VERSION ""

NS_ :

BS_:

BU_: BCM BSM DIAG_TEST ECM EPS IPC MTA ORC PAM

BO_ 1765 XcpSlave: 8 EPS
 SG_ XcpSlave : 7|64@0+ (1,0) [0|4294967295] ""  DIAG_TEST

BO_ 1685 XcpMaster: 8 DIAG_TEST
 SG_ XcpMaster : 7|64@0+ (1,0) [0|4294967295] ""  EPS

BO_ 2033 GliwaSlave: 8 EPS
 SG_ GliwaSlave : 7|64@0+ (1,0) [0|4294967295] ""  DIAG_TEST

BO_ 2032 GliwaMaster: 8 DIAG_TEST
 SG_ GliwaMaster : 7|64@0+ (1,0) [0|4294967295] ""  EPS

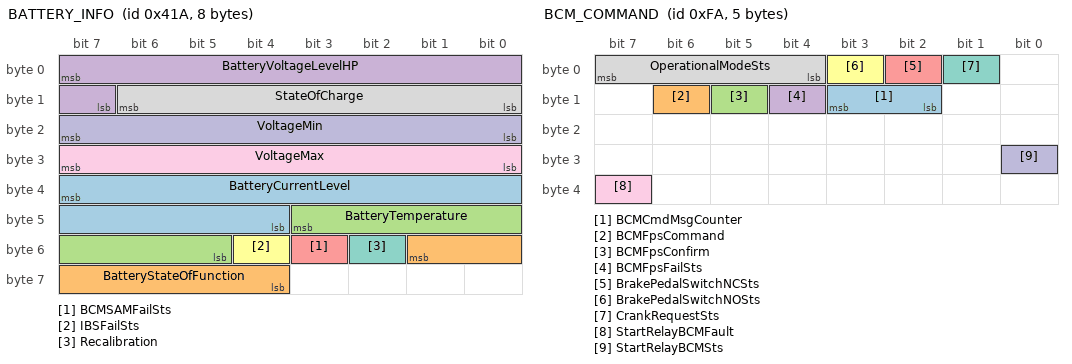
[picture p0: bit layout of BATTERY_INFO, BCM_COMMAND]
BO_ 1050 BATTERY_INFO: 8 BCM
 SG_ BatteryCurrentLevel : 39|12@0+ (0.1,-250) [0|0] "A"  ECM
 SG_ BatteryStateOfFunction : 49|6@0+ (0.09375,6) [6|11.90625] "V"  ECM
 SG_ BatteryTemperature : 43|7@0+ (1,-30) [0|0] "°C"  ECM
 SG_ BatteryVoltageLevelHP : 7|9@0+ (0.025,4) [0|0] "Volt"  ECM
 SG_ BCMSAMFailSts : 51|1@0+ (1,0) [0|0] "-"  ECM
 SG_ IBSFailSts : 52|1@0+ (1,0) [0|0] "-"  ECM
 SG_ Recalibration : 50|1@0+ (1,0) [0|1] ""  ECM
 SG_ StateOfCharge : 14|7@0+ (1,0) [0|0] "%"  ECM
 SG_ VoltageMax : 31|8@0+ (0.025,10.6) [0|0] "Volt"  ECM
 SG_ VoltageMin : 23|8@0+ (0.025,10.6) [0|0] "Volt"  ECM

BO_ 250 BCM_COMMAND: 5 BCM
 SG_ BCMCmdMsgCounter : 11|2@0+ (1,0) [0|3] "-"  BSM,ECM,MTA
 SG_ BCMFpsCommand : 14|1@0+ (1,0) [0|1] "-"  ECM
 SG_ BCMFpsConfirm : 13|1@0+ (1,0) [0|1] "-"  ECM
 SG_ BCMFpsFailSts : 12|1@0+ (1,0) [0|1] "-"  ECM
 SG_ BrakePedalSwitchNCSts : 2|1@0+ (1,0) [0|1] "-"  BSM,ECM,MTA
 SG_ BrakePedalSwitchNOSts : 3|1@0+ (1,0) [0|1] "-"  BSM,ECM,MTA
 SG_ CrankRequestSts : 1|1@0+ (1,0) [0|1] "-"  ECM
 SG_ OperationalModeSts : 7|4@0+ (1,0) [0|15] ""  BSM,ECM,EPS,IPC,MTA,PAM
 SG_ StartRelayBCMFault : 39|1@0+ (1,0) [0|1] ""  ECM
 SG_ StartRelayBCMSts : 24|1@0+ (1,0) [0|1] ""  ECM

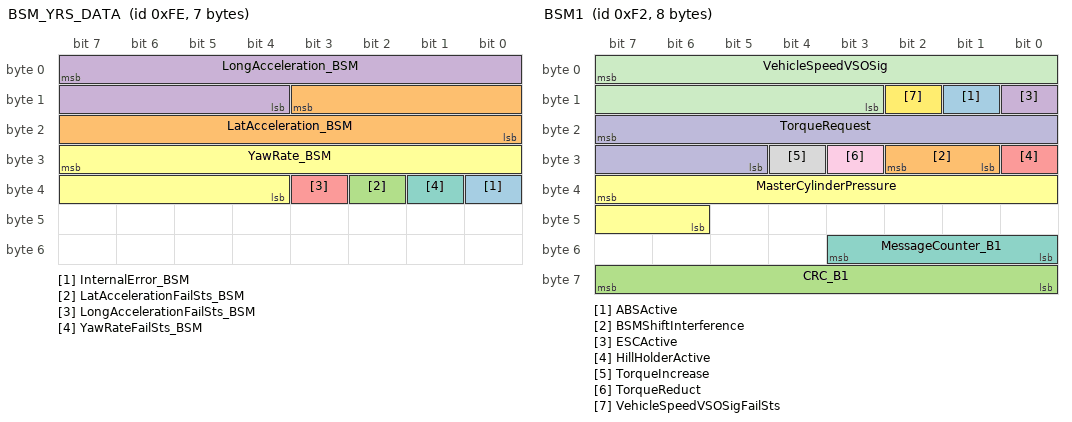
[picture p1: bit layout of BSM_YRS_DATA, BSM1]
BO_ 254 BSM_YRS_DATA: 7 BSM
 SG_ InternalError_BSM : 32|1@0+ (1,0) [0|1] "-" Vector__XXX
 SG_ LatAcceleration_BSM : 11|12@0+ (0.02,-40.96) [-40.96|40.92] "m/s^2"  MTA
 SG_ LatAccelerationFailSts_BSM : 34|1@0+ (1,0) [0|3] "-"  MTA
 SG_ LongAcceleration_BSM : 7|12@0+ (0.02,-40.96) [-40.96|40.92] "m/s^2"  MTA
 SG_ LongAccelerationFailSts_BSM : 35|1@0+ (1,0) [0|3] "-"  MTA
 SG_ YawRate_BSM : 31|12@0+ (0.08,-163.84) [-163.84|163.68] "deg/s" Vector__XXX
 SG_ YawRateFailSts_BSM : 33|1@0+ (1,0) [0|3] "-" Vector__XXX

BO_ 242 BSM1: 8 BSM
 SG_ ABSActive : 9|1@0+ (1,0) [0|1] ""  MTA
 SG_ BSMShiftInterference : 26|2@0+ (1,0) [0|1] ""  MTA
 SG_ CRC_B1 : 63|8@0+ (1,0) [0|255] ""  ECM,EPS
 SG_ ESCActive : 8|1@0+ (1,0) [0|1] ""  MTA
 SG_ HillHolderActive : 24|1@0+ (1,0) [0|0] ""  BCM,ECM,MTA
 SG_ MasterCylinderPressure : 39|10@0+ (0.25,0) [0|200] "bar"  ECM,MTA
 SG_ MessageCounter_B1 : 51|4@0+ (1,0) [0|15] ""  ECM,EPS
 SG_ TorqueIncrease : 28|1@0+ (1,0) [0|1] ""  ECM
 SG_ TorqueReduct : 27|1@0+ (1,0) [0|1] ""  ECM
 SG_ TorqueRequest : 23|11@0+ (1,-500) [-500|1546] ""  ECM
 SG_ VehicleSpeedVSOSig : 7|13@0+ (0.0625,0) [0|511.9375] "Km/h"  BCM,ECM,EPS,IPC,MTA,ORC,PAM
 SG_ VehicleSpeedVSOSigFailSts : 10|1@0+ (1,0) [0|1] ""  BCM,ECM,EPS,IPC,MTA,ORC,PAM

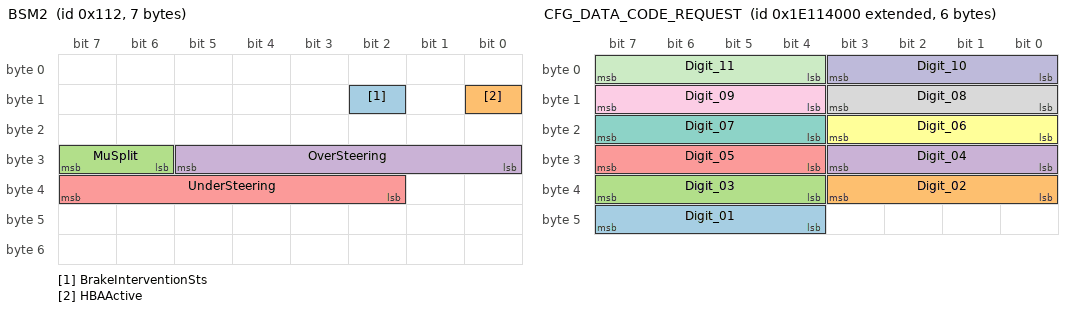
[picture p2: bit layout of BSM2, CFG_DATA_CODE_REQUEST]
BO_ 274 BSM2: 7 BSM
 SG_ BrakeInterventionSts : 10|1@0+ (1,0) [0|1] ""  MTA
 SG_ HBAActive : 8|1@0+ (1,0) [0|0] "" Vector__XXX
 SG_ MuSplit : 31|2@0+ (1,0) [0|1] "" Vector__XXX
 SG_ OverSteering : 29|6@0+ (2,0) [0|62] "%" Vector__XXX
 SG_ UnderSteering : 39|6@0+ (2,0) [0|62] "%" Vector__XXX

BO_ 2651930624 CFG_DATA_CODE_REQUEST: 6 BCM
 SG_ Digit_01 : 47|4@0+ (1,0) [0|15] ""  BSM,ECM,EPS,IPC,MTA,ORC,PAM
 SG_ Digit_02 : 35|4@0+ (1,0) [0|15] ""  BSM,ECM,EPS,IPC,MTA,ORC,PAM
 SG_ Digit_03 : 39|4@0+ (1,0) [0|15] ""  BSM,ECM,EPS,IPC,MTA,ORC,PAM
 SG_ Digit_04 : 27|4@0+ (1,0) [0|15] ""  BSM,ECM,EPS,IPC,MTA,ORC,PAM
 SG_ Digit_05 : 31|4@0+ (1,0) [0|15] ""  BSM,ECM,EPS,IPC,MTA,ORC,PAM
 SG_ Digit_06 : 19|4@0+ (1,0) [0|15] ""  BSM,ECM,EPS,IPC,MTA,ORC,PAM
 SG_ Digit_07 : 23|4@0+ (1,0) [0|15] ""  BSM,ECM,EPS,IPC,MTA,ORC,PAM
 SG_ Digit_08 : 11|4@0+ (1,0) [0|15] ""  BSM,ECM,EPS,IPC,MTA,ORC,PAM
 SG_ Digit_09 : 15|4@0+ (1,0) [0|15] ""  BSM,ECM,EPS,IPC,MTA,ORC,PAM
 SG_ Digit_10 : 3|4@0+ (1,0) [0|15] ""  BSM,ECM,EPS,IPC,MTA,ORC,PAM
 SG_ Digit_11 : 7|4@0+ (1,0) [0|15] ""  BSM,ECM,EPS,IPC,MTA,ORC,PAM

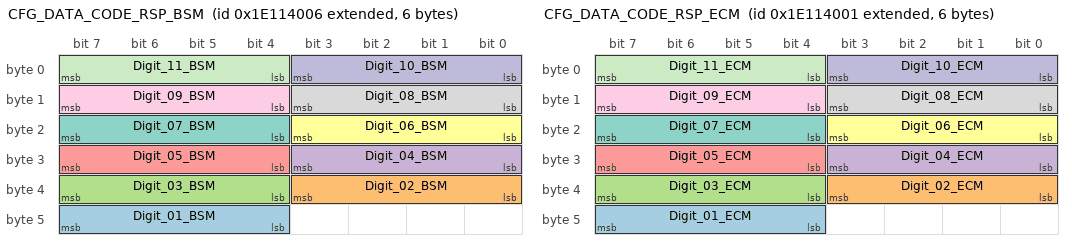
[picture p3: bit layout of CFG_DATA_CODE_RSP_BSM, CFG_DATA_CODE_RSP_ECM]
BO_ 2651930630 CFG_DATA_CODE_RSP_BSM: 6 BSM
 SG_ Digit_01_BSM : 47|4@0+ (1,0) [0|15] "-"  BCM
 SG_ Digit_02_BSM : 35|4@0+ (1,0) [0|15] "-"  BCM
 SG_ Digit_03_BSM : 39|4@0+ (1,0) [0|15] "-"  BCM
 SG_ Digit_04_BSM : 27|4@0+ (1,0) [0|15] "-"  BCM
 SG_ Digit_05_BSM : 31|4@0+ (1,0) [0|15] "-"  BCM
 SG_ Digit_06_BSM : 19|4@0+ (1,0) [0|15] "-"  BCM
 SG_ Digit_07_BSM : 23|4@0+ (1,0) [0|15] "-"  BCM
 SG_ Digit_08_BSM : 11|4@0+ (1,0) [0|15] "-"  BCM
 SG_ Digit_09_BSM : 15|4@0+ (1,0) [0|15] "-"  BCM
 SG_ Digit_10_BSM : 3|4@0+ (1,0) [0|15] "-"  BCM
 SG_ Digit_11_BSM : 7|4@0+ (1,0) [0|15] "-"  BCM

BO_ 2651930625 CFG_DATA_CODE_RSP_ECM: 6 ECM
 SG_ Digit_01_ECM : 47|4@0+ (1,0) [0|15] "-"  BCM
 SG_ Digit_02_ECM : 35|4@0+ (1,0) [0|15] "-"  BCM
 SG_ Digit_03_ECM : 39|4@0+ (1,0) [0|15] "-"  BCM
 SG_ Digit_04_ECM : 27|4@0+ (1,0) [0|15] "-"  BCM
 SG_ Digit_05_ECM : 31|4@0+ (1,0) [0|15] "-"  BCM
 SG_ Digit_06_ECM : 19|4@0+ (1,0) [0|15] "-"  BCM
 SG_ Digit_07_ECM : 23|4@0+ (1,0) [0|15] "-"  BCM
 SG_ Digit_08_ECM : 11|4@0+ (1,0) [0|15] "-"  BCM
 SG_ Digit_09_ECM : 15|4@0+ (1,0) [0|15] "-"  BCM
 SG_ Digit_10_ECM : 3|4@0+ (1,0) [0|15] "-"  BCM
 SG_ Digit_11_ECM : 7|4@0+ (1,0) [0|15] "-"  BCM

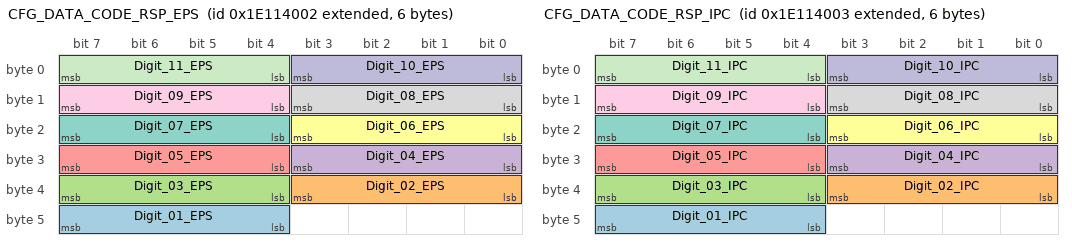
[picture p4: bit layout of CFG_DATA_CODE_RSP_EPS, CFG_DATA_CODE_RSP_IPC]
BO_ 2651930626 CFG_DATA_CODE_RSP_EPS: 6 EPS
 SG_ Digit_01_EPS : 47|4@0+ (1,0) [0|15] "-"  BCM
 SG_ Digit_02_EPS : 35|4@0+ (1,0) [0|15] "-"  BCM
 SG_ Digit_03_EPS : 39|4@0+ (1,0) [0|15] "-"  BCM
 SG_ Digit_04_EPS : 27|4@0+ (1,0) [0|15] "-"  BCM
 SG_ Digit_05_EPS : 31|4@0+ (1,0) [0|15] "-"  BCM
 SG_ Digit_06_EPS : 19|4@0+ (1,0) [0|15] "-"  BCM
 SG_ Digit_07_EPS : 23|4@0+ (1,0) [0|15] "-"  BCM
 SG_ Digit_08_EPS : 11|4@0+ (1,0) [0|15] "-"  BCM
 SG_ Digit_09_EPS : 15|4@0+ (1,0) [0|15] "-"  BCM
 SG_ Digit_10_EPS : 3|4@0+ (1,0) [0|15] "-"  BCM
 SG_ Digit_11_EPS : 7|4@0+ (1,0) [0|15] "-"  BCM

BO_ 2651930627 CFG_DATA_CODE_RSP_IPC: 6 IPC
 SG_ Digit_01_IPC : 47|4@0+ (1,0) [0|15] "-"  BCM
 SG_ Digit_02_IPC : 35|4@0+ (1,0) [0|15] "-"  BCM
 SG_ Digit_03_IPC : 39|4@0+ (1,0) [0|15] "-"  BCM
 SG_ Digit_04_IPC : 27|4@0+ (1,0) [0|15] "-"  BCM
 SG_ Digit_05_IPC : 31|4@0+ (1,0) [0|15] "-"  BCM
 SG_ Digit_06_IPC : 19|4@0+ (1,0) [0|15] "-"  BCM
 SG_ Digit_07_IPC : 23|4@0+ (1,0) [0|15] "-"  BCM
 SG_ Digit_08_IPC : 11|4@0+ (1,0) [0|15] "-"  BCM
 SG_ Digit_09_IPC : 15|4@0+ (1,0) [0|15] "-"  BCM
 SG_ Digit_10_IPC : 3|4@0+ (1,0) [0|15] "-"  BCM
 SG_ Digit_11_IPC : 7|4@0+ (1,0) [0|15] "-"  BCM

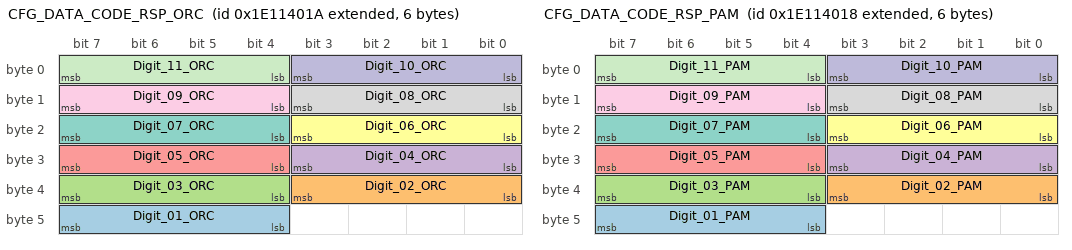
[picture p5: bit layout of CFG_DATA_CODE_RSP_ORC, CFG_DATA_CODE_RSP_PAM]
BO_ 2651930650 CFG_DATA_CODE_RSP_ORC: 6 ORC
 SG_ Digit_01_ORC : 47|4@0+ (1,0) [0|15] "-"  BCM
 SG_ Digit_02_ORC : 35|4@0+ (1,0) [0|15] "-"  BCM
 SG_ Digit_03_ORC : 39|4@0+ (1,0) [0|15] "-"  BCM
 SG_ Digit_04_ORC : 27|4@0+ (1,0) [0|15] "-"  BCM
 SG_ Digit_05_ORC : 31|4@0+ (1,0) [0|15] "-"  BCM
 SG_ Digit_06_ORC : 19|4@0+ (1,0) [0|15] "-"  BCM
 SG_ Digit_07_ORC : 23|4@0+ (1,0) [0|15] "-"  BCM
 SG_ Digit_08_ORC : 11|4@0+ (1,0) [0|15] "-"  BCM
 SG_ Digit_09_ORC : 15|4@0+ (1,0) [0|15] "-"  BCM
 SG_ Digit_10_ORC : 3|4@0+ (1,0) [0|15] "-"  BCM
 SG_ Digit_11_ORC : 7|4@0+ (1,0) [0|15] "-"  BCM

BO_ 2651930648 CFG_DATA_CODE_RSP_PAM: 6 PAM
 SG_ Digit_01_PAM : 47|4@0+ (1,0) [0|15] "-"  BCM
 SG_ Digit_02_PAM : 35|4@0+ (1,0) [0|15] "-"  BCM
 SG_ Digit_03_PAM : 39|4@0+ (1,0) [0|15] "-"  BCM
 SG_ Digit_04_PAM : 27|4@0+ (1,0) [0|15] "-"  BCM
 SG_ Digit_05_PAM : 31|4@0+ (1,0) [0|15] "-"  BCM
 SG_ Digit_06_PAM : 19|4@0+ (1,0) [0|15] "-"  BCM
 SG_ Digit_07_PAM : 23|4@0+ (1,0) [0|15] "-"  BCM
 SG_ Digit_08_PAM : 11|4@0+ (1,0) [0|15] "-"  BCM
 SG_ Digit_09_PAM : 15|4@0+ (1,0) [0|15] "-"  BCM
 SG_ Digit_10_PAM : 3|4@0+ (1,0) [0|15] "-"  BCM
 SG_ Digit_11_PAM : 7|4@0+ (1,0) [0|15] "-"  BCM

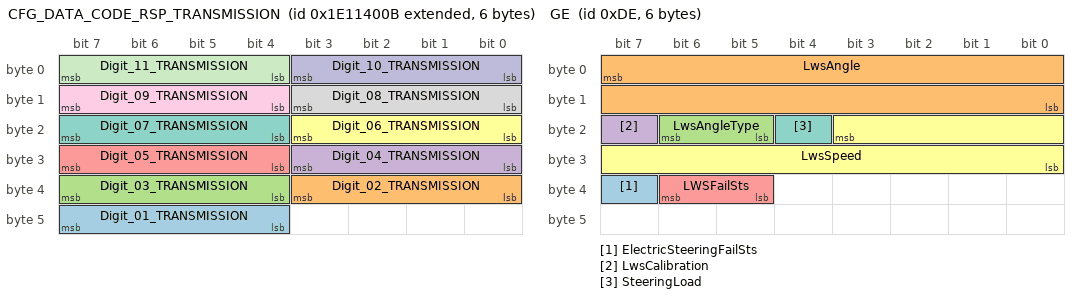
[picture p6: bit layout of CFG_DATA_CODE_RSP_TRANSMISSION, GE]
BO_ 2651930635 CFG_DATA_CODE_RSP_TRANSMISSION: 6 MTA
 SG_ Digit_01_TRANSMISSION : 47|4@0+ (1,0) [0|15] "-"  BCM
 SG_ Digit_02_TRANSMISSION : 35|4@0+ (1,0) [0|15] "-"  BCM
 SG_ Digit_03_TRANSMISSION : 39|4@0+ (1,0) [0|15] "-"  BCM
 SG_ Digit_04_TRANSMISSION : 27|4@0+ (1,0) [0|15] "-"  BCM
 SG_ Digit_05_TRANSMISSION : 31|4@0+ (1,0) [0|15] "-"  BCM
 SG_ Digit_06_TRANSMISSION : 19|4@0+ (1,0) [0|15] "-"  BCM
 SG_ Digit_07_TRANSMISSION : 23|4@0+ (1,0) [0|15] "-"  BCM
 SG_ Digit_08_TRANSMISSION : 11|4@0+ (1,0) [0|15] "-"  BCM
 SG_ Digit_09_TRANSMISSION : 15|4@0+ (1,0) [0|15] "-"  BCM
 SG_ Digit_10_TRANSMISSION : 3|4@0+ (1,0) [0|15] "-"  BCM
 SG_ Digit_11_TRANSMISSION : 7|4@0+ (1,0) [0|15] "-"  BCM

BO_ 2564440308 DIAGNOSTIC_REQUEST_BCM: 8 DIAG_TEST
 SG_ N_PDU : 7|64@0+ (1,0) [0|0] ""  BCM

BO_ 2564434164 DIAGNOSTIC_REQUEST_BSM: 8 DIAG_TEST
 SG_ N_PDU : 7|64@0+ (1,0) [0|0] ""  BSM

BO_ 2564428020 DIAGNOSTIC_REQUEST_ECM: 8 DIAG_TEST
 SG_ N_PDU : 7|64@0+ (1,0) [0|0] ""  ECM

BO_ 2564428017 DIAGNOSTIC_REQUEST_ECM_OBD: 8 DIAG_TEST
 SG_ N_PDU : 7|64@0+ (1,0) [0|0] ""  ECM

BO_ 2564436212 DIAGNOSTIC_REQUEST_EPS: 8 DIAG_TEST
 SG_ N_PDU : 7|64@0+ (1,0) [0|0] ""  EPS

BO_ 2564502513 DIAGNOSTIC_REQUEST_FUNC_OBD: 8 DIAG_TEST
 SG_ N_PDU : 7|64@0+ (1,0) [0|0] ""  ECM

BO_ 2564554484 DIAGNOSTIC_REQUEST_FUNCTIONAL: 8 DIAG_TEST
 SG_ N_PDU : 7|64@0+ (1,0) [0|0] ""  BCM,BSM,ECM,EPS,IPC,MTA,ORC,PAM

BO_ 2564448500 DIAGNOSTIC_REQUEST_IPC: 8 DIAG_TEST
 SG_ N_PDU : 7|64@0+ (1,0) [0|0] "-"  IPC

BO_ 2564473076 DIAGNOSTIC_REQUEST_ORC: 8 DIAG_TEST
 SG_ N_PDU : 7|64@0+ (1,0) [0|0] ""  ORC

BO_ 2564464884 DIAGNOSTIC_REQUEST_PAM: 8 DIAG_TEST
 SG_ N_PDU : 7|64@0+ (1,0) [0|0] ""  PAM

BO_ 2564430068 DIAGNOSTIC_REQUEST_TRANSMISSION: 8 DIAG_TEST
 SG_ N_PDU : 7|64@0+ (1,0) [0|0] ""  MTA

BO_ 2564486208 DIAGNOSTIC_RESPONSE_BCM: 8 BCM
 SG_ N_PDU : 7|64@0+ (1,0) [0|0] ""  DIAG_TEST

BO_ 2564486184 DIAGNOSTIC_RESPONSE_BSM: 8 BSM
 SG_ N_PDU : 7|64@0+ (1,0) [0|0] ""  DIAG_TEST

BO_ 2564486160 DIAGNOSTIC_RESPONSE_ECM: 8 ECM
 SG_ N_PDU : 7|64@0+ (1,0) [0|0] ""  DIAG_TEST

BO_ 2564485392 DIAGNOSTIC_RESPONSE_ECM_OBD: 8 ECM
 SG_ N_PDU : 7|64@0+ (1,0) [0|0] ""  DIAG_TEST

BO_ 2564486192 DIAGNOSTIC_RESPONSE_EPS: 8 EPS
 SG_ N_PDU : 7|64@0+ (1,0) [0|0] ""  DIAG_TEST

BO_ 2564486240 DIAGNOSTIC_RESPONSE_IPC: 8 IPC
 SG_ N_PDU : 7|64@0+ (1,0) [0|0] "-"  DIAG_TEST

BO_ 2564486336 DIAGNOSTIC_RESPONSE_ORC: 8 ORC
 SG_ N_PDU : 7|64@0+ (1,0) [0|0] ""  DIAG_TEST

BO_ 2564486304 DIAGNOSTIC_RESPONSE_PAM: 8 PAM
 SG_ N_PDU : 7|64@0+ (1,0) [0|0] ""  DIAG_TEST

BO_ 2564486168 DIAGNOSTIC_RESPONSE_TRANSMISSION: 8 MTA
 SG_ N_PDU : 7|64@0+ (1,0) [0|0] ""  DIAG_TEST

BO_ 222 GE: 6 EPS
 SG_ ElectricSteeringFailSts : 39|1@0+ (1,0) [0|1] ""  BCM,IPC
 SG_ LwsAngle : 7|16@0+ (0.1,-720) [-720|720] "°"  BSM
 SG_ LwsAngleType : 22|2@0+ (1,0) [0|1] "-"  BSM
 SG_ LwsCalibration : 23|1@0+ (1,0) [0|1] "-"  BSM
 SG_ LWSFailSts : 38|2@0+ (1,0) [0|3] "-"  BSM
 SG_ LwsSpeed : 19|12@0+ (1,-2000) [0|0] "°/s" Vector__XXX
 SG_ SteeringLoad : 20|1@0+ (1,0) [0|1] "-" Vector__XXX

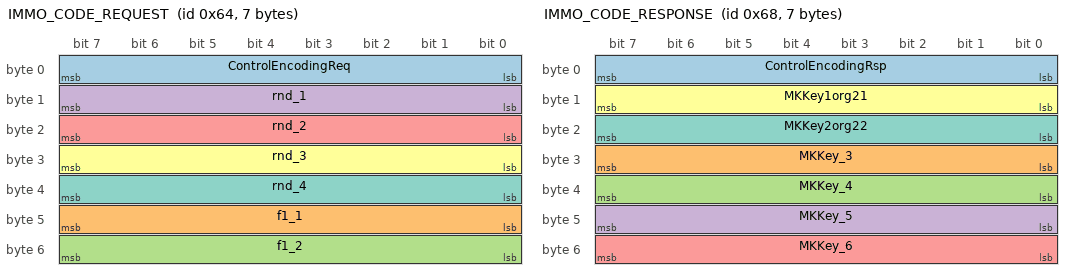
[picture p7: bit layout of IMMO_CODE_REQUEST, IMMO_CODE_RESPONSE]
BO_ 100 IMMO_CODE_REQUEST: 7 ECM
 SG_ ControlEncodingReq : 7|8@0+ (1,0) [0|255] "-"  BCM
 SG_ f1_1 : 47|8@0+ (1,0) [0|255] "-"  BCM
 SG_ f1_2 : 55|8@0+ (1,0) [0|255] "-"  BCM
 SG_ rnd_1 : 15|8@0+ (1,0) [0|255] "-"  BCM
 SG_ rnd_2 : 23|8@0+ (1,0) [0|255] "-"  BCM
 SG_ rnd_3 : 31|8@0+ (1,0) [0|255] "-"  BCM
 SG_ rnd_4 : 39|8@0+ (1,0) [0|255] "-"  BCM

BO_ 104 IMMO_CODE_RESPONSE: 7 BCM
 SG_ ControlEncodingRsp : 7|8@0+ (1,0) [0|255] "-"  ECM
 SG_ MKKey_3 : 31|8@0+ (1,0) [0|255] "-"  ECM
 SG_ MKKey_4 : 39|8@0+ (1,0) [0|255] "-"  ECM
 SG_ MKKey_5 : 47|8@0+ (1,0) [0|255] "-"  ECM
 SG_ MKKey_6 : 55|8@0+ (1,0) [0|255] "-"  ECM
 SG_ MKKey1org21 : 15|8@0+ (1,0) [0|255] "-"  ECM
 SG_ MKKey2org22 : 23|8@0+ (1,0) [0|255] "-"  ECM

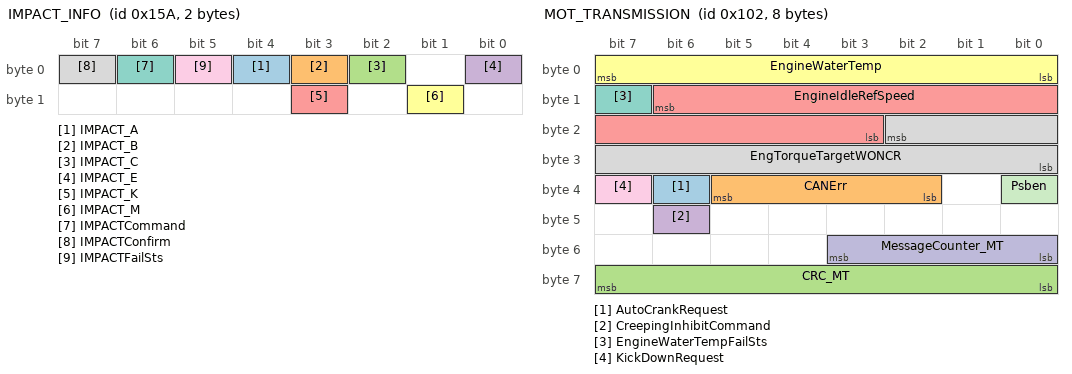
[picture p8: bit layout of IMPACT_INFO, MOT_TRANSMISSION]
BO_ 346 IMPACT_INFO: 2 ORC
 SG_ IMPACT_A : 4|1@0+ (1,0) [0|1] "" Vector__XXX
 SG_ IMPACT_B : 3|1@0+ (1,0) [0|1] "" Vector__XXX
 SG_ IMPACT_C : 2|1@0+ (1,0) [0|1] "" Vector__XXX
 SG_ IMPACT_E : 0|1@0+ (1,0) [0|1] "" Vector__XXX
 SG_ IMPACT_K : 11|1@0+ (1,0) [0|1] "" Vector__XXX
 SG_ IMPACT_M : 9|1@0+ (1,0) [0|1] "" Vector__XXX
 SG_ IMPACTCommand : 6|1@0+ (1,0) [0|1] ""  BCM
 SG_ IMPACTConfirm : 7|1@0+ (1,0) [0|1] ""  BCM
 SG_ IMPACTFailSts : 5|1@0+ (1,0) [0|1] ""  BCM

BO_ 258 MOT_TRANSMISSION: 8 ECM
 SG_ AutoCrankRequest : 38|1@0+ (1,0) [0|1] "-"  MTA
 SG_ CANErr : 37|4@0+ (1,0) [0|15] "-"  MTA
 SG_ CRC_MT : 63|8@0+ (1,0) [0|255] "-"  MTA
 SG_ CreepingInhibitCommand : 46|1@0+ (1,0) [0|1] ""  MTA
 SG_ EngineIdleRefSpeed : 14|12@0+ (1,0) [0|4094] "1/min"  MTA
 SG_ EngineWaterTemp : 7|8@0+ (1,-40) [-40|215] "°C"  BCM
 SG_ EngineWaterTempFailSts : 15|1@0+ (1,0) [0|1] "-"  BCM
 SG_ EngTorqueTargetWONCR : 18|11@0+ (1,-500) [-500|1546] "Nm"  MTA
 SG_ KickDownRequest : 39|1@0+ (1,0) [0|1] "-" Vector__XXX
 SG_ MessageCounter_MT : 51|4@0+ (1,0) [0|15] "-"  MTA
 SG_ Psben : 32|1@0+ (1,0) [0|1] "-" Vector__XXX

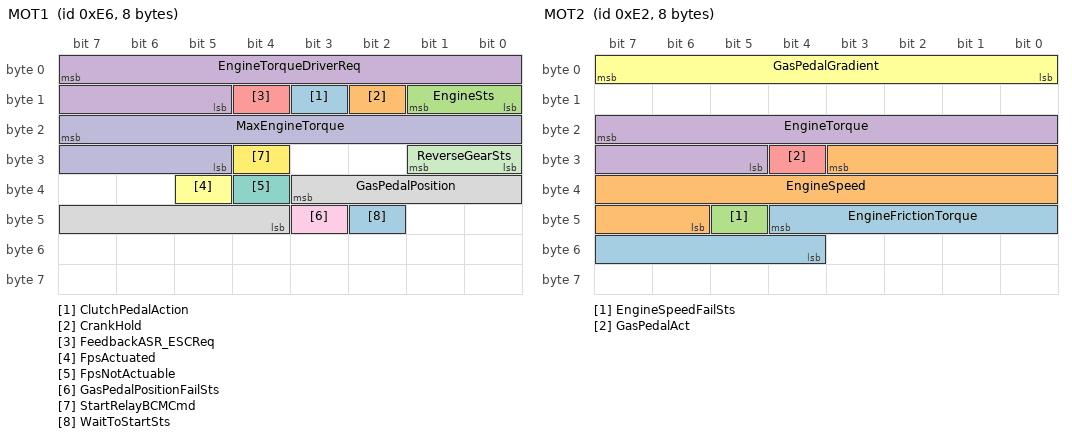
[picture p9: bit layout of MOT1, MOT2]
BO_ 230 MOT1: 8 ECM
 SG_ ClutchPedalAction : 11|1@0+ (1,0) [0|1] "-"  BCM,BSM
 SG_ CrankHold : 10|1@0+ (1,0) [0|1] "-"  BCM
 SG_ EngineSts : 9|2@0+ (1,0) [0|3] "-"  BCM,BSM,EPS,IPC,MTA,ORC,PAM
 SG_ EngineTorqueDriverReq : 7|11@0+ (1,-500) [-500|1546] "Nm"  BSM,MTA
 SG_ FeedbackASR_ESCReq : 12|1@0+ (1,0) [0|1] "-"  BSM
 SG_ FpsActuated : 37|1@0+ (1,0) [0|1] ""  BCM,IPC
 SG_ FpsNotActuable : 36|1@0+ (1,0) [0|1] "-"  BCM
 SG_ GasPedalPosition : 35|8@0+ (0.392,0) [0|99.568] "%"  BSM,MTA
 SG_ GasPedalPositionFailSts : 43|1@0+ (1,0) [0|1] "-"  BSM,MTA
 SG_ MaxEngineTorque : 23|11@0+ (1,-500) [-500|1546] "Nm"  MTA
 SG_ ReverseGearSts : 25|2@0+ (1,0) [0|3] "-"  BCM,BSM,IPC,PAM
 SG_ StartRelayBCMCmd : 28|1@0+ (1,0) [0|1] "-"  BCM
 SG_ WaitToStartSts : 42|1@0+ (1,0) [0|1] "-"  IPC

BO_ 226 MOT2: 8 ECM
 SG_ EngineFrictionTorque : 44|9@0+ (1,0) [0|510] "Nm"  BSM,MTA
 SG_ EngineSpeed : 27|14@0+ (1,0) [0|16382] "1/min"  BCM,BSM,IPC,MTA
 SG_ EngineSpeedFailSts : 45|1@0+ (1,0) [0|1] ""  BCM,BSM,IPC
 SG_ EngineTorque : 23|11@0+ (1,-500) [-500|1546] "Nm"  BSM,MTA
 SG_ GasPedalAct : 28|1@0+ (1,0) [0|1] "-" Vector__XXX
 SG_ GasPedalGradient : 7|8@0+ (0.195,-25) [-25|24.53] "% /10ms" Vector__XXX

CM_ "Project_3271_ProjectStandard_C-CAN [07339]";
CM_ SG_ 1050 BatteryCurrentLevel "This signal indicates the battery current.";
CM_ SG_ 1050 BatteryStateOfFunction "This signal indicates the lowest battery voltage value at the next automatic restart";
CM_ SG_ 1050 BatteryTemperature "This signal indicates the battery temperature.";
CM_ SG_ 1050 BatteryVoltageLevelHP "This signal indicates the battery voltage.";
CM_ SG_ 1050 BCMSAMFailSts "This signal indicates a fault present in BCM related to the SAM strategy.";
CM_ SG_ 1050 IBSFailSts "This signal indicates a fault present in the IBS sensor.";
CM_ SG_ 1050 StateOfCharge "This signal indicates the battery state of charge.";
CM_ SG_ 1050 VoltageMax "This signal indicates the maximum regulation voltage permitted by BCM in the SAM strategy.";
CM_ SG_ 1050 VoltageMin "This signal indicates the minimum regulation voltage permitted by BCM in the SAM strategy.";
CM_ SG_ 250 BCMCmdMsgCounter "This signal is a counter used for safety checks strategies. This counter (values between 0 and 3) is incremented of 1 (one) unit at each frame transmission (0, 1, 2, 3, 0, 1, 2, 3, 0, 1, 2, ?).";
CM_ SG_ 250 BCMFpsCommand "The signal is used to command the FPS strategy actuation";
CM_ SG_ 250 BCMFpsConfirm "The signal is used to confirm the FPS strategy command";
CM_ SG_ 250 BCMFpsFailSts "This signal is used to give information of a fault present on the FPS sensing device.";
CM_ SG_ 250 BrakePedalSwitchNCSts "It is the Redundant Brake Switch (Normally Closed) position status, acquired by BCM and transmitted on CAN.";
CM_ SG_ 250 BrakePedalSwitchNOSts "It is the Brake Light Switch (Normally Open) position status, acquired by BCM and transmitted on CAN.";
CM_ SG_ 250 CrankRequestSts "This signal indicates the starter activation request (KL50 information)";
CM_ SG_ 250 StartRelayBCMFault "BCM starter relay fault detected";
CM_ SG_ 250 StartRelayBCMSts "BCM starter relay status; [1] = ON";
CM_ SG_ 254 InternalError_BSM "This signal indicates if an internal error has been processed";
CM_ SG_ 254 LatAcceleration_BSM "This signal indicates the Lateral Acceleration Value";
CM_ SG_ 254 LatAccelerationFailSts_BSM "This signal indicates the status of Lateral Acceleration Signal";
CM_ SG_ 254 LongAcceleration_BSM "This signal indicates the Longitudinal Acceleration Value";
CM_ SG_ 254 LongAccelerationFailSts_BSM "This signal indicates the status of Longitudinal acceleration signal";
CM_ SG_ 254 YawRate_BSM "This signal indicates the Yaw Rate Value";
CM_ SG_ 254 YawRateFailSts_BSM "This signal indicates the Status of Yaw Rate Signal";
CM_ SG_ 242 ABSActive "This signal is set to Active when the ABS functionality is active.";
CM_ SG_ 242 BSMShiftInterference "With this signal the BSMcan ask to Automatic/Robotic gearbox to prohibits the gear change during ASR/ESC manoeuvre.This signal is only available on ESC variant";
CM_ SG_ 242 CRC_B1 "CRC according to SAE J1850 standard that has to be calculated from bit 63 to bit 8 at each frame transmission.";
CM_ SG_ 242 ESCActive "This signal is set to Active when the brake intervention by ESC is active.";
CM_ SG_ 242 HillHolderActive "This signal is set to \"active\" when HH  functionality is acting.";
CM_ SG_ 242 MasterCylinderPressure "This signal indicates the unfiltered sensor signal of the Master Cylinder Pressure. This signal is only available on ESC variant";
CM_ SG_ 242 MessageCounter_B1 "This signal is a counter used for safety checks strategies. This counter is incremented of 1 (one) unit at each frame transmission.";
CM_ SG_ 242 VehicleSpeedVSOSig "It is the average vehicle speed calculated.";
CM_ SG_ 242 VehicleSpeedVSOSigFailSts "It is the average vehicle speed fail status.";
CM_ SG_ 274 BrakeInterventionSts "This signal is ?active? when the brake intervention is due to ESC, ASR, ACC systems and ?not active? when the brake intervention is due to the driver.";
CM_ SG_ 274 HBAActive "This signal is set to \"active\" when HBA functionality is acting.";
CM_ SG_ 274 MuSplit "This signal indicates if the MuSplit functionality is activated.";
CM_ SG_ 274 OverSteering "It is a percentage value that indicates the Oversteer vehicle tendency. When this value is set to 100%, ESC  is expected to start controlling.";
CM_ SG_ 274 UnderSteering "It is a percentage value that indicates the Understeer vehicle tendency. When this value is set to 100%, ESC  is expected to start controlling.";
CM_ SG_ 2564440308 N_PDU "This signal is used for diagnostic purposes";
CM_ SG_ 2564434164 N_PDU "This signal is used for diagnostic purposes";
CM_ SG_ 2564428020 N_PDU "This signal is used for diagnostic purposes";
CM_ SG_ 2564428017 N_PDU "This signal is used for diagnostic purposes";
CM_ SG_ 2564436212 N_PDU "This signal is used for diagnostic purposes";
CM_ SG_ 2564502513 N_PDU "This signal is used for diagnostic purposes";
CM_ SG_ 2564554484 N_PDU "This signal is used for diagnostic purposes";
CM_ SG_ 2564448500 N_PDU "-";
CM_ SG_ 2564473076 N_PDU "This signal is used for diagnostic purposes";
CM_ SG_ 2564464884 N_PDU "This signal is used for diagnostic purposes";
CM_ SG_ 2564430068 N_PDU "This signal is used for diagnostic purposes";
CM_ SG_ 2564486208 N_PDU "This signal is used for diagnostic purposes";
CM_ SG_ 2564486184 N_PDU "This signal is used for diagnostic purposes";
CM_ SG_ 2564486160 N_PDU "This signal is used for diagnostic purposes";
CM_ SG_ 2564485392 N_PDU "This signal is used for diagnostic purposes";
CM_ SG_ 2564486192 N_PDU "This signal is used for diagnostic purposes";
CM_ SG_ 2564486240 N_PDU "-";
CM_ SG_ 2564486336 N_PDU "This signal is used for diagnostic purposes";
CM_ SG_ 2564486304 N_PDU "This signal is used for diagnostic purposes";
CM_ SG_ 2564486168 N_PDU "This signal is used for diagnostic purposes";
CM_ SG_ 222 ElectricSteeringFailSts "It indicates if system EPS has an internal fault.";
CM_ SG_ 222 LwsAngle "This signal indicates the steering angle value, counterclockwise positive.";
CM_ SG_ 222 LwsAngleType "This signal indicates whether the angle sensor is absolute (all the possible turns/degrees) or not absolute (relative, torque only, etc.).";
CM_ SG_ 222 LwsCalibration "This signal indicates if the sensor has been calibrated and therefore the steering angle value is exported over Can.";
CM_ SG_ 222 LWSFailSts "This signal indicates steering angle export function failure status.";
CM_ SG_ 222 LwsSpeed "This signal indicates the steering speed value, counterclockwise positive.";
CM_ SG_ 222 SteeringLoad "This signal indicates the steering load, it shows when the current draw by  EPS  is above an adjustable parameter indicated in [A].";
CM_ SG_ 100 ControlEncodingReq "This signal is used for IMMO communication";
CM_ SG_ 100 f1_1 "This signal is used for IMMO communication";
CM_ SG_ 100 f1_2 "This signal is used for IMMO communication";
CM_ SG_ 100 rnd_1 "This signal is used for IMMO communication";
CM_ SG_ 100 rnd_2 "This signal is used for IMMO communication";
CM_ SG_ 100 rnd_3 "This signal is used for IMMO communication";
CM_ SG_ 100 rnd_4 "This signal is used for IMMO communication";
CM_ SG_ 104 ControlEncodingRsp "This signal is used for IMMO communication";
CM_ SG_ 104 MKKey_3 "This signal is used for IMMO communication";
CM_ SG_ 104 MKKey_4 "This signal is used for IMMO communication";
CM_ SG_ 104 MKKey_5 "This signal is used for IMMO communication";
CM_ SG_ 104 MKKey_6 "This signal is used for IMMO communication";
CM_ SG_ 104 MKKey1org21 "This signal is used for IMMO communication";
CM_ SG_ 104 MKKey2org22 "This signal is used for IMMO communication";
CM_ SG_ 346 IMPACT_A "Front Pretensioner Event";
CM_ SG_ 346 IMPACT_B "More Severe Rear Event";
CM_ SG_ 346 IMPACT_C "More Severe Frontal Event";
CM_ SG_ 346 IMPACT_E "Less Severe Rear Event";
CM_ SG_ 346 IMPACT_K "Driver Side Event";
CM_ SG_ 346 IMPACT_M "Passenger Side Event";
CM_ SG_ 346 IMPACTCommand "This signal is used to indicate that a crash happened";
CM_ SG_ 346 IMPACTConfirm "This signal is used to confirm that a crash happened";
CM_ SG_ 346 IMPACTFailSts "This signal is used to inform that an internal fault is present in the ORC";
CM_ SG_ 258 AutoCrankRequest "This signal is used to inform that a recrank is requested (by driver, BCM, ....)";
CM_ SG_ 258 CANErr "This is a feedback on the status of communication between ECM and DCTM, MTA or TCM.
There are 4 possible cases:
A. No CAN message received from DCTM, MTA or TCM (time out).
B. Unplausible message
C. Unplausible command
D. Not used.";
CM_ SG_ 258 CRC_MT "CRC according to SAE J1850 standard that has to be calculated from bit 63 to bit 8 at each frame transmission.";
CM_ SG_ 258 CreepingInhibitCommand "ECU reserved the right to inhibit creeping function in some particular conditions (internal ECM)";
CM_ SG_ 258 EngineIdleRefSpeed "This signal represents target of engine speed for the idle control function, at the end of dynamic transient conditions. It takes into account changes of idle speed due to temperature and auxiliary loads. It is updated even when the engine is ou(...)";
CM_ SG_ 258 EngineWaterTemp "It is the engine water temperature, measured through the related sensor.";
CM_ SG_ 258 EngineWaterTempFailSts "It is the Fail Status bit for EngineWaterTemp signal.";
CM_ SG_ 258 EngTorqueTargetWONCR "This is the indicated absolute torque target, not taking into account the request from the gearbox.";
CM_ SG_ 258 KickDownRequest "It is set to ?KD requested? whenever the Kick-Down condition is detected by the ECM";
CM_ SG_ 258 MessageCounter_MT "This signal is a counter used for safety checks strategies. This counter is incremented of 1 (one) unit at each frame transmission.";
CM_ SG_ 258 Psben "This signal indicate inhibition of gear shift down";
CM_ SG_ 230 ClutchPedalAction "The signal is active when the clutch pedal is pressed.   In case of vehicles equipped with Robotized or Automatic Transmission, the signal must be kept to the default value (that is pedal released).";
CM_ SG_ 230 CrankHold "Used by ECM to command an action to the BCM cranking relay during cranking phase";
CM_ SG_ 230 EngineSts "It is the current engine status";
CM_ SG_ 230 EngineTorqueDriverReq "This signal represents  torque demand due to the Driver (based on Gas pedal position) or to the Cruise Control Function (from internal cruise function or from ACC).";
CM_ SG_ 230 FeedbackASR_ESCReq "It is set to Not Valid, when the plausibility conditions about ASR / ESC torque request are not fulfilled . Nevertheless, it shall not be set to Not Valid, due to ValidData bits Not Valid transmitted from BSM.";
CM_ SG_ 230 FpsActuated "The signal informs about the activation of Safety Fuel Shut Off strategy";
CM_ SG_ 230 FpsNotActuable "This signal is used to inform that Safety Fuel Shut Off strategy is not actuable";
CM_ SG_ 230 GasPedalPosition "This signal represents actual gas pedal position ,virtual gas pedal position due to Cruise Control function (maximum value choice between the throttle opening requests coming from Driver and Cruise Control, internal function or ACC, if active) o(...)";
CM_ SG_ 230 GasPedalPositionFailSts "It indicates the fail status of the signal GasPedalPisition";
CM_ SG_ 230 MaxEngineTorque "This signal represents maximum indicated engine torque that would be available at full load, current engine speed, current environmental conditions. It takes into account possible limitations due to recovery strategies.";
CM_ SG_ 230 ReverseGearSts "It gives information of reverse gear status.";
CM_ SG_ 230 StartRelayBCMCmd "Used by ECM to command an action to the BCM cranking relay.";
CM_ SG_ 230 WaitToStartSts "The signal indicates the inhibition of the crank.";
CM_ SG_ 226 EngineFrictionTorque "Engine Friction Torque";
CM_ SG_ 226 EngineSpeed "It gives inforrmation on C-CAN network about  engine speed; it is based on the engine speed sensor.";
CM_ SG_ 226 EngineSpeedFailSts "It indicates the fail status of the signal EngineSpeed";
CM_ SG_ 226 EngineTorque "This signal represents engine torque expressed as flywheel torque. This torque can have only positive values. It is the actual value currently given by the engine";
CM_ SG_ 226 GasPedalAct "This signal is active when the gas pedal is pressed, that is when the gas pedal position is greater than the idle speed recognition threshold.";
CM_ SG_ 226 GasPedalGradient "This signal represents gradient of the gas pedal position over the transmission period.";
BA_DEF_ SG_  "GenSigStartValue" INT 0 2147483647;
BA_DEF_ SG_  "GenSigInactiveValue" INT 0 2147483647;
BA_DEF_ SG_  "GenSigSendType" ENUM  "NotUsed","OnWrite","OnWriteWithRepetition","OnChange","OnChangeWithRepetition","IfActive","IfActiveWithRepetition","NoSigSendType";
BA_DEF_ SG_  "GenSigTimeoutTime_BCM" INT 0 65535;
BA_DEF_ SG_  "GenSigTimeoutTime_BSM" INT 0 65535;
BA_DEF_ SG_  "GenSigTimeoutTime_DIAG_TEST" INT 0 65535;
BA_DEF_ SG_  "GenSigTimeoutTime_ECM" INT 0 65535;
BA_DEF_ SG_  "GenSigTimeoutTime_EPS" INT 0 65535;
BA_DEF_ SG_  "GenSigTimeoutTime_IPC" INT 0 65535;
BA_DEF_ SG_  "GenSigTimeoutTime_MTA" INT 0 65535;
BA_DEF_ SG_  "GenSigTimeoutTime_ORC" INT 0 65535;
BA_DEF_ SG_  "GenSigTimeoutTime_PAM" INT 0 65535;
BA_DEF_ BO_  "DiagRequest" ENUM  "No","Yes";
BA_DEF_ BO_  "Type" ENUM  "P","C","PE","COC","PE_Cntrl","E","E_Cntrl","OC","S","BAF","DC","EM","MM","-";
BA_DEF_ BO_  "DiagResponse" ENUM  "No","Yes";
BA_DEF_ BO_  "NmMessage" ENUM  "No","Yes";
BA_DEF_ BO_  "GenMsgSendType" ENUM  "Cyclic","NotUsed","NotUsed","NotUsed","NotUsed","NotUsed","NotUsed","NotUsed","NoMsgSendType";
BA_DEF_ BO_  "GenMsgNrOfRepetition" INT 0 255;
BA_DEF_ BO_  "GenMsgILSupport" ENUM  "No","Yes";
BA_DEF_ BO_  "GenMsgStartDelayTime" INT 0 65535;
BA_DEF_ BO_  "GenMsgCycleTimeFast" INT 0 65535;
BA_DEF_ BO_  "GenMsgCycleTime" INT 0 65535;
BA_DEF_ BO_  "GenMsgDelayTime" INT 0 65535;
BA_DEF_ BO_  "NmAsrMessage" ENUM  "No","Yes";
BA_DEF_ BO_  "DiagState" ENUM  "No","Yes";
BA_DEF_ BO_  "DiagConnection" HEX 0 65535;
BA_DEF_ BU_  "Description" STRING ;
BA_DEF_ BU_  "NmStationAddress" HEX 0 255;
BA_DEF_ BU_  "NmNode" ENUM  "No","Yes";
BA_DEF_ BU_  "NmNodeType" ENUM  "kMaster","kSlave15","kSlave30","none";
BA_DEF_ BU_  "NwmNodeType" ENUM  "kMaster","kSlave15","kSlave30","none";
BA_DEF_ BU_  "NmAsrNode" ENUM  "No","Yes";
BA_DEF_ BU_  "NmAsrCanMsgCycleOffset" INT 0 65535;
BA_DEF_ BU_  "NmAsrNodeIdentifier" HEX 0 255;
BA_DEF_ BU_  "IsOBDrelevant" ENUM  "No","Yes";
BA_DEF_ BU_  "NmAsrCanMsgReducedTime" INT 1 65535;
BA_DEF_  "Manufacturer" STRING ;
BA_DEF_  "NmType" STRING ;
BA_DEF_  "Baudrate" INT 0 1000000;
BA_DEF_  "DBName" STRING ;
BA_DEF_  "NmAsrTimeoutTime" INT 1 65535;
BA_DEF_  "NmAsrWaitBusSleepTime" INT 1 65535;
BA_DEF_  "NmAsrRepeatMessageTime" INT 1 65535;
BA_DEF_  "NmAsrMessageCount" INT 1 256;
BA_DEF_  "NmAsrBaseAddress" HEX 235487232 2147483647;
BA_DEF_  "NmAsrCanMsgCycleTime" INT 1 65535;
BA_DEF_  "Version" HEX 0 255;
BA_DEF_  "VersionWeek" INT 0 53;
BA_DEF_  "VersionYear" INT 0 99;
BA_DEF_DEF_  "GenSigStartValue" 0;
BA_DEF_DEF_  "GenSigInactiveValue" 0;
BA_DEF_DEF_  "GenSigSendType" "NoSigSendType";
BA_DEF_DEF_  "GenSigTimeoutTime_BCM" 2500;
BA_DEF_DEF_  "GenSigTimeoutTime_BSM" 2500;
BA_DEF_DEF_  "GenSigTimeoutTime_DIAG_TEST" 2500;
BA_DEF_DEF_  "GenSigTimeoutTime_ECM" 2500;
BA_DEF_DEF_  "GenSigTimeoutTime_EPS" 2500;
BA_DEF_DEF_  "GenSigTimeoutTime_IPC" 2500;
BA_DEF_DEF_  "GenSigTimeoutTime_MTA" 2500;
BA_DEF_DEF_  "GenSigTimeoutTime_ORC" 2500;
BA_DEF_DEF_  "GenSigTimeoutTime_PAM" 2500;
BA_DEF_DEF_  "DiagRequest" "No";
BA_DEF_DEF_  "Type" "-";
BA_DEF_DEF_  "DiagResponse" "No";
BA_DEF_DEF_  "NmMessage" "No";
BA_DEF_DEF_  "GenMsgSendType" "NoMsgSendType";
BA_DEF_DEF_  "GenMsgNrOfRepetition" 0;
BA_DEF_DEF_  "GenMsgILSupport" "No";
BA_DEF_DEF_  "GenMsgStartDelayTime" 0;
BA_DEF_DEF_  "GenMsgCycleTimeFast" 0;
BA_DEF_DEF_  "GenMsgCycleTime" 0;
BA_DEF_DEF_  "GenMsgDelayTime" 0;
BA_DEF_DEF_  "NmAsrMessage" "No";
BA_DEF_DEF_  "DiagState" "No";
BA_DEF_DEF_  "DiagConnection" 0;
BA_DEF_DEF_  "Description" "";
BA_DEF_DEF_  "NmStationAddress" 0;
BA_DEF_DEF_  "NmNode" "Yes";
BA_DEF_DEF_  "NmNodeType" "none";
BA_DEF_DEF_  "NwmNodeType" "none";
BA_DEF_DEF_  "NmAsrNode" "Yes";
BA_DEF_DEF_  "NmAsrCanMsgCycleOffset" 0;
BA_DEF_DEF_  "NmAsrNodeIdentifier" 0;
BA_DEF_DEF_  "IsOBDrelevant" "No";
BA_DEF_DEF_  "NmAsrCanMsgReducedTime" 100;
BA_DEF_DEF_  "Manufacturer" "Fiat";
BA_DEF_DEF_  "NmType" "";
BA_DEF_DEF_  "Baudrate" 500000;
BA_DEF_DEF_  "DBName" "CAN";
BA_DEF_DEF_  "NmAsrTimeoutTime" 1000;
BA_DEF_DEF_  "NmAsrWaitBusSleepTime" 750;
BA_DEF_DEF_  "NmAsrRepeatMessageTime" 800;
BA_DEF_DEF_  "NmAsrMessageCount" 256;
BA_DEF_DEF_  "NmAsrBaseAddress" 506724352;
BA_DEF_DEF_  "NmAsrCanMsgCycleTime" 200;
BA_DEF_DEF_  "Version" 160;
BA_DEF_DEF_  "VersionWeek" 1;
BA_DEF_DEF_  "VersionYear" 16;
BA_ "NmType" "NmAsr";
BA_ "NmAsrTimeoutTime" 8000;
BA_ "NmAsrWaitBusSleepTime" 1000;
BA_ "NmAsrRepeatMessageTime" 4500;
BA_ "NmAsrCanMsgCycleTime" 1000;
BA_ "DBName" "CCAN";
BA_ "Description" BU_ BCM "Body Control Module";
BA_ "NmNode" BU_ BCM 0;
BA_ "NmNodeType" BU_ BCM 0;
BA_ "NwmNodeType" BU_ BCM 0;
BA_ "NmAsrCanMsgReducedTime" BU_ BCM 550;
BA_ "Description" BU_ BSM "Braking System Module";
BA_ "NmStationAddress" BU_ BSM 6;
BA_ "NmNode" BU_ BSM 0;
BA_ "NmAsrCanMsgCycleOffset" BU_ BSM 20;
BA_ "NmAsrNodeIdentifier" BU_ BSM 6;
BA_ "NmAsrCanMsgReducedTime" BU_ BSM 650;
BA_ "Description" BU_ DIAG_TEST "N.A.";
BA_ "NmStationAddress" BU_ DIAG_TEST 255;
BA_ "NmNode" BU_ DIAG_TEST 0;
BA_ "NmAsrNode" BU_ DIAG_TEST 0;
BA_ "Description" BU_ ECM "Engine Control Module";
BA_ "NmStationAddress" BU_ ECM 1;
BA_ "NmNode" BU_ ECM 0;
BA_ "NmAsrCanMsgCycleOffset" BU_ ECM 30;
BA_ "NmAsrNodeIdentifier" BU_ ECM 1;
BA_ "IsOBDrelevant" BU_ ECM 1;
BA_ "NmAsrCanMsgReducedTime" BU_ ECM 700;
BA_ "Description" BU_ EPS "Electric Power Steering";
BA_ "NmStationAddress" BU_ EPS 2;
BA_ "NmNode" BU_ EPS 0;
BA_ "NmAsrCanMsgCycleOffset" BU_ EPS 60;
BA_ "NmAsrNodeIdentifier" BU_ EPS 2;
BA_ "NmAsrCanMsgReducedTime" BU_ EPS 850;
BA_ "Description" BU_ IPC "Instrument Panel Cluster";
BA_ "NmStationAddress" BU_ IPC 3;
BA_ "NmNode" BU_ IPC 0;
BA_ "NmNodeType" BU_ IPC 2;
BA_ "NwmNodeType" BU_ IPC 2;
BA_ "NmAsrCanMsgCycleOffset" BU_ IPC 10;
BA_ "NmAsrNodeIdentifier" BU_ IPC 3;
BA_ "NmAsrCanMsgReducedTime" BU_ IPC 600;
BA_ "Description" BU_ MTA "Manual Transmission Automated";
BA_ "NmStationAddress" BU_ MTA 11;
BA_ "NmNode" BU_ MTA 0;
BA_ "NmNodeType" BU_ MTA 2;
BA_ "NwmNodeType" BU_ MTA 2;
BA_ "NmAsrCanMsgCycleOffset" BU_ MTA 50;
BA_ "NmAsrNodeIdentifier" BU_ MTA 11;
BA_ "NmAsrCanMsgReducedTime" BU_ MTA 800;
BA_ "Description" BU_ ORC "Occupant Restraint Control";
BA_ "NmStationAddress" BU_ ORC 26;
BA_ "NmNode" BU_ ORC 0;
BA_ "NmAsrNode" BU_ ORC 0;
BA_ "NmAsrNodeIdentifier" BU_ ORC 26;
BA_ "Description" BU_ PAM "Parking Aid Module";
BA_ "NmStationAddress" BU_ PAM 24;
BA_ "NmNode" BU_ PAM 0;
BA_ "NmAsrNode" BU_ PAM 0;
BA_ "NmAsrNodeIdentifier" BU_ PAM 24;
BA_ "Type" BO_ 1050 1;
BA_ "GenMsgSendType" BO_ 1050 0;
BA_ "GenMsgILSupport" BO_ 1050 1;
BA_ "GenMsgCycleTime" BO_ 1050 100;
BA_ "Type" BO_ 250 1;
BA_ "GenMsgSendType" BO_ 250 0;
BA_ "GenMsgILSupport" BO_ 250 1;
BA_ "GenMsgStartDelayTime" BO_ 250 5;
BA_ "GenMsgCycleTime" BO_ 250 10;
BA_ "Type" BO_ 254 1;
BA_ "GenMsgSendType" BO_ 254 0;
BA_ "GenMsgILSupport" BO_ 254 1;
BA_ "GenMsgCycleTime" BO_ 254 10;
BA_ "Type" BO_ 242 1;
BA_ "GenMsgSendType" BO_ 242 0;
BA_ "GenMsgILSupport" BO_ 242 1;
BA_ "GenMsgCycleTime" BO_ 242 10;
BA_ "Type" BO_ 274 1;
BA_ "GenMsgSendType" BO_ 274 0;
BA_ "GenMsgILSupport" BO_ 274 1;
BA_ "GenMsgCycleTime" BO_ 274 10;
BA_ "Type" BO_ 2651930624 8;
BA_ "GenMsgILSupport" BO_ 2651930624 1;
BA_ "Type" BO_ 2651930630 11;
BA_ "GenMsgILSupport" BO_ 2651930630 1;
BA_ "Type" BO_ 2651930625 11;
BA_ "GenMsgILSupport" BO_ 2651930625 1;
BA_ "Type" BO_ 2651930626 11;
BA_ "GenMsgILSupport" BO_ 2651930626 1;
BA_ "Type" BO_ 2651930627 11;
BA_ "GenMsgILSupport" BO_ 2651930627 1;
BA_ "Type" BO_ 2651930650 11;
BA_ "GenMsgILSupport" BO_ 2651930650 1;
BA_ "Type" BO_ 2651930648 11;
BA_ "GenMsgILSupport" BO_ 2651930648 1;
BA_ "Type" BO_ 2651930635 11;
BA_ "GenMsgILSupport" BO_ 2651930635 1;
BA_ "DiagRequest" BO_ 2564440308 1;
BA_ "Type" BO_ 2564440308 8;
BA_ "DiagConnection" BO_ 2564440308 62528;
BA_ "DiagRequest" BO_ 2564434164 1;
BA_ "Type" BO_ 2564434164 8;
BA_ "DiagConnection" BO_ 2564434164 62504;
BA_ "DiagRequest" BO_ 2564428020 1;
BA_ "Type" BO_ 2564428020 8;
BA_ "DiagConnection" BO_ 2564428020 62480;
BA_ "DiagRequest" BO_ 2564428017 1;
BA_ "Type" BO_ 2564428017 8;
BA_ "DiagConnection" BO_ 2564428017 61712;
BA_ "DiagRequest" BO_ 2564436212 1;
BA_ "Type" BO_ 2564436212 8;
BA_ "DiagConnection" BO_ 2564436212 62512;
BA_ "Type" BO_ 2564502513 8;
BA_ "DiagState" BO_ 2564502513 1;
BA_ "DiagConnection" BO_ 2564502513 61747;
BA_ "Type" BO_ 2564554484 8;
BA_ "DiagState" BO_ 2564554484 1;
BA_ "DiagConnection" BO_ 2564554484 62718;
BA_ "DiagRequest" BO_ 2564448500 1;
BA_ "Type" BO_ 2564448500 8;
BA_ "DiagConnection" BO_ 2564448500 62560;
BA_ "DiagRequest" BO_ 2564473076 1;
BA_ "Type" BO_ 2564473076 8;
BA_ "DiagConnection" BO_ 2564473076 62656;
BA_ "DiagRequest" BO_ 2564464884 1;
BA_ "Type" BO_ 2564464884 8;
BA_ "DiagConnection" BO_ 2564464884 62624;
BA_ "DiagRequest" BO_ 2564430068 1;
BA_ "Type" BO_ 2564430068 8;
BA_ "DiagConnection" BO_ 2564430068 62488;
BA_ "Type" BO_ 2564486208 8;
BA_ "DiagResponse" BO_ 2564486208 1;
BA_ "DiagConnection" BO_ 2564486208 62528;
BA_ "Type" BO_ 2564486184 8;
BA_ "DiagResponse" BO_ 2564486184 1;
BA_ "DiagConnection" BO_ 2564486184 62504;
BA_ "Type" BO_ 2564486160 8;
BA_ "DiagResponse" BO_ 2564486160 1;
BA_ "DiagConnection" BO_ 2564486160 62480;
BA_ "Type" BO_ 2564485392 8;
BA_ "DiagResponse" BO_ 2564485392 1;
BA_ "DiagConnection" BO_ 2564485392 61712;
BA_ "Type" BO_ 2564486192 8;
BA_ "DiagResponse" BO_ 2564486192 1;
BA_ "DiagConnection" BO_ 2564486192 62512;
BA_ "Type" BO_ 2564486240 8;
BA_ "DiagResponse" BO_ 2564486240 1;
BA_ "DiagConnection" BO_ 2564486240 62560;
BA_ "Type" BO_ 2564486336 8;
BA_ "DiagResponse" BO_ 2564486336 1;
BA_ "DiagConnection" BO_ 2564486336 62656;
BA_ "Type" BO_ 2564486304 8;
BA_ "DiagResponse" BO_ 2564486304 1;
BA_ "DiagConnection" BO_ 2564486304 62624;
BA_ "Type" BO_ 2564486168 8;
BA_ "DiagResponse" BO_ 2564486168 1;
BA_ "DiagConnection" BO_ 2564486168 62488;
BA_ "Type" BO_ 222 1;
BA_ "GenMsgSendType" BO_ 222 0;
BA_ "GenMsgILSupport" BO_ 222 1;
BA_ "GenMsgCycleTime" BO_ 222 10;
BA_ "Type" BO_ 100 8;
BA_ "GenMsgILSupport" BO_ 100 1;
BA_ "Type" BO_ 104 11;
BA_ "GenMsgILSupport" BO_ 104 1;
BA_ "Type" BO_ 346 10;
BA_ "GenMsgSendType" BO_ 346 0;
BA_ "GenMsgILSupport" BO_ 346 1;
BA_ "GenMsgStartDelayTime" BO_ 346 5;
BA_ "GenMsgCycleTimeFast" BO_ 346 10;
BA_ "GenMsgCycleTime" BO_ 346 500;
BA_ "Type" BO_ 258 1;
BA_ "GenMsgSendType" BO_ 258 0;
BA_ "GenMsgILSupport" BO_ 258 1;
BA_ "GenMsgStartDelayTime" BO_ 258 8;
BA_ "GenMsgCycleTime" BO_ 258 10;
BA_ "Type" BO_ 230 1;
BA_ "GenMsgSendType" BO_ 230 0;
BA_ "GenMsgILSupport" BO_ 230 1;
BA_ "GenMsgStartDelayTime" BO_ 230 4;
BA_ "GenMsgCycleTime" BO_ 230 10;
BA_ "Type" BO_ 226 1;
BA_ "GenMsgSendType" BO_ 226 0;
BA_ "GenMsgILSupport" BO_ 226 1;
BA_ "GenMsgCycleTime" BO_ 226 10;
BA_ "GenSigTimeoutTime_BCM" SG_ 1050 BatteryCurrentLevel 0;
BA_ "GenSigTimeoutTime_BSM" SG_ 1050 BatteryCurrentLevel 0;
BA_ "GenSigTimeoutTime_DIAG_TEST" SG_ 1050 BatteryCurrentLevel 0;
BA_ "GenSigTimeoutTime_EPS" SG_ 1050 BatteryCurrentLevel 0;
BA_ "GenSigTimeoutTime_IPC" SG_ 1050 BatteryCurrentLevel 0;
BA_ "GenSigTimeoutTime_MTA" SG_ 1050 BatteryCurrentLevel 0;
BA_ "GenSigTimeoutTime_ORC" SG_ 1050 BatteryCurrentLevel 0;
BA_ "GenSigTimeoutTime_PAM" SG_ 1050 BatteryCurrentLevel 0;
BA_ "GenSigStartValue" SG_ 1050 BatteryStateOfFunction 63;
BA_ "GenSigTimeoutTime_BCM" SG_ 1050 BatteryStateOfFunction 0;
BA_ "GenSigTimeoutTime_BSM" SG_ 1050 BatteryStateOfFunction 0;
BA_ "GenSigTimeoutTime_DIAG_TEST" SG_ 1050 BatteryStateOfFunction 0;
BA_ "GenSigTimeoutTime_EPS" SG_ 1050 BatteryStateOfFunction 0;
BA_ "GenSigTimeoutTime_IPC" SG_ 1050 BatteryStateOfFunction 0;
BA_ "GenSigTimeoutTime_MTA" SG_ 1050 BatteryStateOfFunction 0;
BA_ "GenSigTimeoutTime_ORC" SG_ 1050 BatteryStateOfFunction 0;
BA_ "GenSigTimeoutTime_PAM" SG_ 1050 BatteryStateOfFunction 0;
BA_ "GenSigTimeoutTime_BCM" SG_ 1050 BatteryTemperature 0;
BA_ "GenSigTimeoutTime_BSM" SG_ 1050 BatteryTemperature 0;
BA_ "GenSigTimeoutTime_DIAG_TEST" SG_ 1050 BatteryTemperature 0;
BA_ "GenSigTimeoutTime_EPS" SG_ 1050 BatteryTemperature 0;
BA_ "GenSigTimeoutTime_IPC" SG_ 1050 BatteryTemperature 0;
BA_ "GenSigTimeoutTime_MTA" SG_ 1050 BatteryTemperature 0;
BA_ "GenSigTimeoutTime_ORC" SG_ 1050 BatteryTemperature 0;
BA_ "GenSigTimeoutTime_PAM" SG_ 1050 BatteryTemperature 0;
BA_ "GenSigStartValue" SG_ 1050 BatteryVoltageLevelHP 4;
BA_ "GenSigTimeoutTime_BCM" SG_ 1050 BatteryVoltageLevelHP 0;
BA_ "GenSigTimeoutTime_BSM" SG_ 1050 BatteryVoltageLevelHP 0;
BA_ "GenSigTimeoutTime_DIAG_TEST" SG_ 1050 BatteryVoltageLevelHP 0;
BA_ "GenSigTimeoutTime_EPS" SG_ 1050 BatteryVoltageLevelHP 0;
BA_ "GenSigTimeoutTime_IPC" SG_ 1050 BatteryVoltageLevelHP 0;
BA_ "GenSigTimeoutTime_MTA" SG_ 1050 BatteryVoltageLevelHP 0;
BA_ "GenSigTimeoutTime_ORC" SG_ 1050 BatteryVoltageLevelHP 0;
BA_ "GenSigTimeoutTime_PAM" SG_ 1050 BatteryVoltageLevelHP 0;
BA_ "GenSigTimeoutTime_BCM" SG_ 1050 BCMSAMFailSts 0;
BA_ "GenSigTimeoutTime_BSM" SG_ 1050 BCMSAMFailSts 0;
BA_ "GenSigTimeoutTime_DIAG_TEST" SG_ 1050 BCMSAMFailSts 0;
BA_ "GenSigTimeoutTime_EPS" SG_ 1050 BCMSAMFailSts 0;
BA_ "GenSigTimeoutTime_IPC" SG_ 1050 BCMSAMFailSts 0;
BA_ "GenSigTimeoutTime_MTA" SG_ 1050 BCMSAMFailSts 0;
BA_ "GenSigTimeoutTime_ORC" SG_ 1050 BCMSAMFailSts 0;
BA_ "GenSigTimeoutTime_PAM" SG_ 1050 BCMSAMFailSts 0;
BA_ "GenSigTimeoutTime_BCM" SG_ 1050 IBSFailSts 0;
BA_ "GenSigTimeoutTime_BSM" SG_ 1050 IBSFailSts 0;
BA_ "GenSigTimeoutTime_DIAG_TEST" SG_ 1050 IBSFailSts 0;
BA_ "GenSigTimeoutTime_EPS" SG_ 1050 IBSFailSts 0;
BA_ "GenSigTimeoutTime_IPC" SG_ 1050 IBSFailSts 0;
BA_ "GenSigTimeoutTime_MTA" SG_ 1050 IBSFailSts 0;
BA_ "GenSigTimeoutTime_ORC" SG_ 1050 IBSFailSts 0;
BA_ "GenSigTimeoutTime_PAM" SG_ 1050 IBSFailSts 0;
BA_ "GenSigTimeoutTime_BCM" SG_ 1050 Recalibration 0;
BA_ "GenSigTimeoutTime_BSM" SG_ 1050 Recalibration 0;
BA_ "GenSigTimeoutTime_DIAG_TEST" SG_ 1050 Recalibration 0;
BA_ "GenSigTimeoutTime_EPS" SG_ 1050 Recalibration 0;
BA_ "GenSigTimeoutTime_IPC" SG_ 1050 Recalibration 0;
BA_ "GenSigTimeoutTime_MTA" SG_ 1050 Recalibration 0;
BA_ "GenSigTimeoutTime_ORC" SG_ 1050 Recalibration 0;
BA_ "GenSigTimeoutTime_PAM" SG_ 1050 Recalibration 0;
BA_ "GenSigStartValue" SG_ 1050 StateOfCharge 100;
BA_ "GenSigTimeoutTime_BCM" SG_ 1050 StateOfCharge 0;
BA_ "GenSigTimeoutTime_BSM" SG_ 1050 StateOfCharge 0;
BA_ "GenSigTimeoutTime_DIAG_TEST" SG_ 1050 StateOfCharge 0;
BA_ "GenSigTimeoutTime_EPS" SG_ 1050 StateOfCharge 0;
BA_ "GenSigTimeoutTime_IPC" SG_ 1050 StateOfCharge 0;
BA_ "GenSigTimeoutTime_MTA" SG_ 1050 StateOfCharge 0;
BA_ "GenSigTimeoutTime_ORC" SG_ 1050 StateOfCharge 0;
BA_ "GenSigTimeoutTime_PAM" SG_ 1050 StateOfCharge 0;
BA_ "GenSigTimeoutTime_BCM" SG_ 1050 VoltageMax 0;
BA_ "GenSigTimeoutTime_BSM" SG_ 1050 VoltageMax 0;
BA_ "GenSigTimeoutTime_DIAG_TEST" SG_ 1050 VoltageMax 0;
BA_ "GenSigTimeoutTime_EPS" SG_ 1050 VoltageMax 0;
BA_ "GenSigTimeoutTime_IPC" SG_ 1050 VoltageMax 0;
BA_ "GenSigTimeoutTime_MTA" SG_ 1050 VoltageMax 0;
BA_ "GenSigTimeoutTime_ORC" SG_ 1050 VoltageMax 0;
BA_ "GenSigTimeoutTime_PAM" SG_ 1050 VoltageMax 0;
BA_ "GenSigTimeoutTime_BCM" SG_ 1050 VoltageMin 0;
BA_ "GenSigTimeoutTime_BSM" SG_ 1050 VoltageMin 0;
BA_ "GenSigTimeoutTime_DIAG_TEST" SG_ 1050 VoltageMin 0;
BA_ "GenSigTimeoutTime_EPS" SG_ 1050 VoltageMin 0;
BA_ "GenSigTimeoutTime_IPC" SG_ 1050 VoltageMin 0;
BA_ "GenSigTimeoutTime_MTA" SG_ 1050 VoltageMin 0;
BA_ "GenSigTimeoutTime_ORC" SG_ 1050 VoltageMin 0;
BA_ "GenSigTimeoutTime_PAM" SG_ 1050 VoltageMin 0;
BA_ "GenSigTimeoutTime_BCM" SG_ 250 BCMCmdMsgCounter 0;
BA_ "GenSigTimeoutTime_DIAG_TEST" SG_ 250 BCMCmdMsgCounter 0;
BA_ "GenSigTimeoutTime_EPS" SG_ 250 BCMCmdMsgCounter 0;
BA_ "GenSigTimeoutTime_IPC" SG_ 250 BCMCmdMsgCounter 0;
BA_ "GenSigTimeoutTime_ORC" SG_ 250 BCMCmdMsgCounter 0;
BA_ "GenSigTimeoutTime_PAM" SG_ 250 BCMCmdMsgCounter 0;
BA_ "GenSigTimeoutTime_BCM" SG_ 250 BCMFpsCommand 0;
BA_ "GenSigTimeoutTime_BSM" SG_ 250 BCMFpsCommand 0;
BA_ "GenSigTimeoutTime_DIAG_TEST" SG_ 250 BCMFpsCommand 0;
BA_ "GenSigTimeoutTime_EPS" SG_ 250 BCMFpsCommand 0;
BA_ "GenSigTimeoutTime_IPC" SG_ 250 BCMFpsCommand 0;
BA_ "GenSigTimeoutTime_MTA" SG_ 250 BCMFpsCommand 0;
BA_ "GenSigTimeoutTime_ORC" SG_ 250 BCMFpsCommand 0;
BA_ "GenSigTimeoutTime_PAM" SG_ 250 BCMFpsCommand 0;
BA_ "GenSigStartValue" SG_ 250 BCMFpsConfirm 1;
BA_ "GenSigTimeoutTime_BCM" SG_ 250 BCMFpsConfirm 0;
BA_ "GenSigTimeoutTime_BSM" SG_ 250 BCMFpsConfirm 0;
BA_ "GenSigTimeoutTime_DIAG_TEST" SG_ 250 BCMFpsConfirm 0;
BA_ "GenSigTimeoutTime_EPS" SG_ 250 BCMFpsConfirm 0;
BA_ "GenSigTimeoutTime_IPC" SG_ 250 BCMFpsConfirm 0;
BA_ "GenSigTimeoutTime_MTA" SG_ 250 BCMFpsConfirm 0;
BA_ "GenSigTimeoutTime_ORC" SG_ 250 BCMFpsConfirm 0;
BA_ "GenSigTimeoutTime_PAM" SG_ 250 BCMFpsConfirm 0;
BA_ "GenSigTimeoutTime_BCM" SG_ 250 BCMFpsFailSts 0;
BA_ "GenSigTimeoutTime_BSM" SG_ 250 BCMFpsFailSts 0;
BA_ "GenSigTimeoutTime_DIAG_TEST" SG_ 250 BCMFpsFailSts 0;
BA_ "GenSigTimeoutTime_EPS" SG_ 250 BCMFpsFailSts 0;
BA_ "GenSigTimeoutTime_IPC" SG_ 250 BCMFpsFailSts 0;
BA_ "GenSigTimeoutTime_MTA" SG_ 250 BCMFpsFailSts 0;
BA_ "GenSigTimeoutTime_ORC" SG_ 250 BCMFpsFailSts 0;
BA_ "GenSigTimeoutTime_PAM" SG_ 250 BCMFpsFailSts 0;
BA_ "GenSigTimeoutTime_BCM" SG_ 250 BrakePedalSwitchNCSts 0;
BA_ "GenSigTimeoutTime_DIAG_TEST" SG_ 250 BrakePedalSwitchNCSts 0;
BA_ "GenSigTimeoutTime_EPS" SG_ 250 BrakePedalSwitchNCSts 0;
BA_ "GenSigTimeoutTime_IPC" SG_ 250 BrakePedalSwitchNCSts 0;
BA_ "GenSigTimeoutTime_ORC" SG_ 250 BrakePedalSwitchNCSts 0;
BA_ "GenSigTimeoutTime_PAM" SG_ 250 BrakePedalSwitchNCSts 0;
BA_ "GenSigTimeoutTime_BCM" SG_ 250 BrakePedalSwitchNOSts 0;
BA_ "GenSigTimeoutTime_DIAG_TEST" SG_ 250 BrakePedalSwitchNOSts 0;
BA_ "GenSigTimeoutTime_EPS" SG_ 250 BrakePedalSwitchNOSts 0;
BA_ "GenSigTimeoutTime_IPC" SG_ 250 BrakePedalSwitchNOSts 0;
BA_ "GenSigTimeoutTime_ORC" SG_ 250 BrakePedalSwitchNOSts 0;
BA_ "GenSigTimeoutTime_PAM" SG_ 250 BrakePedalSwitchNOSts 0;
BA_ "GenSigTimeoutTime_BCM" SG_ 250 CrankRequestSts 0;
BA_ "GenSigTimeoutTime_BSM" SG_ 250 CrankRequestSts 0;
BA_ "GenSigTimeoutTime_DIAG_TEST" SG_ 250 CrankRequestSts 0;
BA_ "GenSigTimeoutTime_EPS" SG_ 250 CrankRequestSts 0;
BA_ "GenSigTimeoutTime_IPC" SG_ 250 CrankRequestSts 0;
BA_ "GenSigTimeoutTime_MTA" SG_ 250 CrankRequestSts 0;
BA_ "GenSigTimeoutTime_ORC" SG_ 250 CrankRequestSts 0;
BA_ "GenSigTimeoutTime_PAM" SG_ 250 CrankRequestSts 0;
BA_ "GenSigTimeoutTime_BCM" SG_ 250 OperationalModeSts 0;
BA_ "GenSigTimeoutTime_DIAG_TEST" SG_ 250 OperationalModeSts 0;
BA_ "GenSigTimeoutTime_ORC" SG_ 250 OperationalModeSts 0;
BA_ "GenSigTimeoutTime_BCM" SG_ 250 StartRelayBCMFault 0;
BA_ "GenSigTimeoutTime_BSM" SG_ 250 StartRelayBCMFault 0;
BA_ "GenSigTimeoutTime_DIAG_TEST" SG_ 250 StartRelayBCMFault 0;
BA_ "GenSigTimeoutTime_EPS" SG_ 250 StartRelayBCMFault 0;
BA_ "GenSigTimeoutTime_IPC" SG_ 250 StartRelayBCMFault 0;
BA_ "GenSigTimeoutTime_MTA" SG_ 250 StartRelayBCMFault 0;
BA_ "GenSigTimeoutTime_ORC" SG_ 250 StartRelayBCMFault 0;
BA_ "GenSigTimeoutTime_PAM" SG_ 250 StartRelayBCMFault 0;
BA_ "GenSigTimeoutTime_BCM" SG_ 250 StartRelayBCMSts 0;
BA_ "GenSigTimeoutTime_BSM" SG_ 250 StartRelayBCMSts 0;
BA_ "GenSigTimeoutTime_DIAG_TEST" SG_ 250 StartRelayBCMSts 0;
BA_ "GenSigTimeoutTime_EPS" SG_ 250 StartRelayBCMSts 0;
BA_ "GenSigTimeoutTime_IPC" SG_ 250 StartRelayBCMSts 0;
BA_ "GenSigTimeoutTime_MTA" SG_ 250 StartRelayBCMSts 0;
BA_ "GenSigTimeoutTime_ORC" SG_ 250 StartRelayBCMSts 0;
BA_ "GenSigTimeoutTime_PAM" SG_ 250 StartRelayBCMSts 0;
BA_ "GenSigTimeoutTime_BCM" SG_ 254 InternalError_BSM 0;
BA_ "GenSigTimeoutTime_BSM" SG_ 254 InternalError_BSM 0;
BA_ "GenSigTimeoutTime_DIAG_TEST" SG_ 254 InternalError_BSM 0;
BA_ "GenSigTimeoutTime_ECM" SG_ 254 InternalError_BSM 0;
BA_ "GenSigTimeoutTime_EPS" SG_ 254 InternalError_BSM 0;
BA_ "GenSigTimeoutTime_IPC" SG_ 254 InternalError_BSM 0;
BA_ "GenSigTimeoutTime_MTA" SG_ 254 InternalError_BSM 0;
BA_ "GenSigTimeoutTime_ORC" SG_ 254 InternalError_BSM 0;
BA_ "GenSigTimeoutTime_PAM" SG_ 254 InternalError_BSM 0;
BA_ "GenSigTimeoutTime_BCM" SG_ 254 LatAcceleration_BSM 0;
BA_ "GenSigTimeoutTime_BSM" SG_ 254 LatAcceleration_BSM 0;
BA_ "GenSigTimeoutTime_DIAG_TEST" SG_ 254 LatAcceleration_BSM 0;
BA_ "GenSigTimeoutTime_ECM" SG_ 254 LatAcceleration_BSM 0;
BA_ "GenSigTimeoutTime_EPS" SG_ 254 LatAcceleration_BSM 0;
BA_ "GenSigTimeoutTime_IPC" SG_ 254 LatAcceleration_BSM 0;
BA_ "GenSigTimeoutTime_ORC" SG_ 254 LatAcceleration_BSM 0;
BA_ "GenSigTimeoutTime_PAM" SG_ 254 LatAcceleration_BSM 0;
BA_ "GenSigTimeoutTime_BCM" SG_ 254 LatAccelerationFailSts_BSM 0;
BA_ "GenSigTimeoutTime_BSM" SG_ 254 LatAccelerationFailSts_BSM 0;
BA_ "GenSigTimeoutTime_DIAG_TEST" SG_ 254 LatAccelerationFailSts_BSM 0;
BA_ "GenSigTimeoutTime_ECM" SG_ 254 LatAccelerationFailSts_BSM 0;
BA_ "GenSigTimeoutTime_EPS" SG_ 254 LatAccelerationFailSts_BSM 0;
BA_ "GenSigTimeoutTime_IPC" SG_ 254 LatAccelerationFailSts_BSM 0;
BA_ "GenSigTimeoutTime_ORC" SG_ 254 LatAccelerationFailSts_BSM 0;
BA_ "GenSigTimeoutTime_PAM" SG_ 254 LatAccelerationFailSts_BSM 0;
BA_ "GenSigTimeoutTime_BCM" SG_ 254 LongAcceleration_BSM 0;
BA_ "GenSigTimeoutTime_BSM" SG_ 254 LongAcceleration_BSM 0;
BA_ "GenSigTimeoutTime_DIAG_TEST" SG_ 254 LongAcceleration_BSM 0;
BA_ "GenSigTimeoutTime_ECM" SG_ 254 LongAcceleration_BSM 0;
BA_ "GenSigTimeoutTime_EPS" SG_ 254 LongAcceleration_BSM 0;
BA_ "GenSigTimeoutTime_IPC" SG_ 254 LongAcceleration_BSM 0;
BA_ "GenSigTimeoutTime_ORC" SG_ 254 LongAcceleration_BSM 0;
BA_ "GenSigTimeoutTime_PAM" SG_ 254 LongAcceleration_BSM 0;
BA_ "GenSigTimeoutTime_BCM" SG_ 254 LongAccelerationFailSts_BSM 0;
BA_ "GenSigTimeoutTime_BSM" SG_ 254 LongAccelerationFailSts_BSM 0;
BA_ "GenSigTimeoutTime_DIAG_TEST" SG_ 254 LongAccelerationFailSts_BSM 0;
BA_ "GenSigTimeoutTime_ECM" SG_ 254 LongAccelerationFailSts_BSM 0;
BA_ "GenSigTimeoutTime_EPS" SG_ 254 LongAccelerationFailSts_BSM 0;
BA_ "GenSigTimeoutTime_IPC" SG_ 254 LongAccelerationFailSts_BSM 0;
BA_ "GenSigTimeoutTime_ORC" SG_ 254 LongAccelerationFailSts_BSM 0;
BA_ "GenSigTimeoutTime_PAM" SG_ 254 LongAccelerationFailSts_BSM 0;
BA_ "GenSigTimeoutTime_BCM" SG_ 254 YawRate_BSM 0;
BA_ "GenSigTimeoutTime_BSM" SG_ 254 YawRate_BSM 0;
BA_ "GenSigTimeoutTime_DIAG_TEST" SG_ 254 YawRate_BSM 0;
BA_ "GenSigTimeoutTime_ECM" SG_ 254 YawRate_BSM 0;
BA_ "GenSigTimeoutTime_EPS" SG_ 254 YawRate_BSM 0;
BA_ "GenSigTimeoutTime_IPC" SG_ 254 YawRate_BSM 0;
BA_ "GenSigTimeoutTime_MTA" SG_ 254 YawRate_BSM 0;
BA_ "GenSigTimeoutTime_ORC" SG_ 254 YawRate_BSM 0;
BA_ "GenSigTimeoutTime_PAM" SG_ 254 YawRate_BSM 0;
BA_ "GenSigTimeoutTime_BCM" SG_ 254 YawRateFailSts_BSM 0;
BA_ "GenSigTimeoutTime_BSM" SG_ 254 YawRateFailSts_BSM 0;
BA_ "GenSigTimeoutTime_DIAG_TEST" SG_ 254 YawRateFailSts_BSM 0;
BA_ "GenSigTimeoutTime_ECM" SG_ 254 YawRateFailSts_BSM 0;
BA_ "GenSigTimeoutTime_EPS" SG_ 254 YawRateFailSts_BSM 0;
BA_ "GenSigTimeoutTime_IPC" SG_ 254 YawRateFailSts_BSM 0;
BA_ "GenSigTimeoutTime_MTA" SG_ 254 YawRateFailSts_BSM 0;
BA_ "GenSigTimeoutTime_ORC" SG_ 254 YawRateFailSts_BSM 0;
BA_ "GenSigTimeoutTime_PAM" SG_ 254 YawRateFailSts_BSM 0;
BA_ "GenSigTimeoutTime_BCM" SG_ 242 ABSActive 0;
BA_ "GenSigTimeoutTime_BSM" SG_ 242 ABSActive 0;
BA_ "GenSigTimeoutTime_DIAG_TEST" SG_ 242 ABSActive 0;
BA_ "GenSigTimeoutTime_ECM" SG_ 242 ABSActive 0;
BA_ "GenSigTimeoutTime_EPS" SG_ 242 ABSActive 0;
BA_ "GenSigTimeoutTime_IPC" SG_ 242 ABSActive 0;
BA_ "GenSigTimeoutTime_ORC" SG_ 242 ABSActive 0;
BA_ "GenSigTimeoutTime_PAM" SG_ 242 ABSActive 0;
BA_ "GenSigTimeoutTime_BCM" SG_ 242 BSMShiftInterference 0;
BA_ "GenSigTimeoutTime_BSM" SG_ 242 BSMShiftInterference 0;
BA_ "GenSigTimeoutTime_DIAG_TEST" SG_ 242 BSMShiftInterference 0;
BA_ "GenSigTimeoutTime_ECM" SG_ 242 BSMShiftInterference 0;
BA_ "GenSigTimeoutTime_EPS" SG_ 242 BSMShiftInterference 0;
BA_ "GenSigTimeoutTime_IPC" SG_ 242 BSMShiftInterference 0;
BA_ "GenSigTimeoutTime_ORC" SG_ 242 BSMShiftInterference 0;
BA_ "GenSigTimeoutTime_PAM" SG_ 242 BSMShiftInterference 0;
BA_ "GenSigTimeoutTime_BCM" SG_ 242 CRC_B1 0;
BA_ "GenSigTimeoutTime_BSM" SG_ 242 CRC_B1 0;
BA_ "GenSigTimeoutTime_DIAG_TEST" SG_ 242 CRC_B1 0;
BA_ "GenSigTimeoutTime_IPC" SG_ 242 CRC_B1 0;
BA_ "GenSigTimeoutTime_MTA" SG_ 242 CRC_B1 0;
BA_ "GenSigTimeoutTime_ORC" SG_ 242 CRC_B1 0;
BA_ "GenSigTimeoutTime_PAM" SG_ 242 CRC_B1 0;
BA_ "GenSigTimeoutTime_BCM" SG_ 242 ESCActive 0;
BA_ "GenSigTimeoutTime_BSM" SG_ 242 ESCActive 0;
BA_ "GenSigTimeoutTime_DIAG_TEST" SG_ 242 ESCActive 0;
BA_ "GenSigTimeoutTime_ECM" SG_ 242 ESCActive 0;
BA_ "GenSigTimeoutTime_EPS" SG_ 242 ESCActive 0;
BA_ "GenSigTimeoutTime_IPC" SG_ 242 ESCActive 0;
BA_ "GenSigTimeoutTime_ORC" SG_ 242 ESCActive 0;
BA_ "GenSigTimeoutTime_PAM" SG_ 242 ESCActive 0;
BA_ "GenSigTimeoutTime_BSM" SG_ 242 HillHolderActive 0;
BA_ "GenSigTimeoutTime_DIAG_TEST" SG_ 242 HillHolderActive 0;
BA_ "GenSigTimeoutTime_EPS" SG_ 242 HillHolderActive 0;
BA_ "GenSigTimeoutTime_IPC" SG_ 242 HillHolderActive 0;
BA_ "GenSigTimeoutTime_ORC" SG_ 242 HillHolderActive 0;
BA_ "GenSigTimeoutTime_PAM" SG_ 242 HillHolderActive 0;
BA_ "GenSigStartValue" SG_ 242 MasterCylinderPressure 1023;
BA_ "GenSigTimeoutTime_BCM" SG_ 242 MasterCylinderPressure 0;
BA_ "GenSigTimeoutTime_BSM" SG_ 242 MasterCylinderPressure 0;
BA_ "GenSigTimeoutTime_DIAG_TEST" SG_ 242 MasterCylinderPressure 0;
BA_ "GenSigTimeoutTime_EPS" SG_ 242 MasterCylinderPressure 0;
BA_ "GenSigTimeoutTime_IPC" SG_ 242 MasterCylinderPressure 0;
BA_ "GenSigTimeoutTime_ORC" SG_ 242 MasterCylinderPressure 0;
BA_ "GenSigTimeoutTime_PAM" SG_ 242 MasterCylinderPressure 0;
BA_ "GenSigTimeoutTime_BCM" SG_ 242 MessageCounter_B1 0;
BA_ "GenSigTimeoutTime_BSM" SG_ 242 MessageCounter_B1 0;
BA_ "GenSigTimeoutTime_DIAG_TEST" SG_ 242 MessageCounter_B1 0;
BA_ "GenSigTimeoutTime_IPC" SG_ 242 MessageCounter_B1 0;
BA_ "GenSigTimeoutTime_MTA" SG_ 242 MessageCounter_B1 0;
BA_ "GenSigTimeoutTime_ORC" SG_ 242 MessageCounter_B1 0;
BA_ "GenSigTimeoutTime_PAM" SG_ 242 MessageCounter_B1 0;
BA_ "GenSigTimeoutTime_BCM" SG_ 242 TorqueIncrease 0;
BA_ "GenSigTimeoutTime_BSM" SG_ 242 TorqueIncrease 0;
BA_ "GenSigTimeoutTime_DIAG_TEST" SG_ 242 TorqueIncrease 0;
BA_ "GenSigTimeoutTime_EPS" SG_ 242 TorqueIncrease 0;
BA_ "GenSigTimeoutTime_IPC" SG_ 242 TorqueIncrease 0;
BA_ "GenSigTimeoutTime_MTA" SG_ 242 TorqueIncrease 0;
BA_ "GenSigTimeoutTime_ORC" SG_ 242 TorqueIncrease 0;
BA_ "GenSigTimeoutTime_PAM" SG_ 242 TorqueIncrease 0;
BA_ "GenSigTimeoutTime_BCM" SG_ 242 TorqueReduct 0;
BA_ "GenSigTimeoutTime_BSM" SG_ 242 TorqueReduct 0;
BA_ "GenSigTimeoutTime_DIAG_TEST" SG_ 242 TorqueReduct 0;
BA_ "GenSigTimeoutTime_EPS" SG_ 242 TorqueReduct 0;
BA_ "GenSigTimeoutTime_IPC" SG_ 242 TorqueReduct 0;
BA_ "GenSigTimeoutTime_MTA" SG_ 242 TorqueReduct 0;
BA_ "GenSigTimeoutTime_ORC" SG_ 242 TorqueReduct 0;
BA_ "GenSigTimeoutTime_PAM" SG_ 242 TorqueReduct 0;
BA_ "GenSigStartValue" SG_ 242 TorqueRequest 2047;
BA_ "GenSigTimeoutTime_BCM" SG_ 242 TorqueRequest 0;
BA_ "GenSigTimeoutTime_BSM" SG_ 242 TorqueRequest 0;
BA_ "GenSigTimeoutTime_DIAG_TEST" SG_ 242 TorqueRequest 0;
BA_ "GenSigTimeoutTime_EPS" SG_ 242 TorqueRequest 0;
BA_ "GenSigTimeoutTime_IPC" SG_ 242 TorqueRequest 0;
BA_ "GenSigTimeoutTime_MTA" SG_ 242 TorqueRequest 0;
BA_ "GenSigTimeoutTime_ORC" SG_ 242 TorqueRequest 0;
BA_ "GenSigTimeoutTime_PAM" SG_ 242 TorqueRequest 0;
BA_ "GenSigTimeoutTime_BSM" SG_ 242 VehicleSpeedVSOSig 0;
BA_ "GenSigTimeoutTime_DIAG_TEST" SG_ 242 VehicleSpeedVSOSig 0;
BA_ "GenSigTimeoutTime_BSM" SG_ 242 VehicleSpeedVSOSigFailSts 0;
BA_ "GenSigTimeoutTime_DIAG_TEST" SG_ 242 VehicleSpeedVSOSigFailSts 0;
BA_ "GenSigTimeoutTime_BCM" SG_ 274 BrakeInterventionSts 0;
BA_ "GenSigTimeoutTime_BSM" SG_ 274 BrakeInterventionSts 0;
BA_ "GenSigTimeoutTime_DIAG_TEST" SG_ 274 BrakeInterventionSts 0;
BA_ "GenSigTimeoutTime_ECM" SG_ 274 BrakeInterventionSts 0;
BA_ "GenSigTimeoutTime_EPS" SG_ 274 BrakeInterventionSts 0;
BA_ "GenSigTimeoutTime_IPC" SG_ 274 BrakeInterventionSts 0;
BA_ "GenSigTimeoutTime_ORC" SG_ 274 BrakeInterventionSts 0;
BA_ "GenSigTimeoutTime_PAM" SG_ 274 BrakeInterventionSts 0;
BA_ "GenSigTimeoutTime_BCM" SG_ 274 HBAActive 0;
BA_ "GenSigTimeoutTime_BSM" SG_ 274 HBAActive 0;
BA_ "GenSigTimeoutTime_DIAG_TEST" SG_ 274 HBAActive 0;
BA_ "GenSigTimeoutTime_ECM" SG_ 274 HBAActive 0;
BA_ "GenSigTimeoutTime_EPS" SG_ 274 HBAActive 0;
BA_ "GenSigTimeoutTime_IPC" SG_ 274 HBAActive 0;
BA_ "GenSigTimeoutTime_MTA" SG_ 274 HBAActive 0;
BA_ "GenSigTimeoutTime_ORC" SG_ 274 HBAActive 0;
BA_ "GenSigTimeoutTime_PAM" SG_ 274 HBAActive 0;
BA_ "GenSigStartValue" SG_ 274 MuSplit 3;
BA_ "GenSigTimeoutTime_BCM" SG_ 274 MuSplit 0;
BA_ "GenSigTimeoutTime_BSM" SG_ 274 MuSplit 0;
BA_ "GenSigTimeoutTime_DIAG_TEST" SG_ 274 MuSplit 0;
BA_ "GenSigTimeoutTime_ECM" SG_ 274 MuSplit 0;
BA_ "GenSigTimeoutTime_EPS" SG_ 274 MuSplit 0;
BA_ "GenSigTimeoutTime_IPC" SG_ 274 MuSplit 0;
BA_ "GenSigTimeoutTime_MTA" SG_ 274 MuSplit 0;
BA_ "GenSigTimeoutTime_ORC" SG_ 274 MuSplit 0;
BA_ "GenSigTimeoutTime_PAM" SG_ 274 MuSplit 0;
BA_ "GenSigStartValue" SG_ 274 OverSteering 63;
BA_ "GenSigTimeoutTime_BCM" SG_ 274 OverSteering 0;
BA_ "GenSigTimeoutTime_BSM" SG_ 274 OverSteering 0;
BA_ "GenSigTimeoutTime_DIAG_TEST" SG_ 274 OverSteering 0;
BA_ "GenSigTimeoutTime_ECM" SG_ 274 OverSteering 0;
BA_ "GenSigTimeoutTime_EPS" SG_ 274 OverSteering 0;
BA_ "GenSigTimeoutTime_IPC" SG_ 274 OverSteering 0;
BA_ "GenSigTimeoutTime_MTA" SG_ 274 OverSteering 0;
BA_ "GenSigTimeoutTime_ORC" SG_ 274 OverSteering 0;
BA_ "GenSigTimeoutTime_PAM" SG_ 274 OverSteering 0;
BA_ "GenSigStartValue" SG_ 274 UnderSteering 63;
BA_ "GenSigTimeoutTime_BCM" SG_ 274 UnderSteering 0;
BA_ "GenSigTimeoutTime_BSM" SG_ 274 UnderSteering 0;
BA_ "GenSigTimeoutTime_DIAG_TEST" SG_ 274 UnderSteering 0;
BA_ "GenSigTimeoutTime_ECM" SG_ 274 UnderSteering 0;
BA_ "GenSigTimeoutTime_EPS" SG_ 274 UnderSteering 0;
BA_ "GenSigTimeoutTime_IPC" SG_ 274 UnderSteering 0;
BA_ "GenSigTimeoutTime_MTA" SG_ 274 UnderSteering 0;
BA_ "GenSigTimeoutTime_ORC" SG_ 274 UnderSteering 0;
BA_ "GenSigTimeoutTime_PAM" SG_ 274 UnderSteering 0;
BA_ "GenSigSendType" SG_ 2651930624 Digit_01 1;
BA_ "GenSigTimeoutTime_BCM" SG_ 2651930624 Digit_01 0;
BA_ "GenSigTimeoutTime_DIAG_TEST" SG_ 2651930624 Digit_01 0;
BA_ "GenSigTimeoutTime_BCM" SG_ 2651930624 Digit_02 0;
BA_ "GenSigTimeoutTime_DIAG_TEST" SG_ 2651930624 Digit_02 0;
BA_ "GenSigTimeoutTime_BCM" SG_ 2651930624 Digit_03 0;
BA_ "GenSigTimeoutTime_DIAG_TEST" SG_ 2651930624 Digit_03 0;
BA_ "GenSigTimeoutTime_BCM" SG_ 2651930624 Digit_04 0;
BA_ "GenSigTimeoutTime_DIAG_TEST" SG_ 2651930624 Digit_04 0;
BA_ "GenSigTimeoutTime_BCM" SG_ 2651930624 Digit_05 0;
BA_ "GenSigTimeoutTime_DIAG_TEST" SG_ 2651930624 Digit_05 0;
BA_ "GenSigTimeoutTime_BCM" SG_ 2651930624 Digit_06 0;
BA_ "GenSigTimeoutTime_DIAG_TEST" SG_ 2651930624 Digit_06 0;
BA_ "GenSigTimeoutTime_BCM" SG_ 2651930624 Digit_07 0;
BA_ "GenSigTimeoutTime_DIAG_TEST" SG_ 2651930624 Digit_07 0;
BA_ "GenSigTimeoutTime_BCM" SG_ 2651930624 Digit_08 0;
BA_ "GenSigTimeoutTime_DIAG_TEST" SG_ 2651930624 Digit_08 0;
BA_ "GenSigTimeoutTime_BCM" SG_ 2651930624 Digit_09 0;
BA_ "GenSigTimeoutTime_DIAG_TEST" SG_ 2651930624 Digit_09 0;
BA_ "GenSigTimeoutTime_BCM" SG_ 2651930624 Digit_10 0;
BA_ "GenSigTimeoutTime_DIAG_TEST" SG_ 2651930624 Digit_10 0;
BA_ "GenSigTimeoutTime_BCM" SG_ 2651930624 Digit_11 0;
BA_ "GenSigTimeoutTime_DIAG_TEST" SG_ 2651930624 Digit_11 0;
BA_ "GenSigSendType" SG_ 2651930630 Digit_01_BSM 1;
BA_ "GenSigTimeoutTime_BSM" SG_ 2651930630 Digit_01_BSM 0;
BA_ "GenSigTimeoutTime_DIAG_TEST" SG_ 2651930630 Digit_01_BSM 0;
BA_ "GenSigTimeoutTime_ECM" SG_ 2651930630 Digit_01_BSM 0;
BA_ "GenSigTimeoutTime_EPS" SG_ 2651930630 Digit_01_BSM 0;
BA_ "GenSigTimeoutTime_IPC" SG_ 2651930630 Digit_01_BSM 0;
BA_ "GenSigTimeoutTime_MTA" SG_ 2651930630 Digit_01_BSM 0;
BA_ "GenSigTimeoutTime_ORC" SG_ 2651930630 Digit_01_BSM 0;
BA_ "GenSigTimeoutTime_PAM" SG_ 2651930630 Digit_01_BSM 0;
BA_ "GenSigTimeoutTime_BSM" SG_ 2651930630 Digit_02_BSM 0;
BA_ "GenSigTimeoutTime_DIAG_TEST" SG_ 2651930630 Digit_02_BSM 0;
BA_ "GenSigTimeoutTime_ECM" SG_ 2651930630 Digit_02_BSM 0;
BA_ "GenSigTimeoutTime_EPS" SG_ 2651930630 Digit_02_BSM 0;
BA_ "GenSigTimeoutTime_IPC" SG_ 2651930630 Digit_02_BSM 0;
BA_ "GenSigTimeoutTime_MTA" SG_ 2651930630 Digit_02_BSM 0;
BA_ "GenSigTimeoutTime_ORC" SG_ 2651930630 Digit_02_BSM 0;
BA_ "GenSigTimeoutTime_PAM" SG_ 2651930630 Digit_02_BSM 0;
BA_ "GenSigTimeoutTime_BSM" SG_ 2651930630 Digit_03_BSM 0;
BA_ "GenSigTimeoutTime_DIAG_TEST" SG_ 2651930630 Digit_03_BSM 0;
BA_ "GenSigTimeoutTime_ECM" SG_ 2651930630 Digit_03_BSM 0;
BA_ "GenSigTimeoutTime_EPS" SG_ 2651930630 Digit_03_BSM 0;
BA_ "GenSigTimeoutTime_IPC" SG_ 2651930630 Digit_03_BSM 0;
BA_ "GenSigTimeoutTime_MTA" SG_ 2651930630 Digit_03_BSM 0;
BA_ "GenSigTimeoutTime_ORC" SG_ 2651930630 Digit_03_BSM 0;
BA_ "GenSigTimeoutTime_PAM" SG_ 2651930630 Digit_03_BSM 0;
BA_ "GenSigTimeoutTime_BSM" SG_ 2651930630 Digit_04_BSM 0;
BA_ "GenSigTimeoutTime_DIAG_TEST" SG_ 2651930630 Digit_04_BSM 0;
BA_ "GenSigTimeoutTime_ECM" SG_ 2651930630 Digit_04_BSM 0;
BA_ "GenSigTimeoutTime_EPS" SG_ 2651930630 Digit_04_BSM 0;
BA_ "GenSigTimeoutTime_IPC" SG_ 2651930630 Digit_04_BSM 0;
BA_ "GenSigTimeoutTime_MTA" SG_ 2651930630 Digit_04_BSM 0;
BA_ "GenSigTimeoutTime_ORC" SG_ 2651930630 Digit_04_BSM 0;
BA_ "GenSigTimeoutTime_PAM" SG_ 2651930630 Digit_04_BSM 0;
BA_ "GenSigTimeoutTime_BSM" SG_ 2651930630 Digit_05_BSM 0;
BA_ "GenSigTimeoutTime_DIAG_TEST" SG_ 2651930630 Digit_05_BSM 0;
BA_ "GenSigTimeoutTime_ECM" SG_ 2651930630 Digit_05_BSM 0;
BA_ "GenSigTimeoutTime_EPS" SG_ 2651930630 Digit_05_BSM 0;
BA_ "GenSigTimeoutTime_IPC" SG_ 2651930630 Digit_05_BSM 0;
BA_ "GenSigTimeoutTime_MTA" SG_ 2651930630 Digit_05_BSM 0;
BA_ "GenSigTimeoutTime_ORC" SG_ 2651930630 Digit_05_BSM 0;
BA_ "GenSigTimeoutTime_PAM" SG_ 2651930630 Digit_05_BSM 0;
BA_ "GenSigTimeoutTime_BSM" SG_ 2651930630 Digit_06_BSM 0;
BA_ "GenSigTimeoutTime_DIAG_TEST" SG_ 2651930630 Digit_06_BSM 0;
BA_ "GenSigTimeoutTime_ECM" SG_ 2651930630 Digit_06_BSM 0;
BA_ "GenSigTimeoutTime_EPS" SG_ 2651930630 Digit_06_BSM 0;
BA_ "GenSigTimeoutTime_IPC" SG_ 2651930630 Digit_06_BSM 0;
BA_ "GenSigTimeoutTime_MTA" SG_ 2651930630 Digit_06_BSM 0;
BA_ "GenSigTimeoutTime_ORC" SG_ 2651930630 Digit_06_BSM 0;
BA_ "GenSigTimeoutTime_PAM" SG_ 2651930630 Digit_06_BSM 0;
BA_ "GenSigTimeoutTime_BSM" SG_ 2651930630 Digit_07_BSM 0;
BA_ "GenSigTimeoutTime_DIAG_TEST" SG_ 2651930630 Digit_07_BSM 0;
BA_ "GenSigTimeoutTime_ECM" SG_ 2651930630 Digit_07_BSM 0;
BA_ "GenSigTimeoutTime_EPS" SG_ 2651930630 Digit_07_BSM 0;
BA_ "GenSigTimeoutTime_IPC" SG_ 2651930630 Digit_07_BSM 0;
BA_ "GenSigTimeoutTime_MTA" SG_ 2651930630 Digit_07_BSM 0;
BA_ "GenSigTimeoutTime_ORC" SG_ 2651930630 Digit_07_BSM 0;
BA_ "GenSigTimeoutTime_PAM" SG_ 2651930630 Digit_07_BSM 0;
BA_ "GenSigTimeoutTime_BSM" SG_ 2651930630 Digit_08_BSM 0;
BA_ "GenSigTimeoutTime_DIAG_TEST" SG_ 2651930630 Digit_08_BSM 0;
BA_ "GenSigTimeoutTime_ECM" SG_ 2651930630 Digit_08_BSM 0;
BA_ "GenSigTimeoutTime_EPS" SG_ 2651930630 Digit_08_BSM 0;
BA_ "GenSigTimeoutTime_IPC" SG_ 2651930630 Digit_08_BSM 0;
BA_ "GenSigTimeoutTime_MTA" SG_ 2651930630 Digit_08_BSM 0;
BA_ "GenSigTimeoutTime_ORC" SG_ 2651930630 Digit_08_BSM 0;
BA_ "GenSigTimeoutTime_PAM" SG_ 2651930630 Digit_08_BSM 0;
BA_ "GenSigTimeoutTime_BSM" SG_ 2651930630 Digit_09_BSM 0;
BA_ "GenSigTimeoutTime_DIAG_TEST" SG_ 2651930630 Digit_09_BSM 0;
BA_ "GenSigTimeoutTime_ECM" SG_ 2651930630 Digit_09_BSM 0;
BA_ "GenSigTimeoutTime_EPS" SG_ 2651930630 Digit_09_BSM 0;
BA_ "GenSigTimeoutTime_IPC" SG_ 2651930630 Digit_09_BSM 0;
BA_ "GenSigTimeoutTime_MTA" SG_ 2651930630 Digit_09_BSM 0;
BA_ "GenSigTimeoutTime_ORC" SG_ 2651930630 Digit_09_BSM 0;
BA_ "GenSigTimeoutTime_PAM" SG_ 2651930630 Digit_09_BSM 0;
BA_ "GenSigTimeoutTime_BSM" SG_ 2651930630 Digit_10_BSM 0;
BA_ "GenSigTimeoutTime_DIAG_TEST" SG_ 2651930630 Digit_10_BSM 0;
BA_ "GenSigTimeoutTime_ECM" SG_ 2651930630 Digit_10_BSM 0;
BA_ "GenSigTimeoutTime_EPS" SG_ 2651930630 Digit_10_BSM 0;
BA_ "GenSigTimeoutTime_IPC" SG_ 2651930630 Digit_10_BSM 0;
BA_ "GenSigTimeoutTime_MTA" SG_ 2651930630 Digit_10_BSM 0;
BA_ "GenSigTimeoutTime_ORC" SG_ 2651930630 Digit_10_BSM 0;
BA_ "GenSigTimeoutTime_PAM" SG_ 2651930630 Digit_10_BSM 0;
BA_ "GenSigTimeoutTime_BSM" SG_ 2651930630 Digit_11_BSM 0;
BA_ "GenSigTimeoutTime_DIAG_TEST" SG_ 2651930630 Digit_11_BSM 0;
BA_ "GenSigTimeoutTime_ECM" SG_ 2651930630 Digit_11_BSM 0;
BA_ "GenSigTimeoutTime_EPS" SG_ 2651930630 Digit_11_BSM 0;
BA_ "GenSigTimeoutTime_IPC" SG_ 2651930630 Digit_11_BSM 0;
BA_ "GenSigTimeoutTime_MTA" SG_ 2651930630 Digit_11_BSM 0;
BA_ "GenSigTimeoutTime_ORC" SG_ 2651930630 Digit_11_BSM 0;
BA_ "GenSigTimeoutTime_PAM" SG_ 2651930630 Digit_11_BSM 0;
BA_ "GenSigSendType" SG_ 2651930625 Digit_01_ECM 1;
BA_ "GenSigTimeoutTime_BSM" SG_ 2651930625 Digit_01_ECM 0;
BA_ "GenSigTimeoutTime_DIAG_TEST" SG_ 2651930625 Digit_01_ECM 0;
BA_ "GenSigTimeoutTime_ECM" SG_ 2651930625 Digit_01_ECM 0;
BA_ "GenSigTimeoutTime_EPS" SG_ 2651930625 Digit_01_ECM 0;
BA_ "GenSigTimeoutTime_IPC" SG_ 2651930625 Digit_01_ECM 0;
BA_ "GenSigTimeoutTime_MTA" SG_ 2651930625 Digit_01_ECM 0;
BA_ "GenSigTimeoutTime_ORC" SG_ 2651930625 Digit_01_ECM 0;
BA_ "GenSigTimeoutTime_PAM" SG_ 2651930625 Digit_01_ECM 0;
BA_ "GenSigTimeoutTime_BSM" SG_ 2651930625 Digit_02_ECM 0;
BA_ "GenSigTimeoutTime_DIAG_TEST" SG_ 2651930625 Digit_02_ECM 0;
BA_ "GenSigTimeoutTime_ECM" SG_ 2651930625 Digit_02_ECM 0;
BA_ "GenSigTimeoutTime_EPS" SG_ 2651930625 Digit_02_ECM 0;
BA_ "GenSigTimeoutTime_IPC" SG_ 2651930625 Digit_02_ECM 0;
BA_ "GenSigTimeoutTime_MTA" SG_ 2651930625 Digit_02_ECM 0;
BA_ "GenSigTimeoutTime_ORC" SG_ 2651930625 Digit_02_ECM 0;
BA_ "GenSigTimeoutTime_PAM" SG_ 2651930625 Digit_02_ECM 0;
BA_ "GenSigTimeoutTime_BSM" SG_ 2651930625 Digit_03_ECM 0;
BA_ "GenSigTimeoutTime_DIAG_TEST" SG_ 2651930625 Digit_03_ECM 0;
BA_ "GenSigTimeoutTime_ECM" SG_ 2651930625 Digit_03_ECM 0;
BA_ "GenSigTimeoutTime_EPS" SG_ 2651930625 Digit_03_ECM 0;
BA_ "GenSigTimeoutTime_IPC" SG_ 2651930625 Digit_03_ECM 0;
BA_ "GenSigTimeoutTime_MTA" SG_ 2651930625 Digit_03_ECM 0;
BA_ "GenSigTimeoutTime_ORC" SG_ 2651930625 Digit_03_ECM 0;
BA_ "GenSigTimeoutTime_PAM" SG_ 2651930625 Digit_03_ECM 0;
BA_ "GenSigTimeoutTime_BSM" SG_ 2651930625 Digit_04_ECM 0;
BA_ "GenSigTimeoutTime_DIAG_TEST" SG_ 2651930625 Digit_04_ECM 0;
BA_ "GenSigTimeoutTime_ECM" SG_ 2651930625 Digit_04_ECM 0;
BA_ "GenSigTimeoutTime_EPS" SG_ 2651930625 Digit_04_ECM 0;
BA_ "GenSigTimeoutTime_IPC" SG_ 2651930625 Digit_04_ECM 0;
BA_ "GenSigTimeoutTime_MTA" SG_ 2651930625 Digit_04_ECM 0;
BA_ "GenSigTimeoutTime_ORC" SG_ 2651930625 Digit_04_ECM 0;
BA_ "GenSigTimeoutTime_PAM" SG_ 2651930625 Digit_04_ECM 0;
BA_ "GenSigTimeoutTime_BSM" SG_ 2651930625 Digit_05_ECM 0;
BA_ "GenSigTimeoutTime_DIAG_TEST" SG_ 2651930625 Digit_05_ECM 0;
BA_ "GenSigTimeoutTime_ECM" SG_ 2651930625 Digit_05_ECM 0;
BA_ "GenSigTimeoutTime_EPS" SG_ 2651930625 Digit_05_ECM 0;
BA_ "GenSigTimeoutTime_IPC" SG_ 2651930625 Digit_05_ECM 0;
BA_ "GenSigTimeoutTime_MTA" SG_ 2651930625 Digit_05_ECM 0;
BA_ "GenSigTimeoutTime_ORC" SG_ 2651930625 Digit_05_ECM 0;
BA_ "GenSigTimeoutTime_PAM" SG_ 2651930625 Digit_05_ECM 0;
BA_ "GenSigTimeoutTime_BSM" SG_ 2651930625 Digit_06_ECM 0;
BA_ "GenSigTimeoutTime_DIAG_TEST" SG_ 2651930625 Digit_06_ECM 0;
BA_ "GenSigTimeoutTime_ECM" SG_ 2651930625 Digit_06_ECM 0;
BA_ "GenSigTimeoutTime_EPS" SG_ 2651930625 Digit_06_ECM 0;
BA_ "GenSigTimeoutTime_IPC" SG_ 2651930625 Digit_06_ECM 0;
BA_ "GenSigTimeoutTime_MTA" SG_ 2651930625 Digit_06_ECM 0;
BA_ "GenSigTimeoutTime_ORC" SG_ 2651930625 Digit_06_ECM 0;
BA_ "GenSigTimeoutTime_PAM" SG_ 2651930625 Digit_06_ECM 0;
BA_ "GenSigTimeoutTime_BSM" SG_ 2651930625 Digit_07_ECM 0;
BA_ "GenSigTimeoutTime_DIAG_TEST" SG_ 2651930625 Digit_07_ECM 0;
BA_ "GenSigTimeoutTime_ECM" SG_ 2651930625 Digit_07_ECM 0;
BA_ "GenSigTimeoutTime_EPS" SG_ 2651930625 Digit_07_ECM 0;
BA_ "GenSigTimeoutTime_IPC" SG_ 2651930625 Digit_07_ECM 0;
BA_ "GenSigTimeoutTime_MTA" SG_ 2651930625 Digit_07_ECM 0;
BA_ "GenSigTimeoutTime_ORC" SG_ 2651930625 Digit_07_ECM 0;
BA_ "GenSigTimeoutTime_PAM" SG_ 2651930625 Digit_07_ECM 0;
BA_ "GenSigTimeoutTime_BSM" SG_ 2651930625 Digit_08_ECM 0;
BA_ "GenSigTimeoutTime_DIAG_TEST" SG_ 2651930625 Digit_08_ECM 0;
BA_ "GenSigTimeoutTime_ECM" SG_ 2651930625 Digit_08_ECM 0;
BA_ "GenSigTimeoutTime_EPS" SG_ 2651930625 Digit_08_ECM 0;
BA_ "GenSigTimeoutTime_IPC" SG_ 2651930625 Digit_08_ECM 0;
BA_ "GenSigTimeoutTime_MTA" SG_ 2651930625 Digit_08_ECM 0;
BA_ "GenSigTimeoutTime_ORC" SG_ 2651930625 Digit_08_ECM 0;
BA_ "GenSigTimeoutTime_PAM" SG_ 2651930625 Digit_08_ECM 0;
BA_ "GenSigTimeoutTime_BSM" SG_ 2651930625 Digit_09_ECM 0;
BA_ "GenSigTimeoutTime_DIAG_TEST" SG_ 2651930625 Digit_09_ECM 0;
BA_ "GenSigTimeoutTime_ECM" SG_ 2651930625 Digit_09_ECM 0;
BA_ "GenSigTimeoutTime_EPS" SG_ 2651930625 Digit_09_ECM 0;
BA_ "GenSigTimeoutTime_IPC" SG_ 2651930625 Digit_09_ECM 0;
BA_ "GenSigTimeoutTime_MTA" SG_ 2651930625 Digit_09_ECM 0;
BA_ "GenSigTimeoutTime_ORC" SG_ 2651930625 Digit_09_ECM 0;
BA_ "GenSigTimeoutTime_PAM" SG_ 2651930625 Digit_09_ECM 0;
BA_ "GenSigTimeoutTime_BSM" SG_ 2651930625 Digit_10_ECM 0;
BA_ "GenSigTimeoutTime_DIAG_TEST" SG_ 2651930625 Digit_10_ECM 0;
BA_ "GenSigTimeoutTime_ECM" SG_ 2651930625 Digit_10_ECM 0;
BA_ "GenSigTimeoutTime_EPS" SG_ 2651930625 Digit_10_ECM 0;
BA_ "GenSigTimeoutTime_IPC" SG_ 2651930625 Digit_10_ECM 0;
BA_ "GenSigTimeoutTime_MTA" SG_ 2651930625 Digit_10_ECM 0;
BA_ "GenSigTimeoutTime_ORC" SG_ 2651930625 Digit_10_ECM 0;
BA_ "GenSigTimeoutTime_PAM" SG_ 2651930625 Digit_10_ECM 0;
BA_ "GenSigTimeoutTime_BSM" SG_ 2651930625 Digit_11_ECM 0;
BA_ "GenSigTimeoutTime_DIAG_TEST" SG_ 2651930625 Digit_11_ECM 0;
BA_ "GenSigTimeoutTime_ECM" SG_ 2651930625 Digit_11_ECM 0;
BA_ "GenSigTimeoutTime_EPS" SG_ 2651930625 Digit_11_ECM 0;
BA_ "GenSigTimeoutTime_IPC" SG_ 2651930625 Digit_11_ECM 0;
BA_ "GenSigTimeoutTime_MTA" SG_ 2651930625 Digit_11_ECM 0;
BA_ "GenSigTimeoutTime_ORC" SG_ 2651930625 Digit_11_ECM 0;
BA_ "GenSigTimeoutTime_PAM" SG_ 2651930625 Digit_11_ECM 0;
BA_ "GenSigSendType" SG_ 2651930626 Digit_01_EPS 1;
BA_ "GenSigTimeoutTime_BSM" SG_ 2651930626 Digit_01_EPS 0;
BA_ "GenSigTimeoutTime_DIAG_TEST" SG_ 2651930626 Digit_01_EPS 0;
BA_ "GenSigTimeoutTime_ECM" SG_ 2651930626 Digit_01_EPS 0;
BA_ "GenSigTimeoutTime_EPS" SG_ 2651930626 Digit_01_EPS 0;
BA_ "GenSigTimeoutTime_IPC" SG_ 2651930626 Digit_01_EPS 0;
BA_ "GenSigTimeoutTime_MTA" SG_ 2651930626 Digit_01_EPS 0;
BA_ "GenSigTimeoutTime_ORC" SG_ 2651930626 Digit_01_EPS 0;
BA_ "GenSigTimeoutTime_PAM" SG_ 2651930626 Digit_01_EPS 0;
BA_ "GenSigTimeoutTime_BSM" SG_ 2651930626 Digit_02_EPS 0;
BA_ "GenSigTimeoutTime_DIAG_TEST" SG_ 2651930626 Digit_02_EPS 0;
BA_ "GenSigTimeoutTime_ECM" SG_ 2651930626 Digit_02_EPS 0;
BA_ "GenSigTimeoutTime_EPS" SG_ 2651930626 Digit_02_EPS 0;
BA_ "GenSigTimeoutTime_IPC" SG_ 2651930626 Digit_02_EPS 0;
BA_ "GenSigTimeoutTime_MTA" SG_ 2651930626 Digit_02_EPS 0;
BA_ "GenSigTimeoutTime_ORC" SG_ 2651930626 Digit_02_EPS 0;
BA_ "GenSigTimeoutTime_PAM" SG_ 2651930626 Digit_02_EPS 0;
BA_ "GenSigTimeoutTime_BSM" SG_ 2651930626 Digit_03_EPS 0;
BA_ "GenSigTimeoutTime_DIAG_TEST" SG_ 2651930626 Digit_03_EPS 0;
BA_ "GenSigTimeoutTime_ECM" SG_ 2651930626 Digit_03_EPS 0;
BA_ "GenSigTimeoutTime_EPS" SG_ 2651930626 Digit_03_EPS 0;
BA_ "GenSigTimeoutTime_IPC" SG_ 2651930626 Digit_03_EPS 0;
BA_ "GenSigTimeoutTime_MTA" SG_ 2651930626 Digit_03_EPS 0;
BA_ "GenSigTimeoutTime_ORC" SG_ 2651930626 Digit_03_EPS 0;
BA_ "GenSigTimeoutTime_PAM" SG_ 2651930626 Digit_03_EPS 0;
BA_ "GenSigTimeoutTime_BSM" SG_ 2651930626 Digit_04_EPS 0;
BA_ "GenSigTimeoutTime_DIAG_TEST" SG_ 2651930626 Digit_04_EPS 0;
BA_ "GenSigTimeoutTime_ECM" SG_ 2651930626 Digit_04_EPS 0;
BA_ "GenSigTimeoutTime_EPS" SG_ 2651930626 Digit_04_EPS 0;
BA_ "GenSigTimeoutTime_IPC" SG_ 2651930626 Digit_04_EPS 0;
BA_ "GenSigTimeoutTime_MTA" SG_ 2651930626 Digit_04_EPS 0;
BA_ "GenSigTimeoutTime_ORC" SG_ 2651930626 Digit_04_EPS 0;
BA_ "GenSigTimeoutTime_PAM" SG_ 2651930626 Digit_04_EPS 0;
BA_ "GenSigTimeoutTime_BSM" SG_ 2651930626 Digit_05_EPS 0;
BA_ "GenSigTimeoutTime_DIAG_TEST" SG_ 2651930626 Digit_05_EPS 0;
BA_ "GenSigTimeoutTime_ECM" SG_ 2651930626 Digit_05_EPS 0;
BA_ "GenSigTimeoutTime_EPS" SG_ 2651930626 Digit_05_EPS 0;
BA_ "GenSigTimeoutTime_IPC" SG_ 2651930626 Digit_05_EPS 0;
BA_ "GenSigTimeoutTime_MTA" SG_ 2651930626 Digit_05_EPS 0;
BA_ "GenSigTimeoutTime_ORC" SG_ 2651930626 Digit_05_EPS 0;
BA_ "GenSigTimeoutTime_PAM" SG_ 2651930626 Digit_05_EPS 0;
BA_ "GenSigTimeoutTime_BSM" SG_ 2651930626 Digit_06_EPS 0;
BA_ "GenSigTimeoutTime_DIAG_TEST" SG_ 2651930626 Digit_06_EPS 0;
BA_ "GenSigTimeoutTime_ECM" SG_ 2651930626 Digit_06_EPS 0;
BA_ "GenSigTimeoutTime_EPS" SG_ 2651930626 Digit_06_EPS 0;
BA_ "GenSigTimeoutTime_IPC" SG_ 2651930626 Digit_06_EPS 0;
BA_ "GenSigTimeoutTime_MTA" SG_ 2651930626 Digit_06_EPS 0;
BA_ "GenSigTimeoutTime_ORC" SG_ 2651930626 Digit_06_EPS 0;
BA_ "GenSigTimeoutTime_PAM" SG_ 2651930626 Digit_06_EPS 0;
BA_ "GenSigTimeoutTime_BSM" SG_ 2651930626 Digit_07_EPS 0;
BA_ "GenSigTimeoutTime_DIAG_TEST" SG_ 2651930626 Digit_07_EPS 0;
BA_ "GenSigTimeoutTime_ECM" SG_ 2651930626 Digit_07_EPS 0;
BA_ "GenSigTimeoutTime_EPS" SG_ 2651930626 Digit_07_EPS 0;
BA_ "GenSigTimeoutTime_IPC" SG_ 2651930626 Digit_07_EPS 0;
BA_ "GenSigTimeoutTime_MTA" SG_ 2651930626 Digit_07_EPS 0;
BA_ "GenSigTimeoutTime_ORC" SG_ 2651930626 Digit_07_EPS 0;
BA_ "GenSigTimeoutTime_PAM" SG_ 2651930626 Digit_07_EPS 0;
BA_ "GenSigTimeoutTime_BSM" SG_ 2651930626 Digit_08_EPS 0;
BA_ "GenSigTimeoutTime_DIAG_TEST" SG_ 2651930626 Digit_08_EPS 0;
BA_ "GenSigTimeoutTime_ECM" SG_ 2651930626 Digit_08_EPS 0;
BA_ "GenSigTimeoutTime_EPS" SG_ 2651930626 Digit_08_EPS 0;
BA_ "GenSigTimeoutTime_IPC" SG_ 2651930626 Digit_08_EPS 0;
BA_ "GenSigTimeoutTime_MTA" SG_ 2651930626 Digit_08_EPS 0;
BA_ "GenSigTimeoutTime_ORC" SG_ 2651930626 Digit_08_EPS 0;
BA_ "GenSigTimeoutTime_PAM" SG_ 2651930626 Digit_08_EPS 0;
BA_ "GenSigTimeoutTime_BSM" SG_ 2651930626 Digit_09_EPS 0;
BA_ "GenSigTimeoutTime_DIAG_TEST" SG_ 2651930626 Digit_09_EPS 0;
BA_ "GenSigTimeoutTime_ECM" SG_ 2651930626 Digit_09_EPS 0;
BA_ "GenSigTimeoutTime_EPS" SG_ 2651930626 Digit_09_EPS 0;
BA_ "GenSigTimeoutTime_IPC" SG_ 2651930626 Digit_09_EPS 0;
BA_ "GenSigTimeoutTime_MTA" SG_ 2651930626 Digit_09_EPS 0;
BA_ "GenSigTimeoutTime_ORC" SG_ 2651930626 Digit_09_EPS 0;
BA_ "GenSigTimeoutTime_PAM" SG_ 2651930626 Digit_09_EPS 0;
BA_ "GenSigTimeoutTime_BSM" SG_ 2651930626 Digit_10_EPS 0;
BA_ "GenSigTimeoutTime_DIAG_TEST" SG_ 2651930626 Digit_10_EPS 0;
BA_ "GenSigTimeoutTime_ECM" SG_ 2651930626 Digit_10_EPS 0;
BA_ "GenSigTimeoutTime_EPS" SG_ 2651930626 Digit_10_EPS 0;
BA_ "GenSigTimeoutTime_IPC" SG_ 2651930626 Digit_10_EPS 0;
BA_ "GenSigTimeoutTime_MTA" SG_ 2651930626 Digit_10_EPS 0;
BA_ "GenSigTimeoutTime_ORC" SG_ 2651930626 Digit_10_EPS 0;
BA_ "GenSigTimeoutTime_PAM" SG_ 2651930626 Digit_10_EPS 0;
BA_ "GenSigTimeoutTime_BSM" SG_ 2651930626 Digit_11_EPS 0;
BA_ "GenSigTimeoutTime_DIAG_TEST" SG_ 2651930626 Digit_11_EPS 0;
BA_ "GenSigTimeoutTime_ECM" SG_ 2651930626 Digit_11_EPS 0;
BA_ "GenSigTimeoutTime_EPS" SG_ 2651930626 Digit_11_EPS 0;
BA_ "GenSigTimeoutTime_IPC" SG_ 2651930626 Digit_11_EPS 0;
BA_ "GenSigTimeoutTime_MTA" SG_ 2651930626 Digit_11_EPS 0;
BA_ "GenSigTimeoutTime_ORC" SG_ 2651930626 Digit_11_EPS 0;
BA_ "GenSigTimeoutTime_PAM" SG_ 2651930626 Digit_11_EPS 0;
BA_ "GenSigSendType" SG_ 2651930627 Digit_01_IPC 1;
BA_ "GenSigTimeoutTime_BSM" SG_ 2651930627 Digit_01_IPC 0;
BA_ "GenSigTimeoutTime_DIAG_TEST" SG_ 2651930627 Digit_01_IPC 0;
BA_ "GenSigTimeoutTime_ECM" SG_ 2651930627 Digit_01_IPC 0;
BA_ "GenSigTimeoutTime_EPS" SG_ 2651930627 Digit_01_IPC 0;
BA_ "GenSigTimeoutTime_IPC" SG_ 2651930627 Digit_01_IPC 0;
BA_ "GenSigTimeoutTime_MTA" SG_ 2651930627 Digit_01_IPC 0;
BA_ "GenSigTimeoutTime_ORC" SG_ 2651930627 Digit_01_IPC 0;
BA_ "GenSigTimeoutTime_PAM" SG_ 2651930627 Digit_01_IPC 0;
BA_ "GenSigTimeoutTime_BSM" SG_ 2651930627 Digit_02_IPC 0;
BA_ "GenSigTimeoutTime_DIAG_TEST" SG_ 2651930627 Digit_02_IPC 0;
BA_ "GenSigTimeoutTime_ECM" SG_ 2651930627 Digit_02_IPC 0;
BA_ "GenSigTimeoutTime_EPS" SG_ 2651930627 Digit_02_IPC 0;
BA_ "GenSigTimeoutTime_IPC" SG_ 2651930627 Digit_02_IPC 0;
BA_ "GenSigTimeoutTime_MTA" SG_ 2651930627 Digit_02_IPC 0;
BA_ "GenSigTimeoutTime_ORC" SG_ 2651930627 Digit_02_IPC 0;
BA_ "GenSigTimeoutTime_PAM" SG_ 2651930627 Digit_02_IPC 0;
BA_ "GenSigTimeoutTime_BSM" SG_ 2651930627 Digit_03_IPC 0;
BA_ "GenSigTimeoutTime_DIAG_TEST" SG_ 2651930627 Digit_03_IPC 0;
BA_ "GenSigTimeoutTime_ECM" SG_ 2651930627 Digit_03_IPC 0;
BA_ "GenSigTimeoutTime_EPS" SG_ 2651930627 Digit_03_IPC 0;
BA_ "GenSigTimeoutTime_IPC" SG_ 2651930627 Digit_03_IPC 0;
BA_ "GenSigTimeoutTime_MTA" SG_ 2651930627 Digit_03_IPC 0;
BA_ "GenSigTimeoutTime_ORC" SG_ 2651930627 Digit_03_IPC 0;
BA_ "GenSigTimeoutTime_PAM" SG_ 2651930627 Digit_03_IPC 0;
BA_ "GenSigTimeoutTime_BSM" SG_ 2651930627 Digit_04_IPC 0;
BA_ "GenSigTimeoutTime_DIAG_TEST" SG_ 2651930627 Digit_04_IPC 0;
BA_ "GenSigTimeoutTime_ECM" SG_ 2651930627 Digit_04_IPC 0;
BA_ "GenSigTimeoutTime_EPS" SG_ 2651930627 Digit_04_IPC 0;
BA_ "GenSigTimeoutTime_IPC" SG_ 2651930627 Digit_04_IPC 0;
BA_ "GenSigTimeoutTime_MTA" SG_ 2651930627 Digit_04_IPC 0;
BA_ "GenSigTimeoutTime_ORC" SG_ 2651930627 Digit_04_IPC 0;
BA_ "GenSigTimeoutTime_PAM" SG_ 2651930627 Digit_04_IPC 0;
BA_ "GenSigTimeoutTime_BSM" SG_ 2651930627 Digit_05_IPC 0;
BA_ "GenSigTimeoutTime_DIAG_TEST" SG_ 2651930627 Digit_05_IPC 0;
BA_ "GenSigTimeoutTime_ECM" SG_ 2651930627 Digit_05_IPC 0;
BA_ "GenSigTimeoutTime_EPS" SG_ 2651930627 Digit_05_IPC 0;
BA_ "GenSigTimeoutTime_IPC" SG_ 2651930627 Digit_05_IPC 0;
BA_ "GenSigTimeoutTime_MTA" SG_ 2651930627 Digit_05_IPC 0;
BA_ "GenSigTimeoutTime_ORC" SG_ 2651930627 Digit_05_IPC 0;
BA_ "GenSigTimeoutTime_PAM" SG_ 2651930627 Digit_05_IPC 0;
BA_ "GenSigTimeoutTime_BSM" SG_ 2651930627 Digit_06_IPC 0;
BA_ "GenSigTimeoutTime_DIAG_TEST" SG_ 2651930627 Digit_06_IPC 0;
BA_ "GenSigTimeoutTime_ECM" SG_ 2651930627 Digit_06_IPC 0;
BA_ "GenSigTimeoutTime_EPS" SG_ 2651930627 Digit_06_IPC 0;
BA_ "GenSigTimeoutTime_IPC" SG_ 2651930627 Digit_06_IPC 0;
BA_ "GenSigTimeoutTime_MTA" SG_ 2651930627 Digit_06_IPC 0;
BA_ "GenSigTimeoutTime_ORC" SG_ 2651930627 Digit_06_IPC 0;
BA_ "GenSigTimeoutTime_PAM" SG_ 2651930627 Digit_06_IPC 0;
BA_ "GenSigTimeoutTime_BSM" SG_ 2651930627 Digit_07_IPC 0;
BA_ "GenSigTimeoutTime_DIAG_TEST" SG_ 2651930627 Digit_07_IPC 0;
BA_ "GenSigTimeoutTime_ECM" SG_ 2651930627 Digit_07_IPC 0;
BA_ "GenSigTimeoutTime_EPS" SG_ 2651930627 Digit_07_IPC 0;
BA_ "GenSigTimeoutTime_IPC" SG_ 2651930627 Digit_07_IPC 0;
BA_ "GenSigTimeoutTime_MTA" SG_ 2651930627 Digit_07_IPC 0;
BA_ "GenSigTimeoutTime_ORC" SG_ 2651930627 Digit_07_IPC 0;
BA_ "GenSigTimeoutTime_PAM" SG_ 2651930627 Digit_07_IPC 0;
BA_ "GenSigTimeoutTime_BSM" SG_ 2651930627 Digit_08_IPC 0;
BA_ "GenSigTimeoutTime_DIAG_TEST" SG_ 2651930627 Digit_08_IPC 0;
BA_ "GenSigTimeoutTime_ECM" SG_ 2651930627 Digit_08_IPC 0;
BA_ "GenSigTimeoutTime_EPS" SG_ 2651930627 Digit_08_IPC 0;
BA_ "GenSigTimeoutTime_IPC" SG_ 2651930627 Digit_08_IPC 0;
BA_ "GenSigTimeoutTime_MTA" SG_ 2651930627 Digit_08_IPC 0;
BA_ "GenSigTimeoutTime_ORC" SG_ 2651930627 Digit_08_IPC 0;
BA_ "GenSigTimeoutTime_PAM" SG_ 2651930627 Digit_08_IPC 0;
BA_ "GenSigTimeoutTime_BSM" SG_ 2651930627 Digit_09_IPC 0;
BA_ "GenSigTimeoutTime_DIAG_TEST" SG_ 2651930627 Digit_09_IPC 0;
BA_ "GenSigTimeoutTime_ECM" SG_ 2651930627 Digit_09_IPC 0;
BA_ "GenSigTimeoutTime_EPS" SG_ 2651930627 Digit_09_IPC 0;
BA_ "GenSigTimeoutTime_IPC" SG_ 2651930627 Digit_09_IPC 0;
BA_ "GenSigTimeoutTime_MTA" SG_ 2651930627 Digit_09_IPC 0;
BA_ "GenSigTimeoutTime_ORC" SG_ 2651930627 Digit_09_IPC 0;
BA_ "GenSigTimeoutTime_PAM" SG_ 2651930627 Digit_09_IPC 0;
BA_ "GenSigTimeoutTime_BSM" SG_ 2651930627 Digit_10_IPC 0;
BA_ "GenSigTimeoutTime_DIAG_TEST" SG_ 2651930627 Digit_10_IPC 0;
BA_ "GenSigTimeoutTime_ECM" SG_ 2651930627 Digit_10_IPC 0;
BA_ "GenSigTimeoutTime_EPS" SG_ 2651930627 Digit_10_IPC 0;
BA_ "GenSigTimeoutTime_IPC" SG_ 2651930627 Digit_10_IPC 0;
BA_ "GenSigTimeoutTime_MTA" SG_ 2651930627 Digit_10_IPC 0;
BA_ "GenSigTimeoutTime_ORC" SG_ 2651930627 Digit_10_IPC 0;
BA_ "GenSigTimeoutTime_PAM" SG_ 2651930627 Digit_10_IPC 0;
BA_ "GenSigTimeoutTime_BSM" SG_ 2651930627 Digit_11_IPC 0;
BA_ "GenSigTimeoutTime_DIAG_TEST" SG_ 2651930627 Digit_11_IPC 0;
BA_ "GenSigTimeoutTime_ECM" SG_ 2651930627 Digit_11_IPC 0;
BA_ "GenSigTimeoutTime_EPS" SG_ 2651930627 Digit_11_IPC 0;
BA_ "GenSigTimeoutTime_IPC" SG_ 2651930627 Digit_11_IPC 0;
BA_ "GenSigTimeoutTime_MTA" SG_ 2651930627 Digit_11_IPC 0;
BA_ "GenSigTimeoutTime_ORC" SG_ 2651930627 Digit_11_IPC 0;
BA_ "GenSigTimeoutTime_PAM" SG_ 2651930627 Digit_11_IPC 0;
BA_ "GenSigSendType" SG_ 2651930650 Digit_01_ORC 1;
BA_ "GenSigTimeoutTime_BSM" SG_ 2651930650 Digit_01_ORC 0;
BA_ "GenSigTimeoutTime_DIAG_TEST" SG_ 2651930650 Digit_01_ORC 0;
BA_ "GenSigTimeoutTime_ECM" SG_ 2651930650 Digit_01_ORC 0;
BA_ "GenSigTimeoutTime_EPS" SG_ 2651930650 Digit_01_ORC 0;
BA_ "GenSigTimeoutTime_IPC" SG_ 2651930650 Digit_01_ORC 0;
BA_ "GenSigTimeoutTime_MTA" SG_ 2651930650 Digit_01_ORC 0;
BA_ "GenSigTimeoutTime_ORC" SG_ 2651930650 Digit_01_ORC 0;
BA_ "GenSigTimeoutTime_PAM" SG_ 2651930650 Digit_01_ORC 0;
BA_ "GenSigTimeoutTime_BSM" SG_ 2651930650 Digit_02_ORC 0;
BA_ "GenSigTimeoutTime_DIAG_TEST" SG_ 2651930650 Digit_02_ORC 0;
BA_ "GenSigTimeoutTime_ECM" SG_ 2651930650 Digit_02_ORC 0;
BA_ "GenSigTimeoutTime_EPS" SG_ 2651930650 Digit_02_ORC 0;
BA_ "GenSigTimeoutTime_IPC" SG_ 2651930650 Digit_02_ORC 0;
BA_ "GenSigTimeoutTime_MTA" SG_ 2651930650 Digit_02_ORC 0;
BA_ "GenSigTimeoutTime_ORC" SG_ 2651930650 Digit_02_ORC 0;
BA_ "GenSigTimeoutTime_PAM" SG_ 2651930650 Digit_02_ORC 0;
BA_ "GenSigTimeoutTime_BSM" SG_ 2651930650 Digit_03_ORC 0;
BA_ "GenSigTimeoutTime_DIAG_TEST" SG_ 2651930650 Digit_03_ORC 0;
BA_ "GenSigTimeoutTime_ECM" SG_ 2651930650 Digit_03_ORC 0;
BA_ "GenSigTimeoutTime_EPS" SG_ 2651930650 Digit_03_ORC 0;
BA_ "GenSigTimeoutTime_IPC" SG_ 2651930650 Digit_03_ORC 0;
BA_ "GenSigTimeoutTime_MTA" SG_ 2651930650 Digit_03_ORC 0;
BA_ "GenSigTimeoutTime_ORC" SG_ 2651930650 Digit_03_ORC 0;
BA_ "GenSigTimeoutTime_PAM" SG_ 2651930650 Digit_03_ORC 0;
BA_ "GenSigTimeoutTime_BSM" SG_ 2651930650 Digit_04_ORC 0;
BA_ "GenSigTimeoutTime_DIAG_TEST" SG_ 2651930650 Digit_04_ORC 0;
BA_ "GenSigTimeoutTime_ECM" SG_ 2651930650 Digit_04_ORC 0;
BA_ "GenSigTimeoutTime_EPS" SG_ 2651930650 Digit_04_ORC 0;
BA_ "GenSigTimeoutTime_IPC" SG_ 2651930650 Digit_04_ORC 0;
BA_ "GenSigTimeoutTime_MTA" SG_ 2651930650 Digit_04_ORC 0;
BA_ "GenSigTimeoutTime_ORC" SG_ 2651930650 Digit_04_ORC 0;
BA_ "GenSigTimeoutTime_PAM" SG_ 2651930650 Digit_04_ORC 0;
BA_ "GenSigTimeoutTime_BSM" SG_ 2651930650 Digit_05_ORC 0;
BA_ "GenSigTimeoutTime_DIAG_TEST" SG_ 2651930650 Digit_05_ORC 0;
BA_ "GenSigTimeoutTime_ECM" SG_ 2651930650 Digit_05_ORC 0;
BA_ "GenSigTimeoutTime_EPS" SG_ 2651930650 Digit_05_ORC 0;
BA_ "GenSigTimeoutTime_IPC" SG_ 2651930650 Digit_05_ORC 0;
BA_ "GenSigTimeoutTime_MTA" SG_ 2651930650 Digit_05_ORC 0;
BA_ "GenSigTimeoutTime_ORC" SG_ 2651930650 Digit_05_ORC 0;
BA_ "GenSigTimeoutTime_PAM" SG_ 2651930650 Digit_05_ORC 0;
BA_ "GenSigTimeoutTime_BSM" SG_ 2651930650 Digit_06_ORC 0;
BA_ "GenSigTimeoutTime_DIAG_TEST" SG_ 2651930650 Digit_06_ORC 0;
BA_ "GenSigTimeoutTime_ECM" SG_ 2651930650 Digit_06_ORC 0;
BA_ "GenSigTimeoutTime_EPS" SG_ 2651930650 Digit_06_ORC 0;
BA_ "GenSigTimeoutTime_IPC" SG_ 2651930650 Digit_06_ORC 0;
BA_ "GenSigTimeoutTime_MTA" SG_ 2651930650 Digit_06_ORC 0;
BA_ "GenSigTimeoutTime_ORC" SG_ 2651930650 Digit_06_ORC 0;
BA_ "GenSigTimeoutTime_PAM" SG_ 2651930650 Digit_06_ORC 0;
BA_ "GenSigTimeoutTime_BSM" SG_ 2651930650 Digit_07_ORC 0;
BA_ "GenSigTimeoutTime_DIAG_TEST" SG_ 2651930650 Digit_07_ORC 0;
BA_ "GenSigTimeoutTime_ECM" SG_ 2651930650 Digit_07_ORC 0;
BA_ "GenSigTimeoutTime_EPS" SG_ 2651930650 Digit_07_ORC 0;
BA_ "GenSigTimeoutTime_IPC" SG_ 2651930650 Digit_07_ORC 0;
BA_ "GenSigTimeoutTime_MTA" SG_ 2651930650 Digit_07_ORC 0;
BA_ "GenSigTimeoutTime_ORC" SG_ 2651930650 Digit_07_ORC 0;
BA_ "GenSigTimeoutTime_PAM" SG_ 2651930650 Digit_07_ORC 0;
BA_ "GenSigTimeoutTime_BSM" SG_ 2651930650 Digit_08_ORC 0;
BA_ "GenSigTimeoutTime_DIAG_TEST" SG_ 2651930650 Digit_08_ORC 0;
BA_ "GenSigTimeoutTime_ECM" SG_ 2651930650 Digit_08_ORC 0;
BA_ "GenSigTimeoutTime_EPS" SG_ 2651930650 Digit_08_ORC 0;
BA_ "GenSigTimeoutTime_IPC" SG_ 2651930650 Digit_08_ORC 0;
BA_ "GenSigTimeoutTime_MTA" SG_ 2651930650 Digit_08_ORC 0;
BA_ "GenSigTimeoutTime_ORC" SG_ 2651930650 Digit_08_ORC 0;
BA_ "GenSigTimeoutTime_PAM" SG_ 2651930650 Digit_08_ORC 0;
BA_ "GenSigTimeoutTime_BSM" SG_ 2651930650 Digit_09_ORC 0;
BA_ "GenSigTimeoutTime_DIAG_TEST" SG_ 2651930650 Digit_09_ORC 0;
BA_ "GenSigTimeoutTime_ECM" SG_ 2651930650 Digit_09_ORC 0;
BA_ "GenSigTimeoutTime_EPS" SG_ 2651930650 Digit_09_ORC 0;
BA_ "GenSigTimeoutTime_IPC" SG_ 2651930650 Digit_09_ORC 0;
BA_ "GenSigTimeoutTime_MTA" SG_ 2651930650 Digit_09_ORC 0;
BA_ "GenSigTimeoutTime_ORC" SG_ 2651930650 Digit_09_ORC 0;
BA_ "GenSigTimeoutTime_PAM" SG_ 2651930650 Digit_09_ORC 0;
BA_ "GenSigTimeoutTime_BSM" SG_ 2651930650 Digit_10_ORC 0;
BA_ "GenSigTimeoutTime_DIAG_TEST" SG_ 2651930650 Digit_10_ORC 0;
BA_ "GenSigTimeoutTime_ECM" SG_ 2651930650 Digit_10_ORC 0;
BA_ "GenSigTimeoutTime_EPS" SG_ 2651930650 Digit_10_ORC 0;
BA_ "GenSigTimeoutTime_IPC" SG_ 2651930650 Digit_10_ORC 0;
BA_ "GenSigTimeoutTime_MTA" SG_ 2651930650 Digit_10_ORC 0;
BA_ "GenSigTimeoutTime_ORC" SG_ 2651930650 Digit_10_ORC 0;
BA_ "GenSigTimeoutTime_PAM" SG_ 2651930650 Digit_10_ORC 0;
BA_ "GenSigTimeoutTime_BSM" SG_ 2651930650 Digit_11_ORC 0;
BA_ "GenSigTimeoutTime_DIAG_TEST" SG_ 2651930650 Digit_11_ORC 0;
BA_ "GenSigTimeoutTime_ECM" SG_ 2651930650 Digit_11_ORC 0;
BA_ "GenSigTimeoutTime_EPS" SG_ 2651930650 Digit_11_ORC 0;
BA_ "GenSigTimeoutTime_IPC" SG_ 2651930650 Digit_11_ORC 0;
BA_ "GenSigTimeoutTime_MTA" SG_ 2651930650 Digit_11_ORC 0;
BA_ "GenSigTimeoutTime_ORC" SG_ 2651930650 Digit_11_ORC 0;
BA_ "GenSigTimeoutTime_PAM" SG_ 2651930650 Digit_11_ORC 0;
BA_ "GenSigSendType" SG_ 2651930648 Digit_01_PAM 1;
BA_ "GenSigTimeoutTime_BSM" SG_ 2651930648 Digit_01_PAM 0;
BA_ "GenSigTimeoutTime_DIAG_TEST" SG_ 2651930648 Digit_01_PAM 0;
BA_ "GenSigTimeoutTime_ECM" SG_ 2651930648 Digit_01_PAM 0;
BA_ "GenSigTimeoutTime_EPS" SG_ 2651930648 Digit_01_PAM 0;
BA_ "GenSigTimeoutTime_IPC" SG_ 2651930648 Digit_01_PAM 0;
BA_ "GenSigTimeoutTime_MTA" SG_ 2651930648 Digit_01_PAM 0;
BA_ "GenSigTimeoutTime_ORC" SG_ 2651930648 Digit_01_PAM 0;
BA_ "GenSigTimeoutTime_PAM" SG_ 2651930648 Digit_01_PAM 0;
BA_ "GenSigTimeoutTime_BSM" SG_ 2651930648 Digit_02_PAM 0;
BA_ "GenSigTimeoutTime_DIAG_TEST" SG_ 2651930648 Digit_02_PAM 0;
BA_ "GenSigTimeoutTime_ECM" SG_ 2651930648 Digit_02_PAM 0;
BA_ "GenSigTimeoutTime_EPS" SG_ 2651930648 Digit_02_PAM 0;
BA_ "GenSigTimeoutTime_IPC" SG_ 2651930648 Digit_02_PAM 0;
BA_ "GenSigTimeoutTime_MTA" SG_ 2651930648 Digit_02_PAM 0;
BA_ "GenSigTimeoutTime_ORC" SG_ 2651930648 Digit_02_PAM 0;
BA_ "GenSigTimeoutTime_PAM" SG_ 2651930648 Digit_02_PAM 0;
BA_ "GenSigTimeoutTime_BSM" SG_ 2651930648 Digit_03_PAM 0;
BA_ "GenSigTimeoutTime_DIAG_TEST" SG_ 2651930648 Digit_03_PAM 0;
BA_ "GenSigTimeoutTime_ECM" SG_ 2651930648 Digit_03_PAM 0;
BA_ "GenSigTimeoutTime_EPS" SG_ 2651930648 Digit_03_PAM 0;
BA_ "GenSigTimeoutTime_IPC" SG_ 2651930648 Digit_03_PAM 0;
BA_ "GenSigTimeoutTime_MTA" SG_ 2651930648 Digit_03_PAM 0;
BA_ "GenSigTimeoutTime_ORC" SG_ 2651930648 Digit_03_PAM 0;
BA_ "GenSigTimeoutTime_PAM" SG_ 2651930648 Digit_03_PAM 0;
BA_ "GenSigTimeoutTime_BSM" SG_ 2651930648 Digit_04_PAM 0;
BA_ "GenSigTimeoutTime_DIAG_TEST" SG_ 2651930648 Digit_04_PAM 0;
BA_ "GenSigTimeoutTime_ECM" SG_ 2651930648 Digit_04_PAM 0;
BA_ "GenSigTimeoutTime_EPS" SG_ 2651930648 Digit_04_PAM 0;
BA_ "GenSigTimeoutTime_IPC" SG_ 2651930648 Digit_04_PAM 0;
BA_ "GenSigTimeoutTime_MTA" SG_ 2651930648 Digit_04_PAM 0;
BA_ "GenSigTimeoutTime_ORC" SG_ 2651930648 Digit_04_PAM 0;
BA_ "GenSigTimeoutTime_PAM" SG_ 2651930648 Digit_04_PAM 0;
BA_ "GenSigTimeoutTime_BSM" SG_ 2651930648 Digit_05_PAM 0;
BA_ "GenSigTimeoutTime_DIAG_TEST" SG_ 2651930648 Digit_05_PAM 0;
BA_ "GenSigTimeoutTime_ECM" SG_ 2651930648 Digit_05_PAM 0;
BA_ "GenSigTimeoutTime_EPS" SG_ 2651930648 Digit_05_PAM 0;
BA_ "GenSigTimeoutTime_IPC" SG_ 2651930648 Digit_05_PAM 0;
BA_ "GenSigTimeoutTime_MTA" SG_ 2651930648 Digit_05_PAM 0;
BA_ "GenSigTimeoutTime_ORC" SG_ 2651930648 Digit_05_PAM 0;
BA_ "GenSigTimeoutTime_PAM" SG_ 2651930648 Digit_05_PAM 0;
BA_ "GenSigTimeoutTime_BSM" SG_ 2651930648 Digit_06_PAM 0;
BA_ "GenSigTimeoutTime_DIAG_TEST" SG_ 2651930648 Digit_06_PAM 0;
BA_ "GenSigTimeoutTime_ECM" SG_ 2651930648 Digit_06_PAM 0;
BA_ "GenSigTimeoutTime_EPS" SG_ 2651930648 Digit_06_PAM 0;
BA_ "GenSigTimeoutTime_IPC" SG_ 2651930648 Digit_06_PAM 0;
BA_ "GenSigTimeoutTime_MTA" SG_ 2651930648 Digit_06_PAM 0;
BA_ "GenSigTimeoutTime_ORC" SG_ 2651930648 Digit_06_PAM 0;
BA_ "GenSigTimeoutTime_PAM" SG_ 2651930648 Digit_06_PAM 0;
BA_ "GenSigTimeoutTime_BSM" SG_ 2651930648 Digit_07_PAM 0;
BA_ "GenSigTimeoutTime_DIAG_TEST" SG_ 2651930648 Digit_07_PAM 0;
BA_ "GenSigTimeoutTime_ECM" SG_ 2651930648 Digit_07_PAM 0;
BA_ "GenSigTimeoutTime_EPS" SG_ 2651930648 Digit_07_PAM 0;
BA_ "GenSigTimeoutTime_IPC" SG_ 2651930648 Digit_07_PAM 0;
BA_ "GenSigTimeoutTime_MTA" SG_ 2651930648 Digit_07_PAM 0;
BA_ "GenSigTimeoutTime_ORC" SG_ 2651930648 Digit_07_PAM 0;
BA_ "GenSigTimeoutTime_PAM" SG_ 2651930648 Digit_07_PAM 0;
BA_ "GenSigTimeoutTime_BSM" SG_ 2651930648 Digit_08_PAM 0;
BA_ "GenSigTimeoutTime_DIAG_TEST" SG_ 2651930648 Digit_08_PAM 0;
BA_ "GenSigTimeoutTime_ECM" SG_ 2651930648 Digit_08_PAM 0;
BA_ "GenSigTimeoutTime_EPS" SG_ 2651930648 Digit_08_PAM 0;
BA_ "GenSigTimeoutTime_IPC" SG_ 2651930648 Digit_08_PAM 0;
BA_ "GenSigTimeoutTime_MTA" SG_ 2651930648 Digit_08_PAM 0;
BA_ "GenSigTimeoutTime_ORC" SG_ 2651930648 Digit_08_PAM 0;
BA_ "GenSigTimeoutTime_PAM" SG_ 2651930648 Digit_08_PAM 0;
BA_ "GenSigTimeoutTime_BSM" SG_ 2651930648 Digit_09_PAM 0;
BA_ "GenSigTimeoutTime_DIAG_TEST" SG_ 2651930648 Digit_09_PAM 0;
BA_ "GenSigTimeoutTime_ECM" SG_ 2651930648 Digit_09_PAM 0;
BA_ "GenSigTimeoutTime_EPS" SG_ 2651930648 Digit_09_PAM 0;
BA_ "GenSigTimeoutTime_IPC" SG_ 2651930648 Digit_09_PAM 0;
BA_ "GenSigTimeoutTime_MTA" SG_ 2651930648 Digit_09_PAM 0;
BA_ "GenSigTimeoutTime_ORC" SG_ 2651930648 Digit_09_PAM 0;
BA_ "GenSigTimeoutTime_PAM" SG_ 2651930648 Digit_09_PAM 0;
BA_ "GenSigTimeoutTime_BSM" SG_ 2651930648 Digit_10_PAM 0;
BA_ "GenSigTimeoutTime_DIAG_TEST" SG_ 2651930648 Digit_10_PAM 0;
BA_ "GenSigTimeoutTime_ECM" SG_ 2651930648 Digit_10_PAM 0;
BA_ "GenSigTimeoutTime_EPS" SG_ 2651930648 Digit_10_PAM 0;
BA_ "GenSigTimeoutTime_IPC" SG_ 2651930648 Digit_10_PAM 0;
BA_ "GenSigTimeoutTime_MTA" SG_ 2651930648 Digit_10_PAM 0;
BA_ "GenSigTimeoutTime_ORC" SG_ 2651930648 Digit_10_PAM 0;
BA_ "GenSigTimeoutTime_PAM" SG_ 2651930648 Digit_10_PAM 0;
BA_ "GenSigTimeoutTime_BSM" SG_ 2651930648 Digit_11_PAM 0;
BA_ "GenSigTimeoutTime_DIAG_TEST" SG_ 2651930648 Digit_11_PAM 0;
BA_ "GenSigTimeoutTime_ECM" SG_ 2651930648 Digit_11_PAM 0;
BA_ "GenSigTimeoutTime_EPS" SG_ 2651930648 Digit_11_PAM 0;
BA_ "GenSigTimeoutTime_IPC" SG_ 2651930648 Digit_11_PAM 0;
BA_ "GenSigTimeoutTime_MTA" SG_ 2651930648 Digit_11_PAM 0;
BA_ "GenSigTimeoutTime_ORC" SG_ 2651930648 Digit_11_PAM 0;
BA_ "GenSigTimeoutTime_PAM" SG_ 2651930648 Digit_11_PAM 0;
BA_ "GenSigSendType" SG_ 2651930635 Digit_01_TRANSMISSION 1;
BA_ "GenSigTimeoutTime_BSM" SG_ 2651930635 Digit_01_TRANSMISSION 0;
BA_ "GenSigTimeoutTime_DIAG_TEST" SG_ 2651930635 Digit_01_TRANSMISSION 0;
BA_ "GenSigTimeoutTime_ECM" SG_ 2651930635 Digit_01_TRANSMISSION 0;
BA_ "GenSigTimeoutTime_EPS" SG_ 2651930635 Digit_01_TRANSMISSION 0;
BA_ "GenSigTimeoutTime_IPC" SG_ 2651930635 Digit_01_TRANSMISSION 0;
BA_ "GenSigTimeoutTime_MTA" SG_ 2651930635 Digit_01_TRANSMISSION 0;
BA_ "GenSigTimeoutTime_ORC" SG_ 2651930635 Digit_01_TRANSMISSION 0;
BA_ "GenSigTimeoutTime_PAM" SG_ 2651930635 Digit_01_TRANSMISSION 0;
BA_ "GenSigTimeoutTime_BSM" SG_ 2651930635 Digit_02_TRANSMISSION 0;
BA_ "GenSigTimeoutTime_DIAG_TEST" SG_ 2651930635 Digit_02_TRANSMISSION 0;
BA_ "GenSigTimeoutTime_ECM" SG_ 2651930635 Digit_02_TRANSMISSION 0;
BA_ "GenSigTimeoutTime_EPS" SG_ 2651930635 Digit_02_TRANSMISSION 0;
BA_ "GenSigTimeoutTime_IPC" SG_ 2651930635 Digit_02_TRANSMISSION 0;
BA_ "GenSigTimeoutTime_MTA" SG_ 2651930635 Digit_02_TRANSMISSION 0;
BA_ "GenSigTimeoutTime_ORC" SG_ 2651930635 Digit_02_TRANSMISSION 0;
BA_ "GenSigTimeoutTime_PAM" SG_ 2651930635 Digit_02_TRANSMISSION 0;
BA_ "GenSigTimeoutTime_BSM" SG_ 2651930635 Digit_03_TRANSMISSION 0;
BA_ "GenSigTimeoutTime_DIAG_TEST" SG_ 2651930635 Digit_03_TRANSMISSION 0;
BA_ "GenSigTimeoutTime_ECM" SG_ 2651930635 Digit_03_TRANSMISSION 0;
BA_ "GenSigTimeoutTime_EPS" SG_ 2651930635 Digit_03_TRANSMISSION 0;
BA_ "GenSigTimeoutTime_IPC" SG_ 2651930635 Digit_03_TRANSMISSION 0;
BA_ "GenSigTimeoutTime_MTA" SG_ 2651930635 Digit_03_TRANSMISSION 0;
BA_ "GenSigTimeoutTime_ORC" SG_ 2651930635 Digit_03_TRANSMISSION 0;
BA_ "GenSigTimeoutTime_PAM" SG_ 2651930635 Digit_03_TRANSMISSION 0;
BA_ "GenSigTimeoutTime_BSM" SG_ 2651930635 Digit_04_TRANSMISSION 0;
BA_ "GenSigTimeoutTime_DIAG_TEST" SG_ 2651930635 Digit_04_TRANSMISSION 0;
BA_ "GenSigTimeoutTime_ECM" SG_ 2651930635 Digit_04_TRANSMISSION 0;
BA_ "GenSigTimeoutTime_EPS" SG_ 2651930635 Digit_04_TRANSMISSION 0;
BA_ "GenSigTimeoutTime_IPC" SG_ 2651930635 Digit_04_TRANSMISSION 0;
BA_ "GenSigTimeoutTime_MTA" SG_ 2651930635 Digit_04_TRANSMISSION 0;
BA_ "GenSigTimeoutTime_ORC" SG_ 2651930635 Digit_04_TRANSMISSION 0;
BA_ "GenSigTimeoutTime_PAM" SG_ 2651930635 Digit_04_TRANSMISSION 0;
BA_ "GenSigTimeoutTime_BSM" SG_ 2651930635 Digit_05_TRANSMISSION 0;
BA_ "GenSigTimeoutTime_DIAG_TEST" SG_ 2651930635 Digit_05_TRANSMISSION 0;
BA_ "GenSigTimeoutTime_ECM" SG_ 2651930635 Digit_05_TRANSMISSION 0;
BA_ "GenSigTimeoutTime_EPS" SG_ 2651930635 Digit_05_TRANSMISSION 0;
BA_ "GenSigTimeoutTime_IPC" SG_ 2651930635 Digit_05_TRANSMISSION 0;
BA_ "GenSigTimeoutTime_MTA" SG_ 2651930635 Digit_05_TRANSMISSION 0;
BA_ "GenSigTimeoutTime_ORC" SG_ 2651930635 Digit_05_TRANSMISSION 0;
BA_ "GenSigTimeoutTime_PAM" SG_ 2651930635 Digit_05_TRANSMISSION 0;
BA_ "GenSigTimeoutTime_BSM" SG_ 2651930635 Digit_06_TRANSMISSION 0;
BA_ "GenSigTimeoutTime_DIAG_TEST" SG_ 2651930635 Digit_06_TRANSMISSION 0;
BA_ "GenSigTimeoutTime_ECM" SG_ 2651930635 Digit_06_TRANSMISSION 0;
BA_ "GenSigTimeoutTime_EPS" SG_ 2651930635 Digit_06_TRANSMISSION 0;
BA_ "GenSigTimeoutTime_IPC" SG_ 2651930635 Digit_06_TRANSMISSION 0;
BA_ "GenSigTimeoutTime_MTA" SG_ 2651930635 Digit_06_TRANSMISSION 0;
BA_ "GenSigTimeoutTime_ORC" SG_ 2651930635 Digit_06_TRANSMISSION 0;
BA_ "GenSigTimeoutTime_PAM" SG_ 2651930635 Digit_06_TRANSMISSION 0;
BA_ "GenSigTimeoutTime_BSM" SG_ 2651930635 Digit_07_TRANSMISSION 0;
BA_ "GenSigTimeoutTime_DIAG_TEST" SG_ 2651930635 Digit_07_TRANSMISSION 0;
BA_ "GenSigTimeoutTime_ECM" SG_ 2651930635 Digit_07_TRANSMISSION 0;
BA_ "GenSigTimeoutTime_EPS" SG_ 2651930635 Digit_07_TRANSMISSION 0;
BA_ "GenSigTimeoutTime_IPC" SG_ 2651930635 Digit_07_TRANSMISSION 0;
BA_ "GenSigTimeoutTime_MTA" SG_ 2651930635 Digit_07_TRANSMISSION 0;
BA_ "GenSigTimeoutTime_ORC" SG_ 2651930635 Digit_07_TRANSMISSION 0;
BA_ "GenSigTimeoutTime_PAM" SG_ 2651930635 Digit_07_TRANSMISSION 0;
BA_ "GenSigTimeoutTime_BSM" SG_ 2651930635 Digit_08_TRANSMISSION 0;
BA_ "GenSigTimeoutTime_DIAG_TEST" SG_ 2651930635 Digit_08_TRANSMISSION 0;
BA_ "GenSigTimeoutTime_ECM" SG_ 2651930635 Digit_08_TRANSMISSION 0;
BA_ "GenSigTimeoutTime_EPS" SG_ 2651930635 Digit_08_TRANSMISSION 0;
BA_ "GenSigTimeoutTime_IPC" SG_ 2651930635 Digit_08_TRANSMISSION 0;
BA_ "GenSigTimeoutTime_MTA" SG_ 2651930635 Digit_08_TRANSMISSION 0;
BA_ "GenSigTimeoutTime_ORC" SG_ 2651930635 Digit_08_TRANSMISSION 0;
BA_ "GenSigTimeoutTime_PAM" SG_ 2651930635 Digit_08_TRANSMISSION 0;
BA_ "GenSigTimeoutTime_BSM" SG_ 2651930635 Digit_09_TRANSMISSION 0;
BA_ "GenSigTimeoutTime_DIAG_TEST" SG_ 2651930635 Digit_09_TRANSMISSION 0;
BA_ "GenSigTimeoutTime_ECM" SG_ 2651930635 Digit_09_TRANSMISSION 0;
BA_ "GenSigTimeoutTime_EPS" SG_ 2651930635 Digit_09_TRANSMISSION 0;
BA_ "GenSigTimeoutTime_IPC" SG_ 2651930635 Digit_09_TRANSMISSION 0;
BA_ "GenSigTimeoutTime_MTA" SG_ 2651930635 Digit_09_TRANSMISSION 0;
BA_ "GenSigTimeoutTime_ORC" SG_ 2651930635 Digit_09_TRANSMISSION 0;
BA_ "GenSigTimeoutTime_PAM" SG_ 2651930635 Digit_09_TRANSMISSION 0;
BA_ "GenSigTimeoutTime_BSM" SG_ 2651930635 Digit_10_TRANSMISSION 0;
BA_ "GenSigTimeoutTime_DIAG_TEST" SG_ 2651930635 Digit_10_TRANSMISSION 0;
BA_ "GenSigTimeoutTime_ECM" SG_ 2651930635 Digit_10_TRANSMISSION 0;
BA_ "GenSigTimeoutTime_EPS" SG_ 2651930635 Digit_10_TRANSMISSION 0;
BA_ "GenSigTimeoutTime_IPC" SG_ 2651930635 Digit_10_TRANSMISSION 0;
BA_ "GenSigTimeoutTime_MTA" SG_ 2651930635 Digit_10_TRANSMISSION 0;
BA_ "GenSigTimeoutTime_ORC" SG_ 2651930635 Digit_10_TRANSMISSION 0;
BA_ "GenSigTimeoutTime_PAM" SG_ 2651930635 Digit_10_TRANSMISSION 0;
BA_ "GenSigTimeoutTime_BSM" SG_ 2651930635 Digit_11_TRANSMISSION 0;
BA_ "GenSigTimeoutTime_DIAG_TEST" SG_ 2651930635 Digit_11_TRANSMISSION 0;
BA_ "GenSigTimeoutTime_ECM" SG_ 2651930635 Digit_11_TRANSMISSION 0;
BA_ "GenSigTimeoutTime_EPS" SG_ 2651930635 Digit_11_TRANSMISSION 0;
BA_ "GenSigTimeoutTime_IPC" SG_ 2651930635 Digit_11_TRANSMISSION 0;
BA_ "GenSigTimeoutTime_MTA" SG_ 2651930635 Digit_11_TRANSMISSION 0;
BA_ "GenSigTimeoutTime_ORC" SG_ 2651930635 Digit_11_TRANSMISSION 0;
BA_ "GenSigTimeoutTime_PAM" SG_ 2651930635 Digit_11_TRANSMISSION 0;
BA_ "GenSigTimeoutTime_BCM" SG_ 2564440308 N_PDU 0;
BA_ "GenSigTimeoutTime_BSM" SG_ 2564440308 N_PDU 0;
BA_ "GenSigTimeoutTime_DIAG_TEST" SG_ 2564440308 N_PDU 0;
BA_ "GenSigTimeoutTime_ECM" SG_ 2564440308 N_PDU 0;
BA_ "GenSigTimeoutTime_EPS" SG_ 2564440308 N_PDU 0;
BA_ "GenSigTimeoutTime_IPC" SG_ 2564440308 N_PDU 0;
BA_ "GenSigTimeoutTime_MTA" SG_ 2564440308 N_PDU 0;
BA_ "GenSigTimeoutTime_ORC" SG_ 2564440308 N_PDU 0;
BA_ "GenSigTimeoutTime_PAM" SG_ 2564440308 N_PDU 0;
BA_ "GenSigTimeoutTime_BCM" SG_ 2564434164 N_PDU 0;
BA_ "GenSigTimeoutTime_BSM" SG_ 2564434164 N_PDU 0;
BA_ "GenSigTimeoutTime_DIAG_TEST" SG_ 2564434164 N_PDU 0;
BA_ "GenSigTimeoutTime_ECM" SG_ 2564434164 N_PDU 0;
BA_ "GenSigTimeoutTime_EPS" SG_ 2564434164 N_PDU 0;
BA_ "GenSigTimeoutTime_IPC" SG_ 2564434164 N_PDU 0;
BA_ "GenSigTimeoutTime_MTA" SG_ 2564434164 N_PDU 0;
BA_ "GenSigTimeoutTime_ORC" SG_ 2564434164 N_PDU 0;
BA_ "GenSigTimeoutTime_PAM" SG_ 2564434164 N_PDU 0;
BA_ "GenSigTimeoutTime_BCM" SG_ 2564428020 N_PDU 0;
BA_ "GenSigTimeoutTime_BSM" SG_ 2564428020 N_PDU 0;
BA_ "GenSigTimeoutTime_DIAG_TEST" SG_ 2564428020 N_PDU 0;
BA_ "GenSigTimeoutTime_ECM" SG_ 2564428020 N_PDU 0;
BA_ "GenSigTimeoutTime_EPS" SG_ 2564428020 N_PDU 0;
BA_ "GenSigTimeoutTime_IPC" SG_ 2564428020 N_PDU 0;
BA_ "GenSigTimeoutTime_MTA" SG_ 2564428020 N_PDU 0;
BA_ "GenSigTimeoutTime_ORC" SG_ 2564428020 N_PDU 0;
BA_ "GenSigTimeoutTime_PAM" SG_ 2564428020 N_PDU 0;
BA_ "GenSigTimeoutTime_BCM" SG_ 2564428017 N_PDU 0;
BA_ "GenSigTimeoutTime_BSM" SG_ 2564428017 N_PDU 0;
BA_ "GenSigTimeoutTime_DIAG_TEST" SG_ 2564428017 N_PDU 0;
BA_ "GenSigTimeoutTime_ECM" SG_ 2564428017 N_PDU 0;
BA_ "GenSigTimeoutTime_EPS" SG_ 2564428017 N_PDU 0;
BA_ "GenSigTimeoutTime_IPC" SG_ 2564428017 N_PDU 0;
BA_ "GenSigTimeoutTime_MTA" SG_ 2564428017 N_PDU 0;
BA_ "GenSigTimeoutTime_ORC" SG_ 2564428017 N_PDU 0;
BA_ "GenSigTimeoutTime_PAM" SG_ 2564428017 N_PDU 0;
BA_ "GenSigTimeoutTime_BCM" SG_ 2564436212 N_PDU 0;
BA_ "GenSigTimeoutTime_BSM" SG_ 2564436212 N_PDU 0;
BA_ "GenSigTimeoutTime_DIAG_TEST" SG_ 2564436212 N_PDU 0;
BA_ "GenSigTimeoutTime_ECM" SG_ 2564436212 N_PDU 0;
BA_ "GenSigTimeoutTime_EPS" SG_ 2564436212 N_PDU 0;
BA_ "GenSigTimeoutTime_IPC" SG_ 2564436212 N_PDU 0;
BA_ "GenSigTimeoutTime_MTA" SG_ 2564436212 N_PDU 0;
BA_ "GenSigTimeoutTime_ORC" SG_ 2564436212 N_PDU 0;
BA_ "GenSigTimeoutTime_PAM" SG_ 2564436212 N_PDU 0;
BA_ "GenSigTimeoutTime_BCM" SG_ 2564502513 N_PDU 0;
BA_ "GenSigTimeoutTime_BSM" SG_ 2564502513 N_PDU 0;
BA_ "GenSigTimeoutTime_DIAG_TEST" SG_ 2564502513 N_PDU 0;
BA_ "GenSigTimeoutTime_ECM" SG_ 2564502513 N_PDU 0;
BA_ "GenSigTimeoutTime_EPS" SG_ 2564502513 N_PDU 0;
BA_ "GenSigTimeoutTime_IPC" SG_ 2564502513 N_PDU 0;
BA_ "GenSigTimeoutTime_MTA" SG_ 2564502513 N_PDU 0;
BA_ "GenSigTimeoutTime_ORC" SG_ 2564502513 N_PDU 0;
BA_ "GenSigTimeoutTime_PAM" SG_ 2564502513 N_PDU 0;
BA_ "GenSigTimeoutTime_BCM" SG_ 2564554484 N_PDU 0;
BA_ "GenSigTimeoutTime_BSM" SG_ 2564554484 N_PDU 0;
BA_ "GenSigTimeoutTime_DIAG_TEST" SG_ 2564554484 N_PDU 0;
BA_ "GenSigTimeoutTime_ECM" SG_ 2564554484 N_PDU 0;
BA_ "GenSigTimeoutTime_EPS" SG_ 2564554484 N_PDU 0;
BA_ "GenSigTimeoutTime_IPC" SG_ 2564554484 N_PDU 0;
BA_ "GenSigTimeoutTime_MTA" SG_ 2564554484 N_PDU 0;
BA_ "GenSigTimeoutTime_ORC" SG_ 2564554484 N_PDU 0;
BA_ "GenSigTimeoutTime_PAM" SG_ 2564554484 N_PDU 0;
BA_ "GenSigTimeoutTime_BCM" SG_ 2564448500 N_PDU 0;
BA_ "GenSigTimeoutTime_BSM" SG_ 2564448500 N_PDU 0;
BA_ "GenSigTimeoutTime_DIAG_TEST" SG_ 2564448500 N_PDU 0;
BA_ "GenSigTimeoutTime_ECM" SG_ 2564448500 N_PDU 0;
BA_ "GenSigTimeoutTime_EPS" SG_ 2564448500 N_PDU 0;
BA_ "GenSigTimeoutTime_IPC" SG_ 2564448500 N_PDU 0;
BA_ "GenSigTimeoutTime_MTA" SG_ 2564448500 N_PDU 0;
BA_ "GenSigTimeoutTime_ORC" SG_ 2564448500 N_PDU 0;
BA_ "GenSigTimeoutTime_PAM" SG_ 2564448500 N_PDU 0;
BA_ "GenSigTimeoutTime_BCM" SG_ 2564473076 N_PDU 0;
BA_ "GenSigTimeoutTime_BSM" SG_ 2564473076 N_PDU 0;
BA_ "GenSigTimeoutTime_DIAG_TEST" SG_ 2564473076 N_PDU 0;
BA_ "GenSigTimeoutTime_ECM" SG_ 2564473076 N_PDU 0;
BA_ "GenSigTimeoutTime_EPS" SG_ 2564473076 N_PDU 0;
BA_ "GenSigTimeoutTime_IPC" SG_ 2564473076 N_PDU 0;
BA_ "GenSigTimeoutTime_MTA" SG_ 2564473076 N_PDU 0;
BA_ "GenSigTimeoutTime_ORC" SG_ 2564473076 N_PDU 0;
BA_ "GenSigTimeoutTime_PAM" SG_ 2564473076 N_PDU 0;
BA_ "GenSigTimeoutTime_BCM" SG_ 2564464884 N_PDU 0;
BA_ "GenSigTimeoutTime_BSM" SG_ 2564464884 N_PDU 0;
BA_ "GenSigTimeoutTime_DIAG_TEST" SG_ 2564464884 N_PDU 0;
BA_ "GenSigTimeoutTime_ECM" SG_ 2564464884 N_PDU 0;
BA_ "GenSigTimeoutTime_EPS" SG_ 2564464884 N_PDU 0;
BA_ "GenSigTimeoutTime_IPC" SG_ 2564464884 N_PDU 0;
BA_ "GenSigTimeoutTime_MTA" SG_ 2564464884 N_PDU 0;
BA_ "GenSigTimeoutTime_ORC" SG_ 2564464884 N_PDU 0;
BA_ "GenSigTimeoutTime_PAM" SG_ 2564464884 N_PDU 0;
BA_ "GenSigTimeoutTime_BCM" SG_ 2564430068 N_PDU 0;
BA_ "GenSigTimeoutTime_BSM" SG_ 2564430068 N_PDU 0;
BA_ "GenSigTimeoutTime_DIAG_TEST" SG_ 2564430068 N_PDU 0;
BA_ "GenSigTimeoutTime_ECM" SG_ 2564430068 N_PDU 0;
BA_ "GenSigTimeoutTime_EPS" SG_ 2564430068 N_PDU 0;
BA_ "GenSigTimeoutTime_IPC" SG_ 2564430068 N_PDU 0;
BA_ "GenSigTimeoutTime_MTA" SG_ 2564430068 N_PDU 0;
BA_ "GenSigTimeoutTime_ORC" SG_ 2564430068 N_PDU 0;
BA_ "GenSigTimeoutTime_PAM" SG_ 2564430068 N_PDU 0;
BA_ "GenSigTimeoutTime_BCM" SG_ 2564486208 N_PDU 0;
BA_ "GenSigTimeoutTime_BSM" SG_ 2564486208 N_PDU 0;
BA_ "GenSigTimeoutTime_DIAG_TEST" SG_ 2564486208 N_PDU 0;
BA_ "GenSigTimeoutTime_ECM" SG_ 2564486208 N_PDU 0;
BA_ "GenSigTimeoutTime_EPS" SG_ 2564486208 N_PDU 0;
BA_ "GenSigTimeoutTime_IPC" SG_ 2564486208 N_PDU 0;
BA_ "GenSigTimeoutTime_MTA" SG_ 2564486208 N_PDU 0;
BA_ "GenSigTimeoutTime_ORC" SG_ 2564486208 N_PDU 0;
BA_ "GenSigTimeoutTime_PAM" SG_ 2564486208 N_PDU 0;
BA_ "GenSigTimeoutTime_BCM" SG_ 2564486184 N_PDU 0;
BA_ "GenSigTimeoutTime_BSM" SG_ 2564486184 N_PDU 0;
BA_ "GenSigTimeoutTime_DIAG_TEST" SG_ 2564486184 N_PDU 0;
BA_ "GenSigTimeoutTime_ECM" SG_ 2564486184 N_PDU 0;
BA_ "GenSigTimeoutTime_EPS" SG_ 2564486184 N_PDU 0;
BA_ "GenSigTimeoutTime_IPC" SG_ 2564486184 N_PDU 0;
BA_ "GenSigTimeoutTime_MTA" SG_ 2564486184 N_PDU 0;
BA_ "GenSigTimeoutTime_ORC" SG_ 2564486184 N_PDU 0;
BA_ "GenSigTimeoutTime_PAM" SG_ 2564486184 N_PDU 0;
BA_ "GenSigTimeoutTime_BCM" SG_ 2564486160 N_PDU 0;
BA_ "GenSigTimeoutTime_BSM" SG_ 2564486160 N_PDU 0;
BA_ "GenSigTimeoutTime_DIAG_TEST" SG_ 2564486160 N_PDU 0;
BA_ "GenSigTimeoutTime_ECM" SG_ 2564486160 N_PDU 0;
BA_ "GenSigTimeoutTime_EPS" SG_ 2564486160 N_PDU 0;
BA_ "GenSigTimeoutTime_IPC" SG_ 2564486160 N_PDU 0;
BA_ "GenSigTimeoutTime_MTA" SG_ 2564486160 N_PDU 0;
BA_ "GenSigTimeoutTime_ORC" SG_ 2564486160 N_PDU 0;
BA_ "GenSigTimeoutTime_PAM" SG_ 2564486160 N_PDU 0;
BA_ "GenSigTimeoutTime_BCM" SG_ 2564485392 N_PDU 0;
BA_ "GenSigTimeoutTime_BSM" SG_ 2564485392 N_PDU 0;
BA_ "GenSigTimeoutTime_DIAG_TEST" SG_ 2564485392 N_PDU 0;
BA_ "GenSigTimeoutTime_ECM" SG_ 2564485392 N_PDU 0;
BA_ "GenSigTimeoutTime_EPS" SG_ 2564485392 N_PDU 0;
BA_ "GenSigTimeoutTime_IPC" SG_ 2564485392 N_PDU 0;
BA_ "GenSigTimeoutTime_MTA" SG_ 2564485392 N_PDU 0;
BA_ "GenSigTimeoutTime_ORC" SG_ 2564485392 N_PDU 0;
BA_ "GenSigTimeoutTime_PAM" SG_ 2564485392 N_PDU 0;
BA_ "GenSigTimeoutTime_BCM" SG_ 2564486192 N_PDU 0;
BA_ "GenSigTimeoutTime_BSM" SG_ 2564486192 N_PDU 0;
BA_ "GenSigTimeoutTime_DIAG_TEST" SG_ 2564486192 N_PDU 0;
BA_ "GenSigTimeoutTime_ECM" SG_ 2564486192 N_PDU 0;
BA_ "GenSigTimeoutTime_EPS" SG_ 2564486192 N_PDU 0;
BA_ "GenSigTimeoutTime_IPC" SG_ 2564486192 N_PDU 0;
BA_ "GenSigTimeoutTime_MTA" SG_ 2564486192 N_PDU 0;
BA_ "GenSigTimeoutTime_ORC" SG_ 2564486192 N_PDU 0;
BA_ "GenSigTimeoutTime_PAM" SG_ 2564486192 N_PDU 0;
BA_ "GenSigTimeoutTime_BCM" SG_ 2564486240 N_PDU 0;
BA_ "GenSigTimeoutTime_BSM" SG_ 2564486240 N_PDU 0;
BA_ "GenSigTimeoutTime_DIAG_TEST" SG_ 2564486240 N_PDU 0;
BA_ "GenSigTimeoutTime_ECM" SG_ 2564486240 N_PDU 0;
BA_ "GenSigTimeoutTime_EPS" SG_ 2564486240 N_PDU 0;
BA_ "GenSigTimeoutTime_IPC" SG_ 2564486240 N_PDU 0;
BA_ "GenSigTimeoutTime_MTA" SG_ 2564486240 N_PDU 0;
BA_ "GenSigTimeoutTime_ORC" SG_ 2564486240 N_PDU 0;
BA_ "GenSigTimeoutTime_PAM" SG_ 2564486240 N_PDU 0;
BA_ "GenSigTimeoutTime_BCM" SG_ 2564486336 N_PDU 0;
BA_ "GenSigTimeoutTime_BSM" SG_ 2564486336 N_PDU 0;
BA_ "GenSigTimeoutTime_DIAG_TEST" SG_ 2564486336 N_PDU 0;
BA_ "GenSigTimeoutTime_ECM" SG_ 2564486336 N_PDU 0;
BA_ "GenSigTimeoutTime_EPS" SG_ 2564486336 N_PDU 0;
BA_ "GenSigTimeoutTime_IPC" SG_ 2564486336 N_PDU 0;
BA_ "GenSigTimeoutTime_MTA" SG_ 2564486336 N_PDU 0;
BA_ "GenSigTimeoutTime_ORC" SG_ 2564486336 N_PDU 0;
BA_ "GenSigTimeoutTime_PAM" SG_ 2564486336 N_PDU 0;
BA_ "GenSigTimeoutTime_BCM" SG_ 2564486304 N_PDU 0;
BA_ "GenSigTimeoutTime_BSM" SG_ 2564486304 N_PDU 0;
BA_ "GenSigTimeoutTime_DIAG_TEST" SG_ 2564486304 N_PDU 0;
BA_ "GenSigTimeoutTime_ECM" SG_ 2564486304 N_PDU 0;
BA_ "GenSigTimeoutTime_EPS" SG_ 2564486304 N_PDU 0;
BA_ "GenSigTimeoutTime_IPC" SG_ 2564486304 N_PDU 0;
BA_ "GenSigTimeoutTime_MTA" SG_ 2564486304 N_PDU 0;
BA_ "GenSigTimeoutTime_ORC" SG_ 2564486304 N_PDU 0;
BA_ "GenSigTimeoutTime_PAM" SG_ 2564486304 N_PDU 0;
BA_ "GenSigTimeoutTime_BCM" SG_ 2564486168 N_PDU 0;
BA_ "GenSigTimeoutTime_BSM" SG_ 2564486168 N_PDU 0;
BA_ "GenSigTimeoutTime_DIAG_TEST" SG_ 2564486168 N_PDU 0;
BA_ "GenSigTimeoutTime_ECM" SG_ 2564486168 N_PDU 0;
BA_ "GenSigTimeoutTime_EPS" SG_ 2564486168 N_PDU 0;
BA_ "GenSigTimeoutTime_IPC" SG_ 2564486168 N_PDU 0;
BA_ "GenSigTimeoutTime_MTA" SG_ 2564486168 N_PDU 0;
BA_ "GenSigTimeoutTime_ORC" SG_ 2564486168 N_PDU 0;
BA_ "GenSigTimeoutTime_PAM" SG_ 2564486168 N_PDU 0;
BA_ "GenSigTimeoutTime_BSM" SG_ 222 ElectricSteeringFailSts 0;
BA_ "GenSigTimeoutTime_DIAG_TEST" SG_ 222 ElectricSteeringFailSts 0;
BA_ "GenSigTimeoutTime_ECM" SG_ 222 ElectricSteeringFailSts 0;
BA_ "GenSigTimeoutTime_EPS" SG_ 222 ElectricSteeringFailSts 0;
BA_ "GenSigTimeoutTime_MTA" SG_ 222 ElectricSteeringFailSts 0;
BA_ "GenSigTimeoutTime_ORC" SG_ 222 ElectricSteeringFailSts 0;
BA_ "GenSigTimeoutTime_PAM" SG_ 222 ElectricSteeringFailSts 0;
BA_ "GenSigTimeoutTime_BCM" SG_ 222 LwsAngle 0;
BA_ "GenSigTimeoutTime_DIAG_TEST" SG_ 222 LwsAngle 0;
BA_ "GenSigTimeoutTime_ECM" SG_ 222 LwsAngle 0;
BA_ "GenSigTimeoutTime_EPS" SG_ 222 LwsAngle 0;
BA_ "GenSigTimeoutTime_IPC" SG_ 222 LwsAngle 0;
BA_ "GenSigTimeoutTime_MTA" SG_ 222 LwsAngle 0;
BA_ "GenSigTimeoutTime_ORC" SG_ 222 LwsAngle 0;
BA_ "GenSigTimeoutTime_PAM" SG_ 222 LwsAngle 0;
BA_ "GenSigTimeoutTime_BCM" SG_ 222 LwsAngleType 0;
BA_ "GenSigTimeoutTime_DIAG_TEST" SG_ 222 LwsAngleType 0;
BA_ "GenSigTimeoutTime_ECM" SG_ 222 LwsAngleType 0;
BA_ "GenSigTimeoutTime_EPS" SG_ 222 LwsAngleType 0;
BA_ "GenSigTimeoutTime_IPC" SG_ 222 LwsAngleType 0;
BA_ "GenSigTimeoutTime_MTA" SG_ 222 LwsAngleType 0;
BA_ "GenSigTimeoutTime_ORC" SG_ 222 LwsAngleType 0;
BA_ "GenSigTimeoutTime_PAM" SG_ 222 LwsAngleType 0;
BA_ "GenSigTimeoutTime_BCM" SG_ 222 LwsCalibration 0;
BA_ "GenSigTimeoutTime_DIAG_TEST" SG_ 222 LwsCalibration 0;
BA_ "GenSigTimeoutTime_ECM" SG_ 222 LwsCalibration 0;
BA_ "GenSigTimeoutTime_EPS" SG_ 222 LwsCalibration 0;
BA_ "GenSigTimeoutTime_IPC" SG_ 222 LwsCalibration 0;
BA_ "GenSigTimeoutTime_MTA" SG_ 222 LwsCalibration 0;
BA_ "GenSigTimeoutTime_ORC" SG_ 222 LwsCalibration 0;
BA_ "GenSigTimeoutTime_PAM" SG_ 222 LwsCalibration 0;
BA_ "GenSigTimeoutTime_BCM" SG_ 222 LWSFailSts 0;
BA_ "GenSigTimeoutTime_DIAG_TEST" SG_ 222 LWSFailSts 0;
BA_ "GenSigTimeoutTime_ECM" SG_ 222 LWSFailSts 0;
BA_ "GenSigTimeoutTime_EPS" SG_ 222 LWSFailSts 0;
BA_ "GenSigTimeoutTime_IPC" SG_ 222 LWSFailSts 0;
BA_ "GenSigTimeoutTime_MTA" SG_ 222 LWSFailSts 0;
BA_ "GenSigTimeoutTime_ORC" SG_ 222 LWSFailSts 0;
BA_ "GenSigTimeoutTime_PAM" SG_ 222 LWSFailSts 0;
BA_ "GenSigTimeoutTime_BCM" SG_ 222 LwsSpeed 0;
BA_ "GenSigTimeoutTime_BSM" SG_ 222 LwsSpeed 0;
BA_ "GenSigTimeoutTime_DIAG_TEST" SG_ 222 LwsSpeed 0;
BA_ "GenSigTimeoutTime_ECM" SG_ 222 LwsSpeed 0;
BA_ "GenSigTimeoutTime_EPS" SG_ 222 LwsSpeed 0;
BA_ "GenSigTimeoutTime_IPC" SG_ 222 LwsSpeed 0;
BA_ "GenSigTimeoutTime_MTA" SG_ 222 LwsSpeed 0;
BA_ "GenSigTimeoutTime_ORC" SG_ 222 LwsSpeed 0;
BA_ "GenSigTimeoutTime_PAM" SG_ 222 LwsSpeed 0;
BA_ "GenSigStartValue" SG_ 222 SteeringLoad 1;
BA_ "GenSigTimeoutTime_BCM" SG_ 222 SteeringLoad 0;
BA_ "GenSigTimeoutTime_BSM" SG_ 222 SteeringLoad 0;
BA_ "GenSigTimeoutTime_DIAG_TEST" SG_ 222 SteeringLoad 0;
BA_ "GenSigTimeoutTime_ECM" SG_ 222 SteeringLoad 0;
BA_ "GenSigTimeoutTime_EPS" SG_ 222 SteeringLoad 0;
BA_ "GenSigTimeoutTime_IPC" SG_ 222 SteeringLoad 0;
BA_ "GenSigTimeoutTime_MTA" SG_ 222 SteeringLoad 0;
BA_ "GenSigTimeoutTime_ORC" SG_ 222 SteeringLoad 0;
BA_ "GenSigTimeoutTime_PAM" SG_ 222 SteeringLoad 0;
BA_ "GenSigSendType" SG_ 100 ControlEncodingReq 1;
BA_ "GenSigTimeoutTime_BSM" SG_ 100 ControlEncodingReq 0;
BA_ "GenSigTimeoutTime_DIAG_TEST" SG_ 100 ControlEncodingReq 0;
BA_ "GenSigTimeoutTime_ECM" SG_ 100 ControlEncodingReq 0;
BA_ "GenSigTimeoutTime_EPS" SG_ 100 ControlEncodingReq 0;
BA_ "GenSigTimeoutTime_IPC" SG_ 100 ControlEncodingReq 0;
BA_ "GenSigTimeoutTime_MTA" SG_ 100 ControlEncodingReq 0;
BA_ "GenSigTimeoutTime_ORC" SG_ 100 ControlEncodingReq 0;
BA_ "GenSigTimeoutTime_PAM" SG_ 100 ControlEncodingReq 0;
BA_ "GenSigTimeoutTime_BSM" SG_ 100 f1_1 0;
BA_ "GenSigTimeoutTime_DIAG_TEST" SG_ 100 f1_1 0;
BA_ "GenSigTimeoutTime_ECM" SG_ 100 f1_1 0;
BA_ "GenSigTimeoutTime_EPS" SG_ 100 f1_1 0;
BA_ "GenSigTimeoutTime_IPC" SG_ 100 f1_1 0;
BA_ "GenSigTimeoutTime_MTA" SG_ 100 f1_1 0;
BA_ "GenSigTimeoutTime_ORC" SG_ 100 f1_1 0;
BA_ "GenSigTimeoutTime_PAM" SG_ 100 f1_1 0;
BA_ "GenSigTimeoutTime_BSM" SG_ 100 f1_2 0;
BA_ "GenSigTimeoutTime_DIAG_TEST" SG_ 100 f1_2 0;
BA_ "GenSigTimeoutTime_ECM" SG_ 100 f1_2 0;
BA_ "GenSigTimeoutTime_EPS" SG_ 100 f1_2 0;
BA_ "GenSigTimeoutTime_IPC" SG_ 100 f1_2 0;
BA_ "GenSigTimeoutTime_MTA" SG_ 100 f1_2 0;
BA_ "GenSigTimeoutTime_ORC" SG_ 100 f1_2 0;
BA_ "GenSigTimeoutTime_PAM" SG_ 100 f1_2 0;
BA_ "GenSigTimeoutTime_BSM" SG_ 100 rnd_1 0;
BA_ "GenSigTimeoutTime_DIAG_TEST" SG_ 100 rnd_1 0;
BA_ "GenSigTimeoutTime_ECM" SG_ 100 rnd_1 0;
BA_ "GenSigTimeoutTime_EPS" SG_ 100 rnd_1 0;
BA_ "GenSigTimeoutTime_IPC" SG_ 100 rnd_1 0;
BA_ "GenSigTimeoutTime_MTA" SG_ 100 rnd_1 0;
BA_ "GenSigTimeoutTime_ORC" SG_ 100 rnd_1 0;
BA_ "GenSigTimeoutTime_PAM" SG_ 100 rnd_1 0;
BA_ "GenSigTimeoutTime_BSM" SG_ 100 rnd_2 0;
BA_ "GenSigTimeoutTime_DIAG_TEST" SG_ 100 rnd_2 0;
BA_ "GenSigTimeoutTime_ECM" SG_ 100 rnd_2 0;
BA_ "GenSigTimeoutTime_EPS" SG_ 100 rnd_2 0;
BA_ "GenSigTimeoutTime_IPC" SG_ 100 rnd_2 0;
BA_ "GenSigTimeoutTime_MTA" SG_ 100 rnd_2 0;
BA_ "GenSigTimeoutTime_ORC" SG_ 100 rnd_2 0;
BA_ "GenSigTimeoutTime_PAM" SG_ 100 rnd_2 0;
BA_ "GenSigTimeoutTime_BSM" SG_ 100 rnd_3 0;
BA_ "GenSigTimeoutTime_DIAG_TEST" SG_ 100 rnd_3 0;
BA_ "GenSigTimeoutTime_ECM" SG_ 100 rnd_3 0;
BA_ "GenSigTimeoutTime_EPS" SG_ 100 rnd_3 0;
BA_ "GenSigTimeoutTime_IPC" SG_ 100 rnd_3 0;
BA_ "GenSigTimeoutTime_MTA" SG_ 100 rnd_3 0;
BA_ "GenSigTimeoutTime_ORC" SG_ 100 rnd_3 0;
BA_ "GenSigTimeoutTime_PAM" SG_ 100 rnd_3 0;
BA_ "GenSigTimeoutTime_BSM" SG_ 100 rnd_4 0;
BA_ "GenSigTimeoutTime_DIAG_TEST" SG_ 100 rnd_4 0;
BA_ "GenSigTimeoutTime_ECM" SG_ 100 rnd_4 0;
BA_ "GenSigTimeoutTime_EPS" SG_ 100 rnd_4 0;
BA_ "GenSigTimeoutTime_IPC" SG_ 100 rnd_4 0;
BA_ "GenSigTimeoutTime_MTA" SG_ 100 rnd_4 0;
BA_ "GenSigTimeoutTime_ORC" SG_ 100 rnd_4 0;
BA_ "GenSigTimeoutTime_PAM" SG_ 100 rnd_4 0;
BA_ "GenSigSendType" SG_ 104 ControlEncodingRsp 1;
BA_ "GenSigTimeoutTime_BCM" SG_ 104 ControlEncodingRsp 0;
BA_ "GenSigTimeoutTime_BSM" SG_ 104 ControlEncodingRsp 0;
BA_ "GenSigTimeoutTime_DIAG_TEST" SG_ 104 ControlEncodingRsp 0;
BA_ "GenSigTimeoutTime_EPS" SG_ 104 ControlEncodingRsp 0;
BA_ "GenSigTimeoutTime_IPC" SG_ 104 ControlEncodingRsp 0;
BA_ "GenSigTimeoutTime_MTA" SG_ 104 ControlEncodingRsp 0;
BA_ "GenSigTimeoutTime_ORC" SG_ 104 ControlEncodingRsp 0;
BA_ "GenSigTimeoutTime_PAM" SG_ 104 ControlEncodingRsp 0;
BA_ "GenSigTimeoutTime_BCM" SG_ 104 MKKey_3 0;
BA_ "GenSigTimeoutTime_BSM" SG_ 104 MKKey_3 0;
BA_ "GenSigTimeoutTime_DIAG_TEST" SG_ 104 MKKey_3 0;
BA_ "GenSigTimeoutTime_EPS" SG_ 104 MKKey_3 0;
BA_ "GenSigTimeoutTime_IPC" SG_ 104 MKKey_3 0;
BA_ "GenSigTimeoutTime_MTA" SG_ 104 MKKey_3 0;
BA_ "GenSigTimeoutTime_ORC" SG_ 104 MKKey_3 0;
BA_ "GenSigTimeoutTime_PAM" SG_ 104 MKKey_3 0;
BA_ "GenSigTimeoutTime_BCM" SG_ 104 MKKey_4 0;
BA_ "GenSigTimeoutTime_BSM" SG_ 104 MKKey_4 0;
BA_ "GenSigTimeoutTime_DIAG_TEST" SG_ 104 MKKey_4 0;
BA_ "GenSigTimeoutTime_EPS" SG_ 104 MKKey_4 0;
BA_ "GenSigTimeoutTime_IPC" SG_ 104 MKKey_4 0;
BA_ "GenSigTimeoutTime_MTA" SG_ 104 MKKey_4 0;
BA_ "GenSigTimeoutTime_ORC" SG_ 104 MKKey_4 0;
BA_ "GenSigTimeoutTime_PAM" SG_ 104 MKKey_4 0;
BA_ "GenSigTimeoutTime_BCM" SG_ 104 MKKey_5 0;
BA_ "GenSigTimeoutTime_BSM" SG_ 104 MKKey_5 0;
BA_ "GenSigTimeoutTime_DIAG_TEST" SG_ 104 MKKey_5 0;
BA_ "GenSigTimeoutTime_EPS" SG_ 104 MKKey_5 0;
BA_ "GenSigTimeoutTime_IPC" SG_ 104 MKKey_5 0;
BA_ "GenSigTimeoutTime_MTA" SG_ 104 MKKey_5 0;
BA_ "GenSigTimeoutTime_ORC" SG_ 104 MKKey_5 0;
BA_ "GenSigTimeoutTime_PAM" SG_ 104 MKKey_5 0;
BA_ "GenSigTimeoutTime_BCM" SG_ 104 MKKey_6 0;
BA_ "GenSigTimeoutTime_BSM" SG_ 104 MKKey_6 0;
BA_ "GenSigTimeoutTime_DIAG_TEST" SG_ 104 MKKey_6 0;
BA_ "GenSigTimeoutTime_EPS" SG_ 104 MKKey_6 0;
BA_ "GenSigTimeoutTime_IPC" SG_ 104 MKKey_6 0;
BA_ "GenSigTimeoutTime_MTA" SG_ 104 MKKey_6 0;
BA_ "GenSigTimeoutTime_ORC" SG_ 104 MKKey_6 0;
BA_ "GenSigTimeoutTime_PAM" SG_ 104 MKKey_6 0;
BA_ "GenSigTimeoutTime_BCM" SG_ 104 MKKey1org21 0;
BA_ "GenSigTimeoutTime_BSM" SG_ 104 MKKey1org21 0;
BA_ "GenSigTimeoutTime_DIAG_TEST" SG_ 104 MKKey1org21 0;
BA_ "GenSigTimeoutTime_EPS" SG_ 104 MKKey1org21 0;
BA_ "GenSigTimeoutTime_IPC" SG_ 104 MKKey1org21 0;
BA_ "GenSigTimeoutTime_MTA" SG_ 104 MKKey1org21 0;
BA_ "GenSigTimeoutTime_ORC" SG_ 104 MKKey1org21 0;
BA_ "GenSigTimeoutTime_PAM" SG_ 104 MKKey1org21 0;
BA_ "GenSigTimeoutTime_BCM" SG_ 104 MKKey2org22 0;
BA_ "GenSigTimeoutTime_BSM" SG_ 104 MKKey2org22 0;
BA_ "GenSigTimeoutTime_DIAG_TEST" SG_ 104 MKKey2org22 0;
BA_ "GenSigTimeoutTime_EPS" SG_ 104 MKKey2org22 0;
BA_ "GenSigTimeoutTime_IPC" SG_ 104 MKKey2org22 0;
BA_ "GenSigTimeoutTime_MTA" SG_ 104 MKKey2org22 0;
BA_ "GenSigTimeoutTime_ORC" SG_ 104 MKKey2org22 0;
BA_ "GenSigTimeoutTime_PAM" SG_ 104 MKKey2org22 0;
BA_ "GenSigTimeoutTime_BCM" SG_ 346 IMPACT_A 0;
BA_ "GenSigTimeoutTime_BSM" SG_ 346 IMPACT_A 0;
BA_ "GenSigTimeoutTime_DIAG_TEST" SG_ 346 IMPACT_A 0;
BA_ "GenSigTimeoutTime_ECM" SG_ 346 IMPACT_A 0;
BA_ "GenSigTimeoutTime_EPS" SG_ 346 IMPACT_A 0;
BA_ "GenSigTimeoutTime_IPC" SG_ 346 IMPACT_A 0;
BA_ "GenSigTimeoutTime_MTA" SG_ 346 IMPACT_A 0;
BA_ "GenSigTimeoutTime_ORC" SG_ 346 IMPACT_A 0;
BA_ "GenSigTimeoutTime_PAM" SG_ 346 IMPACT_A 0;
BA_ "GenSigTimeoutTime_BCM" SG_ 346 IMPACT_B 0;
BA_ "GenSigTimeoutTime_BSM" SG_ 346 IMPACT_B 0;
BA_ "GenSigTimeoutTime_DIAG_TEST" SG_ 346 IMPACT_B 0;
BA_ "GenSigTimeoutTime_ECM" SG_ 346 IMPACT_B 0;
BA_ "GenSigTimeoutTime_EPS" SG_ 346 IMPACT_B 0;
BA_ "GenSigTimeoutTime_IPC" SG_ 346 IMPACT_B 0;
BA_ "GenSigTimeoutTime_MTA" SG_ 346 IMPACT_B 0;
BA_ "GenSigTimeoutTime_ORC" SG_ 346 IMPACT_B 0;
BA_ "GenSigTimeoutTime_PAM" SG_ 346 IMPACT_B 0;
BA_ "GenSigTimeoutTime_BCM" SG_ 346 IMPACT_C 0;
BA_ "GenSigTimeoutTime_BSM" SG_ 346 IMPACT_C 0;
BA_ "GenSigTimeoutTime_DIAG_TEST" SG_ 346 IMPACT_C 0;
BA_ "GenSigTimeoutTime_ECM" SG_ 346 IMPACT_C 0;
BA_ "GenSigTimeoutTime_EPS" SG_ 346 IMPACT_C 0;
BA_ "GenSigTimeoutTime_IPC" SG_ 346 IMPACT_C 0;
BA_ "GenSigTimeoutTime_MTA" SG_ 346 IMPACT_C 0;
BA_ "GenSigTimeoutTime_ORC" SG_ 346 IMPACT_C 0;
BA_ "GenSigTimeoutTime_PAM" SG_ 346 IMPACT_C 0;
BA_ "GenSigTimeoutTime_BCM" SG_ 346 IMPACT_E 0;
BA_ "GenSigTimeoutTime_BSM" SG_ 346 IMPACT_E 0;
BA_ "GenSigTimeoutTime_DIAG_TEST" SG_ 346 IMPACT_E 0;
BA_ "GenSigTimeoutTime_ECM" SG_ 346 IMPACT_E 0;
BA_ "GenSigTimeoutTime_EPS" SG_ 346 IMPACT_E 0;
BA_ "GenSigTimeoutTime_IPC" SG_ 346 IMPACT_E 0;
BA_ "GenSigTimeoutTime_MTA" SG_ 346 IMPACT_E 0;
BA_ "GenSigTimeoutTime_ORC" SG_ 346 IMPACT_E 0;
BA_ "GenSigTimeoutTime_PAM" SG_ 346 IMPACT_E 0;
BA_ "GenSigTimeoutTime_BCM" SG_ 346 IMPACT_K 0;
BA_ "GenSigTimeoutTime_BSM" SG_ 346 IMPACT_K 0;
BA_ "GenSigTimeoutTime_DIAG_TEST" SG_ 346 IMPACT_K 0;
BA_ "GenSigTimeoutTime_ECM" SG_ 346 IMPACT_K 0;
BA_ "GenSigTimeoutTime_EPS" SG_ 346 IMPACT_K 0;
BA_ "GenSigTimeoutTime_IPC" SG_ 346 IMPACT_K 0;
BA_ "GenSigTimeoutTime_MTA" SG_ 346 IMPACT_K 0;
BA_ "GenSigTimeoutTime_ORC" SG_ 346 IMPACT_K 0;
BA_ "GenSigTimeoutTime_PAM" SG_ 346 IMPACT_K 0;
BA_ "GenSigTimeoutTime_BCM" SG_ 346 IMPACT_M 0;
BA_ "GenSigTimeoutTime_BSM" SG_ 346 IMPACT_M 0;
BA_ "GenSigTimeoutTime_DIAG_TEST" SG_ 346 IMPACT_M 0;
BA_ "GenSigTimeoutTime_ECM" SG_ 346 IMPACT_M 0;
BA_ "GenSigTimeoutTime_EPS" SG_ 346 IMPACT_M 0;
BA_ "GenSigTimeoutTime_IPC" SG_ 346 IMPACT_M 0;
BA_ "GenSigTimeoutTime_MTA" SG_ 346 IMPACT_M 0;
BA_ "GenSigTimeoutTime_ORC" SG_ 346 IMPACT_M 0;
BA_ "GenSigTimeoutTime_PAM" SG_ 346 IMPACT_M 0;
BA_ "GenSigSendType" SG_ 346 IMPACTCommand 5;
BA_ "GenSigTimeoutTime_BSM" SG_ 346 IMPACTCommand 0;
BA_ "GenSigTimeoutTime_DIAG_TEST" SG_ 346 IMPACTCommand 0;
BA_ "GenSigTimeoutTime_ECM" SG_ 346 IMPACTCommand 0;
BA_ "GenSigTimeoutTime_EPS" SG_ 346 IMPACTCommand 0;
BA_ "GenSigTimeoutTime_IPC" SG_ 346 IMPACTCommand 0;
BA_ "GenSigTimeoutTime_MTA" SG_ 346 IMPACTCommand 0;
BA_ "GenSigTimeoutTime_ORC" SG_ 346 IMPACTCommand 0;
BA_ "GenSigTimeoutTime_PAM" SG_ 346 IMPACTCommand 0;
BA_ "GenSigStartValue" SG_ 346 IMPACTConfirm 1;
BA_ "GenSigInactiveValue" SG_ 346 IMPACTConfirm 1;
BA_ "GenSigSendType" SG_ 346 IMPACTConfirm 5;
BA_ "GenSigTimeoutTime_BSM" SG_ 346 IMPACTConfirm 0;
BA_ "GenSigTimeoutTime_DIAG_TEST" SG_ 346 IMPACTConfirm 0;
BA_ "GenSigTimeoutTime_ECM" SG_ 346 IMPACTConfirm 0;
BA_ "GenSigTimeoutTime_EPS" SG_ 346 IMPACTConfirm 0;
BA_ "GenSigTimeoutTime_IPC" SG_ 346 IMPACTConfirm 0;
BA_ "GenSigTimeoutTime_MTA" SG_ 346 IMPACTConfirm 0;
BA_ "GenSigTimeoutTime_ORC" SG_ 346 IMPACTConfirm 0;
BA_ "GenSigTimeoutTime_PAM" SG_ 346 IMPACTConfirm 0;
BA_ "GenSigSendType" SG_ 346 IMPACTFailSts 5;
BA_ "GenSigTimeoutTime_BSM" SG_ 346 IMPACTFailSts 0;
BA_ "GenSigTimeoutTime_DIAG_TEST" SG_ 346 IMPACTFailSts 0;
BA_ "GenSigTimeoutTime_ECM" SG_ 346 IMPACTFailSts 0;
BA_ "GenSigTimeoutTime_EPS" SG_ 346 IMPACTFailSts 0;
BA_ "GenSigTimeoutTime_IPC" SG_ 346 IMPACTFailSts 0;
BA_ "GenSigTimeoutTime_MTA" SG_ 346 IMPACTFailSts 0;
BA_ "GenSigTimeoutTime_ORC" SG_ 346 IMPACTFailSts 0;
BA_ "GenSigTimeoutTime_PAM" SG_ 346 IMPACTFailSts 0;
BA_ "GenSigTimeoutTime_BCM" SG_ 258 AutoCrankRequest 0;
BA_ "GenSigTimeoutTime_BSM" SG_ 258 AutoCrankRequest 0;
BA_ "GenSigTimeoutTime_DIAG_TEST" SG_ 258 AutoCrankRequest 0;
BA_ "GenSigTimeoutTime_ECM" SG_ 258 AutoCrankRequest 0;
BA_ "GenSigTimeoutTime_EPS" SG_ 258 AutoCrankRequest 0;
BA_ "GenSigTimeoutTime_IPC" SG_ 258 AutoCrankRequest 0;
BA_ "GenSigTimeoutTime_ORC" SG_ 258 AutoCrankRequest 0;
BA_ "GenSigTimeoutTime_PAM" SG_ 258 AutoCrankRequest 0;
BA_ "GenSigTimeoutTime_BCM" SG_ 258 CANErr 0;
BA_ "GenSigTimeoutTime_BSM" SG_ 258 CANErr 0;
BA_ "GenSigTimeoutTime_DIAG_TEST" SG_ 258 CANErr 0;
BA_ "GenSigTimeoutTime_ECM" SG_ 258 CANErr 0;
BA_ "GenSigTimeoutTime_EPS" SG_ 258 CANErr 0;
BA_ "GenSigTimeoutTime_IPC" SG_ 258 CANErr 0;
BA_ "GenSigTimeoutTime_ORC" SG_ 258 CANErr 0;
BA_ "GenSigTimeoutTime_PAM" SG_ 258 CANErr 0;
BA_ "GenSigTimeoutTime_BCM" SG_ 258 CRC_MT 0;
BA_ "GenSigTimeoutTime_BSM" SG_ 258 CRC_MT 0;
BA_ "GenSigTimeoutTime_DIAG_TEST" SG_ 258 CRC_MT 0;
BA_ "GenSigTimeoutTime_ECM" SG_ 258 CRC_MT 0;
BA_ "GenSigTimeoutTime_EPS" SG_ 258 CRC_MT 0;
BA_ "GenSigTimeoutTime_IPC" SG_ 258 CRC_MT 0;
BA_ "GenSigTimeoutTime_ORC" SG_ 258 CRC_MT 0;
BA_ "GenSigTimeoutTime_PAM" SG_ 258 CRC_MT 0;
BA_ "GenSigTimeoutTime_BCM" SG_ 258 CreepingInhibitCommand 0;
BA_ "GenSigTimeoutTime_BSM" SG_ 258 CreepingInhibitCommand 0;
BA_ "GenSigTimeoutTime_DIAG_TEST" SG_ 258 CreepingInhibitCommand 0;
BA_ "GenSigTimeoutTime_ECM" SG_ 258 CreepingInhibitCommand 0;
BA_ "GenSigTimeoutTime_EPS" SG_ 258 CreepingInhibitCommand 0;
BA_ "GenSigTimeoutTime_IPC" SG_ 258 CreepingInhibitCommand 0;
BA_ "GenSigTimeoutTime_ORC" SG_ 258 CreepingInhibitCommand 0;
BA_ "GenSigTimeoutTime_PAM" SG_ 258 CreepingInhibitCommand 0;
BA_ "GenSigTimeoutTime_BCM" SG_ 258 EngineIdleRefSpeed 0;
BA_ "GenSigTimeoutTime_BSM" SG_ 258 EngineIdleRefSpeed 0;
BA_ "GenSigTimeoutTime_DIAG_TEST" SG_ 258 EngineIdleRefSpeed 0;
BA_ "GenSigTimeoutTime_ECM" SG_ 258 EngineIdleRefSpeed 0;
BA_ "GenSigTimeoutTime_EPS" SG_ 258 EngineIdleRefSpeed 0;
BA_ "GenSigTimeoutTime_IPC" SG_ 258 EngineIdleRefSpeed 0;
BA_ "GenSigTimeoutTime_ORC" SG_ 258 EngineIdleRefSpeed 0;
BA_ "GenSigTimeoutTime_PAM" SG_ 258 EngineIdleRefSpeed 0;
BA_ "GenSigTimeoutTime_BSM" SG_ 258 EngineWaterTemp 0;
BA_ "GenSigTimeoutTime_DIAG_TEST" SG_ 258 EngineWaterTemp 0;
BA_ "GenSigTimeoutTime_ECM" SG_ 258 EngineWaterTemp 0;
BA_ "GenSigTimeoutTime_EPS" SG_ 258 EngineWaterTemp 0;
BA_ "GenSigTimeoutTime_IPC" SG_ 258 EngineWaterTemp 0;
BA_ "GenSigTimeoutTime_MTA" SG_ 258 EngineWaterTemp 0;
BA_ "GenSigTimeoutTime_ORC" SG_ 258 EngineWaterTemp 0;
BA_ "GenSigTimeoutTime_PAM" SG_ 258 EngineWaterTemp 0;
BA_ "GenSigTimeoutTime_BSM" SG_ 258 EngineWaterTempFailSts 0;
BA_ "GenSigTimeoutTime_DIAG_TEST" SG_ 258 EngineWaterTempFailSts 0;
BA_ "GenSigTimeoutTime_ECM" SG_ 258 EngineWaterTempFailSts 0;
BA_ "GenSigTimeoutTime_EPS" SG_ 258 EngineWaterTempFailSts 0;
BA_ "GenSigTimeoutTime_IPC" SG_ 258 EngineWaterTempFailSts 0;
BA_ "GenSigTimeoutTime_MTA" SG_ 258 EngineWaterTempFailSts 0;
BA_ "GenSigTimeoutTime_ORC" SG_ 258 EngineWaterTempFailSts 0;
BA_ "GenSigTimeoutTime_PAM" SG_ 258 EngineWaterTempFailSts 0;
BA_ "GenSigTimeoutTime_BCM" SG_ 258 EngTorqueTargetWONCR 0;
BA_ "GenSigTimeoutTime_BSM" SG_ 258 EngTorqueTargetWONCR 0;
BA_ "GenSigTimeoutTime_DIAG_TEST" SG_ 258 EngTorqueTargetWONCR 0;
BA_ "GenSigTimeoutTime_ECM" SG_ 258 EngTorqueTargetWONCR 0;
BA_ "GenSigTimeoutTime_EPS" SG_ 258 EngTorqueTargetWONCR 0;
BA_ "GenSigTimeoutTime_IPC" SG_ 258 EngTorqueTargetWONCR 0;
BA_ "GenSigTimeoutTime_ORC" SG_ 258 EngTorqueTargetWONCR 0;
BA_ "GenSigTimeoutTime_PAM" SG_ 258 EngTorqueTargetWONCR 0;
BA_ "GenSigTimeoutTime_BCM" SG_ 258 KickDownRequest 0;
BA_ "GenSigTimeoutTime_BSM" SG_ 258 KickDownRequest 0;
BA_ "GenSigTimeoutTime_DIAG_TEST" SG_ 258 KickDownRequest 0;
BA_ "GenSigTimeoutTime_ECM" SG_ 258 KickDownRequest 0;
BA_ "GenSigTimeoutTime_EPS" SG_ 258 KickDownRequest 0;
BA_ "GenSigTimeoutTime_IPC" SG_ 258 KickDownRequest 0;
BA_ "GenSigTimeoutTime_MTA" SG_ 258 KickDownRequest 0;
BA_ "GenSigTimeoutTime_ORC" SG_ 258 KickDownRequest 0;
BA_ "GenSigTimeoutTime_PAM" SG_ 258 KickDownRequest 0;
BA_ "GenSigTimeoutTime_BCM" SG_ 258 MessageCounter_MT 0;
BA_ "GenSigTimeoutTime_BSM" SG_ 258 MessageCounter_MT 0;
BA_ "GenSigTimeoutTime_DIAG_TEST" SG_ 258 MessageCounter_MT 0;
BA_ "GenSigTimeoutTime_ECM" SG_ 258 MessageCounter_MT 0;
BA_ "GenSigTimeoutTime_EPS" SG_ 258 MessageCounter_MT 0;
BA_ "GenSigTimeoutTime_IPC" SG_ 258 MessageCounter_MT 0;
BA_ "GenSigTimeoutTime_ORC" SG_ 258 MessageCounter_MT 0;
BA_ "GenSigTimeoutTime_PAM" SG_ 258 MessageCounter_MT 0;
BA_ "GenSigTimeoutTime_BCM" SG_ 258 Psben 0;
BA_ "GenSigTimeoutTime_BSM" SG_ 258 Psben 0;
BA_ "GenSigTimeoutTime_DIAG_TEST" SG_ 258 Psben 0;
BA_ "GenSigTimeoutTime_ECM" SG_ 258 Psben 0;
BA_ "GenSigTimeoutTime_EPS" SG_ 258 Psben 0;
BA_ "GenSigTimeoutTime_IPC" SG_ 258 Psben 0;
BA_ "GenSigTimeoutTime_MTA" SG_ 258 Psben 0;
BA_ "GenSigTimeoutTime_ORC" SG_ 258 Psben 0;
BA_ "GenSigTimeoutTime_PAM" SG_ 258 Psben 0;
BA_ "GenSigTimeoutTime_DIAG_TEST" SG_ 230 ClutchPedalAction 0;
BA_ "GenSigTimeoutTime_ECM" SG_ 230 ClutchPedalAction 0;
BA_ "GenSigTimeoutTime_EPS" SG_ 230 ClutchPedalAction 0;
BA_ "GenSigTimeoutTime_IPC" SG_ 230 ClutchPedalAction 0;
BA_ "GenSigTimeoutTime_MTA" SG_ 230 ClutchPedalAction 0;
BA_ "GenSigTimeoutTime_ORC" SG_ 230 ClutchPedalAction 0;
BA_ "GenSigTimeoutTime_PAM" SG_ 230 ClutchPedalAction 0;
BA_ "GenSigTimeoutTime_BSM" SG_ 230 CrankHold 0;
BA_ "GenSigTimeoutTime_DIAG_TEST" SG_ 230 CrankHold 0;
BA_ "GenSigTimeoutTime_ECM" SG_ 230 CrankHold 0;
BA_ "GenSigTimeoutTime_EPS" SG_ 230 CrankHold 0;
BA_ "GenSigTimeoutTime_IPC" SG_ 230 CrankHold 0;
BA_ "GenSigTimeoutTime_MTA" SG_ 230 CrankHold 0;
BA_ "GenSigTimeoutTime_ORC" SG_ 230 CrankHold 0;
BA_ "GenSigTimeoutTime_PAM" SG_ 230 CrankHold 0;
BA_ "GenSigStartValue" SG_ 230 EngineSts 3;
BA_ "GenSigTimeoutTime_DIAG_TEST" SG_ 230 EngineSts 0;
BA_ "GenSigTimeoutTime_ECM" SG_ 230 EngineSts 0;
BA_ "GenSigTimeoutTime_BCM" SG_ 230 EngineTorqueDriverReq 0;
BA_ "GenSigTimeoutTime_DIAG_TEST" SG_ 230 EngineTorqueDriverReq 0;
BA_ "GenSigTimeoutTime_ECM" SG_ 230 EngineTorqueDriverReq 0;
BA_ "GenSigTimeoutTime_EPS" SG_ 230 EngineTorqueDriverReq 0;
BA_ "GenSigTimeoutTime_IPC" SG_ 230 EngineTorqueDriverReq 0;
BA_ "GenSigTimeoutTime_ORC" SG_ 230 EngineTorqueDriverReq 0;
BA_ "GenSigTimeoutTime_PAM" SG_ 230 EngineTorqueDriverReq 0;
BA_ "GenSigTimeoutTime_BCM" SG_ 230 FeedbackASR_ESCReq 0;
BA_ "GenSigTimeoutTime_DIAG_TEST" SG_ 230 FeedbackASR_ESCReq 0;
BA_ "GenSigTimeoutTime_ECM" SG_ 230 FeedbackASR_ESCReq 0;
BA_ "GenSigTimeoutTime_EPS" SG_ 230 FeedbackASR_ESCReq 0;
BA_ "GenSigTimeoutTime_IPC" SG_ 230 FeedbackASR_ESCReq 0;
BA_ "GenSigTimeoutTime_MTA" SG_ 230 FeedbackASR_ESCReq 0;
BA_ "GenSigTimeoutTime_ORC" SG_ 230 FeedbackASR_ESCReq 0;
BA_ "GenSigTimeoutTime_PAM" SG_ 230 FeedbackASR_ESCReq 0;
BA_ "GenSigTimeoutTime_BSM" SG_ 230 FpsActuated 0;
BA_ "GenSigTimeoutTime_DIAG_TEST" SG_ 230 FpsActuated 0;
BA_ "GenSigTimeoutTime_ECM" SG_ 230 FpsActuated 0;
BA_ "GenSigTimeoutTime_EPS" SG_ 230 FpsActuated 0;
BA_ "GenSigTimeoutTime_MTA" SG_ 230 FpsActuated 0;
BA_ "GenSigTimeoutTime_ORC" SG_ 230 FpsActuated 0;
BA_ "GenSigTimeoutTime_PAM" SG_ 230 FpsActuated 0;
BA_ "GenSigTimeoutTime_BSM" SG_ 230 FpsNotActuable 0;
BA_ "GenSigTimeoutTime_DIAG_TEST" SG_ 230 FpsNotActuable 0;
BA_ "GenSigTimeoutTime_ECM" SG_ 230 FpsNotActuable 0;
BA_ "GenSigTimeoutTime_EPS" SG_ 230 FpsNotActuable 0;
BA_ "GenSigTimeoutTime_IPC" SG_ 230 FpsNotActuable 0;
BA_ "GenSigTimeoutTime_MTA" SG_ 230 FpsNotActuable 0;
BA_ "GenSigTimeoutTime_ORC" SG_ 230 FpsNotActuable 0;
BA_ "GenSigTimeoutTime_PAM" SG_ 230 FpsNotActuable 0;
BA_ "GenSigTimeoutTime_BCM" SG_ 230 GasPedalPosition 0;
BA_ "GenSigTimeoutTime_DIAG_TEST" SG_ 230 GasPedalPosition 0;
BA_ "GenSigTimeoutTime_ECM" SG_ 230 GasPedalPosition 0;
BA_ "GenSigTimeoutTime_EPS" SG_ 230 GasPedalPosition 0;
BA_ "GenSigTimeoutTime_IPC" SG_ 230 GasPedalPosition 0;
BA_ "GenSigTimeoutTime_ORC" SG_ 230 GasPedalPosition 0;
BA_ "GenSigTimeoutTime_PAM" SG_ 230 GasPedalPosition 0;
BA_ "GenSigTimeoutTime_BCM" SG_ 230 GasPedalPositionFailSts 0;
BA_ "GenSigTimeoutTime_DIAG_TEST" SG_ 230 GasPedalPositionFailSts 0;
BA_ "GenSigTimeoutTime_ECM" SG_ 230 GasPedalPositionFailSts 0;
BA_ "GenSigTimeoutTime_EPS" SG_ 230 GasPedalPositionFailSts 0;
BA_ "GenSigTimeoutTime_IPC" SG_ 230 GasPedalPositionFailSts 0;
BA_ "GenSigTimeoutTime_ORC" SG_ 230 GasPedalPositionFailSts 0;
BA_ "GenSigTimeoutTime_PAM" SG_ 230 GasPedalPositionFailSts 0;
BA_ "GenSigTimeoutTime_BCM" SG_ 230 MaxEngineTorque 0;
BA_ "GenSigTimeoutTime_BSM" SG_ 230 MaxEngineTorque 0;
BA_ "GenSigTimeoutTime_DIAG_TEST" SG_ 230 MaxEngineTorque 0;
BA_ "GenSigTimeoutTime_ECM" SG_ 230 MaxEngineTorque 0;
BA_ "GenSigTimeoutTime_EPS" SG_ 230 MaxEngineTorque 0;
BA_ "GenSigTimeoutTime_IPC" SG_ 230 MaxEngineTorque 0;
BA_ "GenSigTimeoutTime_ORC" SG_ 230 MaxEngineTorque 0;
BA_ "GenSigTimeoutTime_PAM" SG_ 230 MaxEngineTorque 0;
BA_ "GenSigTimeoutTime_DIAG_TEST" SG_ 230 ReverseGearSts 0;
BA_ "GenSigTimeoutTime_ECM" SG_ 230 ReverseGearSts 0;
BA_ "GenSigTimeoutTime_EPS" SG_ 230 ReverseGearSts 0;
BA_ "GenSigTimeoutTime_MTA" SG_ 230 ReverseGearSts 0;
BA_ "GenSigTimeoutTime_ORC" SG_ 230 ReverseGearSts 0;
BA_ "GenSigTimeoutTime_BSM" SG_ 230 StartRelayBCMCmd 0;
BA_ "GenSigTimeoutTime_DIAG_TEST" SG_ 230 StartRelayBCMCmd 0;
BA_ "GenSigTimeoutTime_ECM" SG_ 230 StartRelayBCMCmd 0;
BA_ "GenSigTimeoutTime_EPS" SG_ 230 StartRelayBCMCmd 0;
BA_ "GenSigTimeoutTime_IPC" SG_ 230 StartRelayBCMCmd 0;
BA_ "GenSigTimeoutTime_MTA" SG_ 230 StartRelayBCMCmd 0;
BA_ "GenSigTimeoutTime_ORC" SG_ 230 StartRelayBCMCmd 0;
BA_ "GenSigTimeoutTime_PAM" SG_ 230 StartRelayBCMCmd 0;
BA_ "GenSigTimeoutTime_BCM" SG_ 230 WaitToStartSts 0;
BA_ "GenSigTimeoutTime_BSM" SG_ 230 WaitToStartSts 0;
BA_ "GenSigTimeoutTime_DIAG_TEST" SG_ 230 WaitToStartSts 0;
BA_ "GenSigTimeoutTime_ECM" SG_ 230 WaitToStartSts 0;
BA_ "GenSigTimeoutTime_EPS" SG_ 230 WaitToStartSts 0;
BA_ "GenSigTimeoutTime_MTA" SG_ 230 WaitToStartSts 0;
BA_ "GenSigTimeoutTime_ORC" SG_ 230 WaitToStartSts 0;
BA_ "GenSigTimeoutTime_PAM" SG_ 230 WaitToStartSts 0;
BA_ "GenSigTimeoutTime_BCM" SG_ 226 EngineFrictionTorque 0;
BA_ "GenSigTimeoutTime_DIAG_TEST" SG_ 226 EngineFrictionTorque 0;
BA_ "GenSigTimeoutTime_ECM" SG_ 226 EngineFrictionTorque 0;
BA_ "GenSigTimeoutTime_EPS" SG_ 226 EngineFrictionTorque 0;
BA_ "GenSigTimeoutTime_IPC" SG_ 226 EngineFrictionTorque 0;
BA_ "GenSigTimeoutTime_ORC" SG_ 226 EngineFrictionTorque 0;
BA_ "GenSigTimeoutTime_PAM" SG_ 226 EngineFrictionTorque 0;
BA_ "GenSigTimeoutTime_DIAG_TEST" SG_ 226 EngineSpeed 0;
BA_ "GenSigTimeoutTime_ECM" SG_ 226 EngineSpeed 0;
BA_ "GenSigTimeoutTime_EPS" SG_ 226 EngineSpeed 0;
BA_ "GenSigTimeoutTime_ORC" SG_ 226 EngineSpeed 0;
BA_ "GenSigTimeoutTime_PAM" SG_ 226 EngineSpeed 0;
BA_ "GenSigTimeoutTime_DIAG_TEST" SG_ 226 EngineSpeedFailSts 0;
BA_ "GenSigTimeoutTime_ECM" SG_ 226 EngineSpeedFailSts 0;
BA_ "GenSigTimeoutTime_EPS" SG_ 226 EngineSpeedFailSts 0;
BA_ "GenSigTimeoutTime_MTA" SG_ 226 EngineSpeedFailSts 0;
BA_ "GenSigTimeoutTime_ORC" SG_ 226 EngineSpeedFailSts 0;
BA_ "GenSigTimeoutTime_PAM" SG_ 226 EngineSpeedFailSts 0;
BA_ "GenSigStartValue" SG_ 226 EngineTorque 2047;
BA_ "GenSigTimeoutTime_BCM" SG_ 226 EngineTorque 0;
BA_ "GenSigTimeoutTime_DIAG_TEST" SG_ 226 EngineTorque 0;
BA_ "GenSigTimeoutTime_ECM" SG_ 226 EngineTorque 0;
BA_ "GenSigTimeoutTime_EPS" SG_ 226 EngineTorque 0;
BA_ "GenSigTimeoutTime_IPC" SG_ 226 EngineTorque 0;
BA_ "GenSigTimeoutTime_ORC" SG_ 226 EngineTorque 0;
BA_ "GenSigTimeoutTime_PAM" SG_ 226 EngineTorque 0;
BA_ "GenSigTimeoutTime_BCM" SG_ 226 GasPedalAct 0;
BA_ "GenSigTimeoutTime_BSM" SG_ 226 GasPedalAct 0;
BA_ "GenSigTimeoutTime_DIAG_TEST" SG_ 226 GasPedalAct 0;
BA_ "GenSigTimeoutTime_ECM" SG_ 226 GasPedalAct 0;
BA_ "GenSigTimeoutTime_EPS" SG_ 226 GasPedalAct 0;
BA_ "GenSigTimeoutTime_IPC" SG_ 226 GasPedalAct 0;
BA_ "GenSigTimeoutTime_MTA" SG_ 226 GasPedalAct 0;
BA_ "GenSigTimeoutTime_ORC" SG_ 226 GasPedalAct 0;
BA_ "GenSigTimeoutTime_PAM" SG_ 226 GasPedalAct 0;
BA_ "GenSigTimeoutTime_BCM" SG_ 226 GasPedalGradient 0;
BA_ "GenSigTimeoutTime_BSM" SG_ 226 GasPedalGradient 0;
BA_ "GenSigTimeoutTime_DIAG_TEST" SG_ 226 GasPedalGradient 0;
BA_ "GenSigTimeoutTime_ECM" SG_ 226 GasPedalGradient 0;
BA_ "GenSigTimeoutTime_EPS" SG_ 226 GasPedalGradient 0;
BA_ "GenSigTimeoutTime_IPC" SG_ 226 GasPedalGradient 0;
BA_ "GenSigTimeoutTime_MTA" SG_ 226 GasPedalGradient 0;
BA_ "GenSigTimeoutTime_ORC" SG_ 226 GasPedalGradient 0;
BA_ "GenSigTimeoutTime_PAM" SG_ 226 GasPedalGradient 0;
VAL_ 1050 BCMSAMFailSts 0 "Fail_not_present" 1 "Fail_present" ;
VAL_ 1050 IBSFailSts 0 "Fail_not_present" 1 "Fail_present" ;
VAL_ 1050 Recalibration 0 "False" 1 "True" ;
VAL_ 250 BCMFpsCommand 0 "Do_Not_Actuate" 1 "Actuate" ;
VAL_ 250 BCMFpsConfirm 0 "Actuate" 1 "Do_Not_Actuate" ;
VAL_ 250 BCMFpsFailSts 0 "Fail_not_Present" 1 "Fail_Present" ;
VAL_ 250 BrakePedalSwitchNCSts 0 "Not_Active" 1 "Active" ;
VAL_ 250 BrakePedalSwitchNOSts 0 "Not_Active" 1 "Active" ;
VAL_ 250 CrankRequestSts 0 "Not_Active" 1 "Active" ;
VAL_ 250 OperationalModeSts 0 "Initialization" 1 "Ignition_Off_WithoutKey" 2 "Ignition_Off" 3 "Ignition_Acc" 4 "Ignition_On" 5 "Ignition_Pre_Start" 6 "Ignition_Start" 7 "Ignition_Cranking" 8 "Ignition_On_EngOn" 9 "Ignition_Pre_Acc" 10 "Ignition_Pre_Off" 11 "Automatic_Cranking" 12 "Automatic_Stop" 13 "Key_Authenticated" 14 "Not_Used" 15 "SNA" ;
VAL_ 250 StartRelayBCMFault 0 "Not_Present" 1 "Present" ;
VAL_ 250 StartRelayBCMSts 0 "OFF" 1 "ON" ;
VAL_ 254 InternalError_BSM 0 "No_int_processing_error_detected" 1 "Int_processing_error_detected" ;
VAL_ 254 LatAcceleration_BSM 4095 "SNA" ;
VAL_ 254 LatAccelerationFailSts_BSM 0 "Fail_Not_Present" 1 "Fail_Present" ;
VAL_ 254 LongAcceleration_BSM 4095 "SNA" ;
VAL_ 254 LongAccelerationFailSts_BSM 0 "Fail_Not_Present" 1 "Fail_Present" ;
VAL_ 254 YawRate_BSM 4095 "SNA" ;
VAL_ 254 YawRateFailSts_BSM 0 "Fail_Not_Present" 1 "Fail_Present" ;
VAL_ 242 ABSActive 0 "Not_active" 1 "Active" ;
VAL_ 242 BSMShiftInterference 0 "Shift_allowed" 1 "Shift_not_allowed" 3 "SNA" ;
VAL_ 242 ESCActive 0 "Not_active" 1 "Active" ;
VAL_ 242 HillHolderActive 0 "Not_Active" 1 "Active" ;
VAL_ 242 MasterCylinderPressure 1023 "SNA" ;
VAL_ 242 TorqueIncrease 0 "Not_Active" 1 "Active" ;
VAL_ 242 TorqueReduct 0 "Not_Active" 1 "Active" ;
VAL_ 242 TorqueRequest 2047 "SNA" ;
VAL_ 242 VehicleSpeedVSOSig 8191 "SNA" ;
VAL_ 242 VehicleSpeedVSOSigFailSts 0 "Fail_not_present" 1 "Fail_present" ;
VAL_ 274 BrakeInterventionSts 0 "No_active_brake_intervention" 1 "Active_brake_intervention" ;
VAL_ 274 HBAActive 0 "Not_Active" 1 "Active" ;
VAL_ 274 MuSplit 0 "MuSplitOFF" 1 "MuSplitON" 3 "SNA" ;
VAL_ 274 OverSteering 63 "SNA" ;
VAL_ 274 UnderSteering 63 "SNA" ;
VAL_ 222 ElectricSteeringFailSts 0 "Fail_Not_Present" 1 "Fail_Present" ;
VAL_ 222 LwsAngle 65535 "SNA" ;
VAL_ 222 LwsAngleType 0 "Absolute" 1 "Relative" 3 "SNA" ;
VAL_ 222 LwsCalibration 0 "Not_calibrated" 1 "Calibrated" ;
VAL_ 222 LWSFailSts 0 "Fail_not_Present" 1 "Fail_Present_Ignition_Latched" 2 "Fail_Present_Recoverable" 3 "Fail_Present_Battery_Disconnection" ;
VAL_ 222 LwsSpeed 4095 "SNA" ;
VAL_ 222 SteeringLoad 0 "Above_Threshold" 1 "Below_Threshold" ;
VAL_ 100 ControlEncodingReq 5 "ControlEncoding_ENQ" 6 "ControlEncoding_ACK" 21 "ControlEncoding_NACK" 132 "ControlEncoding_EOTp" 133 "ControlEncoding_ENQp" 134 "ControlEncoding_ACK1p" 135 "ControlEncoding_ACK2p" ;
VAL_ 100 f1_1 0 "Val1_f1_1" 81 "Val5_f1_1" 119 "Val2_f1_1" 145 "Val3_f1_1" 159 "Val4_f1_1" ;
VAL_ 100 f1_2 0 "Val1_f1_2" 5 "Val2_f1_2" 13 "Val4_f1_2" 14 "Val3_f1_2" 15 "Val5_f1_2" ;
VAL_ 100 rnd_1 0 "Val1_rnd_1" 58 "Val2_rnd_1" 59 "Val3_rnd_1" 60 "Val4_rnd_1" 61 "Val5_rnd_1" 62 "Val6_rnd_1" 63 "Val7_rnd_1" 64 "Val8_rnd_1" 65 "Val9_rnd_1" 66 "ValA_rnd_1" 67 "ValB_rnd_1" 68 "ValC_rnd_1" 69 "ValD_rnd_1" 70 "ValE_rnd_1" 71 "ValF_rnd_1" ;
VAL_ 100 rnd_2 0 "Val1_rnd_2" 26 "Val3_rnd_2" 43 "Val5_rnd_2" 79 "Val2_rnd_2" 168 "Val4_rnd_2" ;
VAL_ 100 rnd_3 0 "Val1_rnd_3" 19 "Val3_rnd_3" 21 "Val5_rnd_3" 32 "Val4_rnd_3" 129 "Val2_rnd_3" ;
VAL_ 100 rnd_4 0 "Val1_rnd_4" 170 "Val5_rnd_4" 203 "Val2_rnd_4" 221 "Val3_rnd_4" 238 "Val4_rnd_4" ;
VAL_ 104 MKKey_3 36 "FIX__MKKey_3" ;
VAL_ 104 MKKey_4 214 "FIX__MKKey_4" ;
VAL_ 104 MKKey_5 1 "FIX__MKKey_5" ;
VAL_ 104 MKKey_6 77 "FIX__MKKey_6" ;
VAL_ 104 MKKey1org21 84 "FIX__MKKey_1" ;
VAL_ 104 MKKey2org22 85 "FIX__MKKey_2" ;
VAL_ 346 IMPACT_A 0 "Do_Not_Actuate" 1 "Actuate" ;
VAL_ 346 IMPACT_B 0 "Do_Not_Actuate" 1 "Actuate" ;
VAL_ 346 IMPACT_C 0 "Do_Not_Actuate" 1 "Actuate" ;
VAL_ 346 IMPACT_E 0 "Do_Not_Actuate" 1 "Actuate" ;
VAL_ 346 IMPACT_K 0 "Do_Not_Actuate" 1 "Actuate" ;
VAL_ 346 IMPACT_M 0 "Do_Not_Actuate" 1 "Actuate" ;
VAL_ 346 IMPACTCommand 0 "Do_Not_Actuate" 1 "Actuate" ;
VAL_ 346 IMPACTConfirm 0 "Actuate" 1 "Do_Not_Actuate" ;
VAL_ 346 IMPACTFailSts 0 "Fail_Not_Present" 1 "Fail_Present" ;
VAL_ 258 AutoCrankRequest 0 "Not_Active" 1 "Active" ;
VAL_ 258 CANErr 1 "NoCanMessage" 2 "UnplausibleMessage" 4 "UnplausibleCommand" 8 "NotUsed" ;
VAL_ 258 CreepingInhibitCommand 0 "Not_Active" 1 "Active" ;
VAL_ 258 EngineIdleRefSpeed 4095 "SNA" ;
VAL_ 258 EngineWaterTemp 255 "SNA" ;
VAL_ 258 EngineWaterTempFailSts 0 "Fail_Not_Present" 1 "Fail_Present" ;
VAL_ 258 EngTorqueTargetWONCR 2047 "SNA" ;
VAL_ 258 KickDownRequest 0 "No_kd_request" 1 "Kd_request" ;
VAL_ 258 Psben 0 "Not_Active" 1 "Active" ;
VAL_ 230 ClutchPedalAction 0 "Not_Active" 1 "Active" ;
VAL_ 230 CrankHold 0 "Not_Active" 1 "Active" ;
VAL_ 230 EngineSts 0 "Engine_Off" 1 "Engine_Cranking" 2 "Engine_On" 3 "SNA" ;
VAL_ 230 EngineTorqueDriverReq 2047 "SNA" ;
VAL_ 230 FeedbackASR_ESCReq 0 "TorqueReq_ASR_ESCValid" 1 "TorqueReq_ASR_ESCNot_Valid" ;
VAL_ 230 FpsActuated 0 "Not_Actuated" 1 "Actuated" ;
VAL_ 230 FpsNotActuable 0 "FPS_Actuable" 1 "FPS_Not_Actuable" ;
VAL_ 230 GasPedalPosition 255 "SNA" ;
VAL_ 230 GasPedalPositionFailSts 0 "Fail_not_present" 1 "Fail_present" ;
VAL_ 230 MaxEngineTorque 2047 "SNA" ;
VAL_ 230 ReverseGearSts 0 "Not_Inserted" 1 "Inserted" 2 "Not_Used" 3 "SNA" ;
VAL_ 230 StartRelayBCMCmd 0 "Not_Action" 1 "Action" ;
VAL_ 230 WaitToStartSts 0 "Not_Active" 1 "Active" ;
VAL_ 226 EngineFrictionTorque 511 "SNA" ;
VAL_ 226 EngineSpeed 16383 "SNA" ;
VAL_ 226 EngineSpeedFailSts 0 "Fail_not_present" 1 "Fail_present" ;
VAL_ 226 EngineTorque 2047 "SNA" ;
VAL_ 226 GasPedalAct 0 "Not_active" 1 "Active" ;
VAL_ 226 GasPedalGradient 255 "SNA" ;
